VERSION "dbc-export 1 2025.20.8"

NS_ :

BS_:

BU_: ADSP APB APP APS APSB BB BMS CC CMP CMPD CP DAS DI DIF DIR DPB EPAS3P EPAS3S EPASTP EPASTS EPBL EPBR ESP EVSE FC GTW HCML HCMR HVP IBST ICR IDB LS OCS1P PARK PCS PM PMF PMR PNCD PTC RADC RCM RCM2 RCM3 RCU SCCM SCM SCS SDCR TAS TCU TPMS TRCM UI UIS UMC USM VC VCFRONT VCLEFT VCRIGHT VCSEC VEH

BO_ 1480 EPBL_alertLog: 8 EPBL
 SG_ EPBL_alertID M : 0|9@1+ (1,0) [0|511] "" Vector__XXX
 SG_ EPBL_alertState : 15|1@1+ (1,0) [0|1] "" Vector__XXX
 SG_ EPBL_a001_InternalWatchdog m1 : 16|1@1+ (1,0) [0|1] "" Vector__XXX
 SG_ EPBL_a002_CPUUndervoltage m2 : 16|1@1+ (1,0) [0|1] "" Vector__XXX
 SG_ EPBL_a002_PowerOnReset m2 : 17|1@1+ (1,0) [0|1] "" Vector__XXX
 SG_ EPBL_a015_NVMMMemOverflow m15 : 16|1@1+ (1,0) [0|1] "" Vector__XXX
 SG_ EPBL_a015_NVMMFilesystemError m15 : 17|1@1+ (1,0) [0|1] "" Vector__XXX
 SG_ EPBL_a015_NVMMRecordIDError m15 : 18|1@1+ (1,0) [0|1] "" Vector__XXX
 SG_ EPBL_a057_VEH_cpControl m57 : 16|1@1+ (1,0) [0|1] "" Vector__XXX
 SG_ EPBL_a059_voltageDrop m59 : 16|12@1+ (0.005443676,0) [0|22.29185322] "" Vector__XXX
 SG_ EPBL_a059_resistanceEstimate m59 : 28|12@1+ (0.00244,0) [0|9.9918] "" Vector__XXX
 SG_ EPBL_a059_current m59 : 40|12@1+ (0.05,0) [0|204.75] "" Vector__XXX
 SG_ EPBL_a063_switchChannel m63 : 16|8@1+ (1,0) [0|255] "" Vector__XXX
 SG_ EPBL_a063_switchType m63 : 24|8@1+ (1,0) [0|255] "" Vector__XXX
 SG_ EPBL_a063_ADCVoltage m63 : 32|8@1+ (0.025,0) [0|6.375] "" Vector__XXX
 SG_ EPBL_a063_disconnected m63 : 40|1@1+ (1,0) [0|1] "" Vector__XXX
 SG_ EPBL_a063_indeterminate m63 : 41|1@1+ (1,0) [0|1] "" Vector__XXX
 SG_ EPBL_a063_stuckActive m63 : 42|1@1+ (1,0) [0|1] "" Vector__XXX
 SG_ EPBL_a063_faulted m63 : 43|1@1+ (1,0) [0|1] "" Vector__XXX
 SG_ EPBL_a081_VEH_defogInfoMessage m81 : 16|1@1+ (1,0) [0|1] "" Vector__XXX
 SG_ EPBL_a082_RIPC_epbPrivateState m82 : 16|1@1+ (1,0) [0|1] "" Vector__XXX
 SG_ EPBL_a082_RIPC_remoteHSD m82 : 17|1@1+ (1,0) [0|1] "" Vector__XXX
 SG_ EPBL_a082_RIPC_railStatus m82 : 18|1@1+ (1,0) [0|1] "" Vector__XXX
 SG_ EPBL_a082_RIPC_remoteMux m82 : 19|1@1+ (1,0) [0|1] "" Vector__XXX
 SG_ EPBL_a082_RIPC_remoteCurrent m82 : 20|1@1+ (1,0) [0|1] "" Vector__XXX
 SG_ EPBL_a083_LIPC_epbPrivateState m83 : 16|1@1+ (1,0) [0|1] "" Vector__XXX
 SG_ EPBL_a083_LIPC_remoteHSD m83 : 17|1@1+ (1,0) [0|1] "" Vector__XXX
 SG_ EPBL_a083_LIPC_railStatus m83 : 18|1@1+ (1,0) [0|1] "" Vector__XXX
 SG_ EPBL_a083_LIPC_HSDFaults m83 : 19|1@1+ (1,0) [0|1] "" Vector__XXX
 SG_ EPBL_a083_LIPC_remoteCurrent m83 : 20|1@1+ (1,0) [0|1] "" Vector__XXX
 SG_ EPBL_a084_CH_StatusC m84 : 16|1@1+ (1,0) [0|1] "" Vector__XXX
 SG_ EPBL_a085_PARTY_buttonStatus m85 : 16|1@1+ (1,0) [0|1] "" Vector__XXX
 SG_ EPBL_a086_VEH_LVBMS_statusHigh m86 : 16|1@1+ (1,0) [0|1] "" Vector__XXX
 SG_ EPBL_a086_VEH_LVBMS_statusLow m86 : 17|1@1+ (1,0) [0|1] "" Vector__XXX
 SG_ EPBL_a086_VEH_status m86 : 18|1@1+ (1,0) [0|1] "" Vector__XXX
 SG_ EPBL_a086_VEH_12VBatteryStatus m86 : 19|1@1+ (1,0) [0|1] "" Vector__XXX
 SG_ EPBL_a086_VEH_LVPowerState m86 : 20|1@1+ (1,0) [0|1] "" Vector__XXX
 SG_ EPBL_a086_VEH_lightStatus m86 : 21|1@1+ (1,0) [0|1] "" Vector__XXX
 SG_ EPBL_a086_VEH_systemStatus m86 : 22|1@1+ (1,0) [0|1] "" Vector__XXX
 SG_ EPBL_a086_VEH_thermalStatus m86 : 23|1@1+ (1,0) [0|1] "" Vector__XXX
 SG_ EPBL_a086_VEH_vehNm m86 : 24|1@1+ (1,0) [0|1] "" Vector__XXX
 SG_ EPBL_a087_VEH_temperature m87 : 16|1@1+ (1,0) [0|1] "" Vector__XXX
 SG_ EPBL_a087_VEH_thermalControl m87 : 17|1@1+ (1,0) [0|1] "" Vector__XXX
 SG_ EPBL_a087_VEH_torque m87 : 18|1@1+ (1,0) [0|1] "" Vector__XXX
 SG_ EPBL_a087_VEH_status m87 : 19|1@1+ (1,0) [0|1] "" Vector__XXX
 SG_ EPBL_a087_PARTY_torque m87 : 20|1@1+ (1,0) [0|1] "" Vector__XXX
 SG_ EPBL_a087_PARTY_status m87 : 21|1@1+ (1,0) [0|1] "" Vector__XXX
 SG_ EPBL_a087_PARTY_temperature m87 : 22|1@1+ (1,0) [0|1] "" Vector__XXX
 SG_ EPBL_a087_PARTY_thermalControl m87 : 23|1@1+ (1,0) [0|1] "" Vector__XXX
 SG_ EPBL_a088_VEH_temperature m88 : 16|1@1+ (1,0) [0|1] "" Vector__XXX
 SG_ EPBL_a088_VEH_thermalControl m88 : 17|1@1+ (1,0) [0|1] "" Vector__XXX
 SG_ EPBL_a088_VEH_torque m88 : 18|1@1+ (1,0) [0|1] "" Vector__XXX
 SG_ EPBL_a088_VEH_status m88 : 19|1@1+ (1,0) [0|1] "" Vector__XXX
 SG_ EPBL_a088_PARTY_torque m88 : 20|1@1+ (1,0) [0|1] "" Vector__XXX
 SG_ EPBL_a088_PARTY_status m88 : 21|1@1+ (1,0) [0|1] "" Vector__XXX
 SG_ EPBL_a088_PARTY_temperature m88 : 22|1@1+ (1,0) [0|1] "" Vector__XXX
 SG_ EPBL_a088_PARTY_thermalControl m88 : 23|1@1+ (1,0) [0|1] "" Vector__XXX
 SG_ EPBL_a089_PARTY_party1 m89 : 16|1@1+ (1,0) [0|1] "" Vector__XXX
 SG_ EPBL_a089_PARTY_status m89 : 17|1@1+ (1,0) [0|1] "" Vector__XXX
 SG_ EPBL_a089_VEH_status m89 : 18|1@1+ (1,0) [0|1] "" Vector__XXX
 SG_ EPBL_a089_BDY_party1 m89 : 19|1@1+ (1,0) [0|1] "" Vector__XXX
 SG_ EPBL_a089_BDY_status m89 : 20|1@1+ (1,0) [0|1] "" Vector__XXX
 SG_ EPBL_a089_CH_status m89 : 21|1@1+ (1,0) [0|1] "" Vector__XXX
 SG_ EPBL_a089_CH_party1 m89 : 22|1@1+ (1,0) [0|1] "" Vector__XXX
 SG_ EPBL_a089_CH_party3 m89 : 23|1@1+ (1,0) [0|1] "" Vector__XXX
 SG_ EPBL_a089_VEH_party1 m89 : 24|1@1+ (1,0) [0|1] "" Vector__XXX
 SG_ EPBL_a089_VEH_party3 m89 : 25|1@1+ (1,0) [0|1] "" Vector__XXX
 SG_ EPBL_a091_VEH_faultsAndExtras m91 : 16|1@1+ (1,0) [0|1] "" Vector__XXX
 SG_ EPBL_a091_VEH_info m91 : 17|1@1+ (1,0) [0|1] "" Vector__XXX
 SG_ EPBL_a091_VEH_state m91 : 18|1@1+ (1,0) [0|1] "" Vector__XXX
 SG_ EPBL_a092_VEH_restraintStatus m92 : 16|1@1+ (1,0) [0|1] "" Vector__XXX
 SG_ EPBL_a092_VEH_switchStatus m92 : 17|1@1+ (1,0) [0|1] "" Vector__XXX
 SG_ EPBL_a092_VEH_seatStatus2 m92 : 18|1@1+ (1,0) [0|1] "" Vector__XXX
 SG_ EPBL_a092_VEH_vehNm m92 : 19|1@1+ (1,0) [0|1] "" Vector__XXX
 SG_ EPBL_a093_VEH_restraintStatus m93 : 16|1@1+ (1,0) [0|1] "" Vector__XXX
 SG_ EPBL_a093_VEH_switchStatus m93 : 17|1@1+ (1,0) [0|1] "" Vector__XXX
 SG_ EPBL_a093_VEH_seatStatus2 m93 : 18|1@1+ (1,0) [0|1] "" Vector__XXX
 SG_ EPBL_a093_VEH_vehNm m93 : 19|1@1+ (1,0) [0|1] "" Vector__XXX
 SG_ EPBL_a094_VEH_sysStatus m94 : 16|1@1+ (1,0) [0|1] "" Vector__XXX
 SG_ EPBL_a094_PARTY_sysStatus m94 : 17|1@1+ (1,0) [0|1] "" Vector__XXX
 SG_ EPBL_a095_PT_ptNm m95 : 16|1@1+ (1,0) [0|1] "" Vector__XXX
 SG_ EPBL_a095_PT_status m95 : 17|1@1+ (1,0) [0|1] "" Vector__XXX
 SG_ EPBL_a096_VEH_status m96 : 16|1@1+ (1,0) [0|1] "" Vector__XXX
 SG_ EPBL_a096_CH_status m96 : 17|1@1+ (1,0) [0|1] "" Vector__XXX
 SG_ EPBL_a098_CH_torque m98 : 16|1@1+ (1,0) [0|1] "" Vector__XXX
 SG_ EPBL_a098_VEH_hvStatus m98 : 17|1@1+ (1,0) [0|1] "" Vector__XXX
 SG_ EPBL_a098_VEH_status m98 : 18|1@1+ (1,0) [0|1] "" Vector__XXX
 SG_ EPBL_a098_VEH_thermalControl m98 : 19|1@1+ (1,0) [0|1] "" Vector__XXX
 SG_ EPBL_a098_VEH_temperature m98 : 20|1@1+ (1,0) [0|1] "" Vector__XXX
 SG_ EPBL_a098_VEH_torque m98 : 21|1@1+ (1,0) [0|1] "" Vector__XXX
 SG_ EPBL_a098_PARTY_status m98 : 22|1@1+ (1,0) [0|1] "" Vector__XXX
 SG_ EPBL_a098_PARTY_temperature m98 : 23|1@1+ (1,0) [0|1] "" Vector__XXX
 SG_ EPBL_a098_PARTY_thermalControl m98 : 24|1@1+ (1,0) [0|1] "" Vector__XXX
 SG_ EPBL_a098_PARTY_torque m98 : 25|1@1+ (1,0) [0|1] "" Vector__XXX
 SG_ EPBL_a098_PT_thermalControl m98 : 26|1@1+ (1,0) [0|1] "" Vector__XXX
 SG_ EPBL_a098_PT_temperature m98 : 27|1@1+ (1,0) [0|1] "" Vector__XXX
 SG_ EPBL_a099_VEH_oocStatus m99 : 16|1@1+ (1,0) [0|1] "" Vector__XXX
 SG_ EPBL_a100_VEH m100 : 16|1@1+ (1,0) [0|1] "" Vector__XXX
 SG_ EPBL_a100_PARTY m100 : 17|1@1+ (1,0) [0|1] "" Vector__XXX
 SG_ EPBL_a100_PT m100 : 18|1@1+ (1,0) [0|1] "" Vector__XXX
 SG_ EPBL_a100_CH m100 : 19|1@1+ (1,0) [0|1] "" Vector__XXX
 SG_ EPBL_a100_OBD m100 : 20|1@1+ (1,0) [0|1] "" Vector__XXX
 SG_ EPBL_a101_VEH_state m101 : 16|1@1+ (1,0) [0|1] "" Vector__XXX
 SG_ EPBL_a101_PARTY_locState m101 : 17|1@1+ (1,0) [0|1] "" Vector__XXX
 SG_ EPBL_a101_LIPC_externalWatchdogH m101 : 18|1@1+ (1,0) [0|1] "" Vector__XXX
 SG_ EPBL_a101_VEH_locState m101 : 19|1@1+ (1,0) [0|1] "" Vector__XXX
 SG_ EPBL_a101_BDY_locState m101 : 20|1@1+ (1,0) [0|1] "" Vector__XXX
 SG_ EPBL_a102_VEH_faultsAndExtras m102 : 16|1@1+ (1,0) [0|1] "" Vector__XXX
 SG_ EPBL_a102_VEH_feedbackStatus m102 : 17|1@1+ (1,0) [0|1] "" Vector__XXX
 SG_ EPBL_a102_VEH_sensorStatus m102 : 18|1@1+ (1,0) [0|1] "" Vector__XXX
 SG_ EPBL_a102_VEH_rods m102 : 19|1@1+ (1,0) [0|1] "" Vector__XXX
 SG_ EPBL_a103_VEH_hvsNm m103 : 16|1@1+ (1,0) [0|1] "" Vector__XXX
 SG_ EPBL_a103_VEH_vehNm m103 : 17|1@1+ (1,0) [0|1] "" Vector__XXX
 SG_ EPBL_a103_VEH_status m103 : 18|1@1+ (1,0) [0|1] "" Vector__XXX
 SG_ EPBL_a103_PT_ptNm m103 : 19|1@1+ (1,0) [0|1] "" Vector__XXX
 SG_ EPBL_a103_PT_status m103 : 20|1@1+ (1,0) [0|1] "" Vector__XXX
 SG_ EPBL_a103_VEH_evseStatus m103 : 21|1@1+ (1,0) [0|1] "" Vector__XXX
 SG_ EPBL_a105_VEH_states m105 : 16|1@1+ (1,0) [0|1] "" Vector__XXX
 SG_ EPBL_a105_VEH_chNm m105 : 17|1@1+ (1,0) [0|1] "" Vector__XXX
 SG_ EPBL_a105_VEH_dampingStates m105 : 18|1@1+ (1,0) [0|1] "" Vector__XXX
 SG_ EPBL_a106_VEH_dcdcStatus m106 : 16|1@1+ (1,0) [0|1] "" Vector__XXX
 SG_ EPBL_a106_VEH_thermalControl m106 : 17|1@1+ (1,0) [0|1] "" Vector__XXX
 SG_ EPBL_a106_VEH_thermalInterface m106 : 18|1@1+ (1,0) [0|1] "" Vector__XXX
 SG_ EPBL_a106_VEH_dcdcRailStatus m106 : 19|1@1+ (1,0) [0|1] "" Vector__XXX
 SG_ EPBL_a106_CH_dcdcRailStatus m106 : 20|1@1+ (1,0) [0|1] "" Vector__XXX
 SG_ EPBL_a106_CH_alertMatrix m106 : 21|1@1+ (1,0) [0|1] "" Vector__XXX
 SG_ EPBL_a107_VEH_hvsNm m107 : 16|1@1+ (1,0) [0|1] "" Vector__XXX
 SG_ EPBL_a107_VEH_vehNm m107 : 17|1@1+ (1,0) [0|1] "" Vector__XXX
 SG_ EPBL_a107_VEH_status m107 : 18|1@1+ (1,0) [0|1] "" Vector__XXX
 SG_ EPBL_a107_VEH_thermalStatus m107 : 19|1@1+ (1,0) [0|1] "" Vector__XXX
 SG_ EPBL_a107_VEH_thermalStatus2 m107 : 20|1@1+ (1,0) [0|1] "" Vector__XXX
 SG_ EPBL_a107_VEH_bmbMinMax m107 : 21|1@1+ (1,0) [0|1] "" Vector__XXX
 SG_ EPBL_a107_VEH_powerAvailable m107 : 22|1@1+ (1,0) [0|1] "" Vector__XXX
 SG_ EPBL_a107_PT_ptNm m107 : 23|1@1+ (1,0) [0|1] "" Vector__XXX
 SG_ EPBL_a107_PT_status m107 : 24|1@1+ (1,0) [0|1] "" Vector__XXX
 SG_ EPBL_a107_PT_thermalStatus m107 : 25|1@1+ (1,0) [0|1] "" Vector__XXX
 SG_ EPBL_a107_PT_socStatus m107 : 26|1@1+ (1,0) [0|1] "" Vector__XXX
 SG_ EPBL_a107_VEH_socStatus m107 : 27|1@1+ (1,0) [0|1] "" Vector__XXX
 SG_ EPBL_a107_VEH_packConfig m107 : 28|1@1+ (1,0) [0|1] "" Vector__XXX
 SG_ EPBL_a107_VEH_energyStatus m107 : 29|1@1+ (1,0) [0|1] "" Vector__XXX
 SG_ EPBL_a107_VEH_chargeInfo m107 : 30|1@1+ (1,0) [0|1] "" Vector__XXX
 SG_ EPBL_a108_VEH_hvStatus m108 : 16|1@1+ (1,0) [0|1] "" Vector__XXX
 SG_ EPBL_a108_VEH_temperature m108 : 17|1@1+ (1,0) [0|1] "" Vector__XXX
 SG_ EPBL_a108_VEH_thermalControl m108 : 18|1@1+ (1,0) [0|1] "" Vector__XXX
 SG_ EPBL_a108_VEH_torque m108 : 19|1@1+ (1,0) [0|1] "" Vector__XXX
 SG_ EPBL_a108_VEH_status m108 : 20|1@1+ (1,0) [0|1] "" Vector__XXX
 SG_ EPBL_a108_PARTY_torque m108 : 21|1@1+ (1,0) [0|1] "" Vector__XXX
 SG_ EPBL_a108_PARTY_status m108 : 22|1@1+ (1,0) [0|1] "" Vector__XXX
 SG_ EPBL_a108_PARTY_temperature m108 : 23|1@1+ (1,0) [0|1] "" Vector__XXX
 SG_ EPBL_a108_PARTY_thermalControl m108 : 24|1@1+ (1,0) [0|1] "" Vector__XXX
 SG_ EPBL_a108_PT_temperature m108 : 25|1@1+ (1,0) [0|1] "" Vector__XXX
 SG_ EPBL_a108_PT_thermalControl m108 : 26|1@1+ (1,0) [0|1] "" Vector__XXX
 SG_ EPBL_a109_PARTY_status m109 : 16|1@1+ (1,0) [0|1] "" Vector__XXX
 SG_ EPBL_a109_PARTY_inertial2 m109 : 17|1@1+ (1,0) [0|1] "" Vector__XXX
 SG_ EPBL_a109_PARTY_nearDeploy m109 : 18|1@1+ (1,0) [0|1] "" Vector__XXX
 SG_ EPBL_a109_PARTY_collision m109 : 19|1@1+ (1,0) [0|1] "" Vector__XXX
 SG_ EPBL_a109_VEH_status m109 : 20|1@1+ (1,0) [0|1] "" Vector__XXX
 SG_ EPBL_a109_VEH_imuOffsets m109 : 21|1@1+ (1,0) [0|1] "" Vector__XXX
 SG_ EPBL_a109_PARTY_inertial1 m109 : 22|1@1+ (1,0) [0|1] "" Vector__XXX
 SG_ EPBL_a109_BDY_imuOffsets m109 : 23|1@1+ (1,0) [0|1] "" Vector__XXX
 SG_ EPBL_a109_BDY_inertial1 m109 : 24|1@1+ (1,0) [0|1] "" Vector__XXX
 SG_ EPBL_a109_BDY_inertial2 m109 : 25|1@1+ (1,0) [0|1] "" Vector__XXX
 SG_ EPBL_a109_BDY_status m109 : 26|1@1+ (1,0) [0|1] "" Vector__XXX
 SG_ EPBL_a109_VEH_inertial1 m109 : 27|1@1+ (1,0) [0|1] "" Vector__XXX
 SG_ EPBL_a109_VEH_inertial2 m109 : 28|1@1+ (1,0) [0|1] "" Vector__XXX
 SG_ EPBL_a109_CH_inertial1 m109 : 29|1@1+ (1,0) [0|1] "" Vector__XXX
 SG_ EPBL_a109_CH_inertial2 m109 : 30|1@1+ (1,0) [0|1] "" Vector__XXX
 SG_ EPBL_a109_CH_status m109 : 31|1@1+ (1,0) [0|1] "" Vector__XXX
 SG_ EPBL_a110_VEH_carState m110 : 16|1@1+ (1,0) [0|1] "" Vector__XXX
 SG_ EPBL_a110_VEH_carConfig m110 : 17|1@1+ (1,0) [0|1] "" Vector__XXX
 SG_ EPBL_a110_VEH_time m110 : 18|1@1+ (1,0) [0|1] "" Vector__XXX
 SG_ EPBL_a110_VEH_updateStatus m110 : 19|1@1+ (1,0) [0|1] "" Vector__XXX
 SG_ EPBL_a110_VEH_vehNm m110 : 20|1@1+ (1,0) [0|1] "" Vector__XXX
 SG_ EPBL_a110_VEH_mismatchFault m110 : 21|1@1+ (1,0) [0|1] "" Vector__XXX
 SG_ EPBL_a110_VEH_vin m110 : 22|1@1+ (1,0) [0|1] "" Vector__XXX
 SG_ EPBL_a110_VEH_bmpDebug m110 : 23|1@1+ (1,0) [0|1] "" Vector__XXX
 SG_ EPBL_a110_VEH_gearControl m110 : 24|1@1+ (1,0) [0|1] "" Vector__XXX
 SG_ EPBL_a110_VEH_canLogAvailability m110 : 25|1@1+ (1,0) [0|1] "" Vector__XXX
 SG_ EPBL_a110_CH_airbagCutoffStatus m110 : 26|1@1+ (1,0) [0|1] "" Vector__XXX
 SG_ EPBL_a110_CH_carConfig m110 : 27|1@1+ (1,0) [0|1] "" Vector__XXX
 SG_ EPBL_a110_CH_carState m110 : 28|1@1+ (1,0) [0|1] "" Vector__XXX
 SG_ EPBL_a110_CH_vin m110 : 29|1@1+ (1,0) [0|1] "" Vector__XXX
 SG_ EPBL_a110_CH_chNm m110 : 30|1@1+ (1,0) [0|1] "" Vector__XXX
 SG_ EPBL_a110_CH_epochTimeGtw m110 : 31|1@1+ (1,0) [0|1] "" Vector__XXX
 SG_ EPBL_a111_VEH_internalStatus m111 : 16|1@1+ (1,0) [0|1] "" Vector__XXX
 SG_ EPBL_a111_VEH_status m111 : 17|1@1+ (1,0) [0|1] "" Vector__XXX
 SG_ EPBL_a111_VEH_vehNm m111 : 18|1@1+ (1,0) [0|1] "" Vector__XXX
 SG_ EPBL_a111_RIPC_LVPowerState m111 : 19|1@1+ (1,0) [0|1] "" Vector__XXX
 SG_ EPBL_a111_RIPC_epbPrivateState m111 : 20|1@1+ (1,0) [0|1] "" Vector__XXX
 SG_ EPBL_a111_RIPC_railStatus m111 : 21|1@1+ (1,0) [0|1] "" Vector__XXX
 SG_ EPBL_a111_RIPC_remoteADC m111 : 22|1@1+ (1,0) [0|1] "" Vector__XXX
 SG_ EPBL_a111_RIPC_switchStatus m111 : 23|1@1+ (1,0) [0|1] "" Vector__XXX
 SG_ EPBL_a111_VEH_LVPowerState m111 : 24|1@1+ (1,0) [0|1] "" Vector__XXX
 SG_ EPBL_a111_VEH_seatStatus m111 : 25|1@1+ (1,0) [0|1] "" Vector__XXX
 SG_ EPBL_a111_PARTY_status m111 : 26|1@1+ (1,0) [0|1] "" Vector__XXX
 SG_ EPBL_a111_CH_status m111 : 27|1@1+ (1,0) [0|1] "" Vector__XXX
 SG_ EPBL_a111_VEH_seatStatus3 m111 : 28|1@1+ (1,0) [0|1] "" Vector__XXX
 SG_ EPBL_a112_VEH_internalStatus m112 : 16|1@1+ (1,0) [0|1] "" Vector__XXX
 SG_ EPBL_a112_VEH_status m112 : 17|1@1+ (1,0) [0|1] "" Vector__XXX
 SG_ EPBL_a112_VEH_vehNm m112 : 18|1@1+ (1,0) [0|1] "" Vector__XXX
 SG_ EPBL_a112_LIPC_LVPowerState m112 : 19|1@1+ (1,0) [0|1] "" Vector__XXX
 SG_ EPBL_a112_LIPC_epbPrivateState m112 : 20|1@1+ (1,0) [0|1] "" Vector__XXX
 SG_ EPBL_a112_LIPC_railStatus m112 : 21|1@1+ (1,0) [0|1] "" Vector__XXX
 SG_ EPBL_a112_LIPC_remoteADC m112 : 22|1@1+ (1,0) [0|1] "" Vector__XXX
 SG_ EPBL_a112_LIPC_switchStatus m112 : 23|1@1+ (1,0) [0|1] "" Vector__XXX
 SG_ EPBL_a112_VEH_LVPowerState m112 : 24|1@1+ (1,0) [0|1] "" Vector__XXX
 SG_ EPBL_a112_PARTY_status m112 : 25|1@1+ (1,0) [0|1] "" Vector__XXX
 SG_ EPBL_a112_CH_status m112 : 26|1@1+ (1,0) [0|1] "" Vector__XXX
 SG_ EPBL_a114_PARTY_status m114 : 16|1@1+ (1,0) [0|1] "" Vector__XXX
 SG_ EPBL_a114_PARTY_wheelSpeeds m114 : 17|1@1+ (1,0) [0|1] "" Vector__XXX
 SG_ EPBL_a114_VEH_wheelSpeeds m114 : 18|1@1+ (1,0) [0|1] "" Vector__XXX
 SG_ EPBL_a114_CH_wheelSpeeds m114 : 19|1@1+ (1,0) [0|1] "" Vector__XXX
 SG_ EPBL_a114_PARTY_party3 m114 : 20|1@1+ (1,0) [0|1] "" Vector__XXX
 SG_ EPBL_a114_VEH_party3 m114 : 21|1@1+ (1,0) [0|1] "" Vector__XXX
 SG_ EPBL_a114_VEH_status m114 : 22|1@1+ (1,0) [0|1] "" Vector__XXX
 SG_ EPBL_a114_PARTY_wheelRotation m114 : 23|1@1+ (1,0) [0|1] "" Vector__XXX
 SG_ EPBL_a114_CH_wheelRotation m114 : 24|1@1+ (1,0) [0|1] "" Vector__XXX
 SG_ EPBL_a114_VEH_wheelRotation m114 : 25|1@1+ (1,0) [0|1] "" Vector__XXX
 SG_ EPBL_a114_PARTY_brakeTorque m114 : 26|1@1+ (1,0) [0|1] "" Vector__XXX
 SG_ EPBL_a114_PARTY_offsets m114 : 27|1@1+ (1,0) [0|1] "" Vector__XXX
 SG_ EPBL_a114_BDY_offsets m114 : 28|1@1+ (1,0) [0|1] "" Vector__XXX
 SG_ EPBL_a114_BDY_party3 m114 : 29|1@1+ (1,0) [0|1] "" Vector__XXX
 SG_ EPBL_a114_BDY_status m114 : 30|1@1+ (1,0) [0|1] "" Vector__XXX
 SG_ EPBL_a114_BDY_wheelRotation m114 : 31|1@1+ (1,0) [0|1] "" Vector__XXX
 SG_ EPBL_a114_BDY_wheelSpeeds m114 : 32|1@1+ (1,0) [0|1] "" Vector__XXX
 SG_ EPBL_a114_CH_party1 m114 : 33|1@1+ (1,0) [0|1] "" Vector__XXX
 SG_ EPBL_a114_CH_party3 m114 : 34|1@1+ (1,0) [0|1] "" Vector__XXX
 SG_ EPBL_a114_CH_status m114 : 35|1@1+ (1,0) [0|1] "" Vector__XXX
 SG_ EPBL_a115_VEH_vehNm m115 : 16|1@1+ (1,0) [0|1] "" Vector__XXX
 SG_ EPBL_a115_VEH_authentication m115 : 17|1@1+ (1,0) [0|1] "" Vector__XXX
 SG_ EPBL_a115_VEH_BLEResetRequest m115 : 18|1@1+ (1,0) [0|1] "" Vector__XXX
 SG_ EPBL_a115_VEH_requests m115 : 19|1@1+ (1,0) [0|1] "" Vector__XXX
 SG_ EPBL_a115_VEH_requests2 m115 : 20|1@1+ (1,0) [0|1] "" Vector__XXX
 SG_ EPBL_a115_REM_authentication m115 : 21|1@1+ (1,0) [0|1] "" Vector__XXX
 SG_ EPBL_a115_UI_corianderVehicleCon m115 : 22|1@1+ (1,0) [0|1] "" Vector__XXX
 SG_ EPBL_a115_CH_TPMSDisplay m115 : 23|1@1+ (1,0) [0|1] "" Vector__XXX
 SG_ EPBL_a116_PARTY_epbmStatus m116 : 16|1@1+ (1,0) [0|1] "" Vector__XXX
 SG_ EPBL_a116_VEH_vehNm m116 : 17|1@1+ (1,0) [0|1] "" Vector__XXX
 SG_ EPBL_a116_VEH_hvacRequest m116 : 18|1@1+ (1,0) [0|1] "" Vector__XXX
 SG_ EPBL_a116_VEH_hvacStatus m116 : 19|1@1+ (1,0) [0|1] "" Vector__XXX
 SG_ EPBL_a116_VEH_LVPowerState m116 : 20|1@1+ (1,0) [0|1] "" Vector__XXX
 SG_ EPBL_a116_VEH_lightStatus m116 : 21|1@1+ (1,0) [0|1] "" Vector__XXX
 SG_ EPBL_a116_VEH_seatStatus m116 : 22|1@1+ (1,0) [0|1] "" Vector__XXX
 SG_ EPBL_a116_VEH_thsStatus m116 : 23|1@1+ (1,0) [0|1] "" Vector__XXX
 SG_ EPBL_a116_VEH_doorStatus m116 : 24|1@1+ (1,0) [0|1] "" Vector__XXX
 SG_ EPBL_a116_VEH_seatHeatStatus m116 : 25|1@1+ (1,0) [0|1] "" Vector__XXX
 SG_ EPBL_a116_VEH_restraintStatus m116 : 26|1@1+ (1,0) [0|1] "" Vector__XXX
 SG_ EPBL_a116_VEH_switchStatus m116 : 27|1@1+ (1,0) [0|1] "" Vector__XXX
 SG_ EPBL_a116_VEH_logging1Hz m116 : 28|1@1+ (1,0) [0|1] "" Vector__XXX
 SG_ EPBL_a116_VEH_seatStatus2 m116 : 29|1@1+ (1,0) [0|1] "" Vector__XXX
 SG_ EPBL_a116_VEH_status m116 : 30|1@1+ (1,0) [0|1] "" Vector__XXX
 SG_ EPBL_a116_VEH_thermalCommand m116 : 31|1@1+ (1,0) [0|1] "" Vector__XXX
 SG_ EPBL_a116_VEH_windowStatus m116 : 32|1@1+ (1,0) [0|1] "" Vector__XXX
 SG_ EPBL_a116_PARTY_restraintStatus m116 : 33|1@1+ (1,0) [0|1] "" Vector__XXX
 SG_ EPBL_a116_PARTY_doorStatus m116 : 34|1@1+ (1,0) [0|1] "" Vector__XXX
 SG_ EPBL_a116_BDY_epbmStatus m116 : 35|1@1+ (1,0) [0|1] "" Vector__XXX
 SG_ EPBL_a116_BDY_restraintStatus m116 : 36|1@1+ (1,0) [0|1] "" Vector__XXX
 SG_ EPBL_a116_VEH_hvacStatus2 m116 : 63|1@1+ (1,0) [0|1] "" Vector__XXX
 SG_ EPBL_a117_BDY_epbmStatus m117 : 16|1@1+ (1,0) [0|1] "" Vector__XXX
 SG_ EPBL_a117_BDY_restraintStatus m117 : 17|1@1+ (1,0) [0|1] "" Vector__XXX
 SG_ EPBL_a117_VEH_prndStatus m117 : 18|1@1+ (1,0) [0|1] "" Vector__XXX
 SG_ EPBL_a117_PARTY_epbmStatus m117 : 19|1@1+ (1,0) [0|1] "" Vector__XXX
 SG_ EPBL_a117_VEH_vehNm m117 : 20|1@1+ (1,0) [0|1] "" Vector__XXX
 SG_ EPBL_a117_VEH_hvacBlowerFdb m117 : 21|1@1+ (1,0) [0|1] "" Vector__XXX
 SG_ EPBL_a117_VEH_LVPowerState m117 : 22|1@1+ (1,0) [0|1] "" Vector__XXX
 SG_ EPBL_a117_VEH_restraintStatus m117 : 23|1@1+ (1,0) [0|1] "" Vector__XXX
 SG_ EPBL_a117_VEH_lightStatus m117 : 24|1@1+ (1,0) [0|1] "" Vector__XXX
 SG_ EPBL_a117_VEH_seatStatus m117 : 25|1@1+ (1,0) [0|1] "" Vector__XXX
 SG_ EPBL_a117_BDY_falconSwitchStatus m117 : 26|1@1+ (1,0) [0|1] "" Vector__XXX
 SG_ EPBL_a117_VEH_doorStatus m117 : 27|1@1+ (1,0) [0|1] "" Vector__XXX
 SG_ EPBL_a117_VEH_doorStatus2 m117 : 28|1@1+ (1,0) [0|1] "" Vector__XXX
 SG_ EPBL_a117_VEH_windowStatus m117 : 29|1@1+ (1,0) [0|1] "" Vector__XXX
 SG_ EPBL_a117_VEH_switchStatus m117 : 30|1@1+ (1,0) [0|1] "" Vector__XXX
 SG_ EPBL_a117_VEH_intrusionSensorSta m117 : 31|1@1+ (1,0) [0|1] "" Vector__XXX
 SG_ EPBL_a117_VEH_liftgateStatus m117 : 32|1@1+ (1,0) [0|1] "" Vector__XXX
 SG_ EPBL_a117_VEH_seatStatus2 m117 : 33|1@1+ (1,0) [0|1] "" Vector__XXX
 SG_ EPBL_a117_PARTY_restraintStatus m117 : 34|1@1+ (1,0) [0|1] "" Vector__XXX
 SG_ EPBL_a117_VEH_thermalStatus m117 : 35|1@1+ (1,0) [0|1] "" Vector__XXX
 SG_ EPBL_a117_PARTY_doorStatus m117 : 36|1@1+ (1,0) [0|1] "" Vector__XXX
 SG_ EPBL_a117_VEH_status m117 : 37|1@1+ (1,0) [0|1] "" Vector__XXX
 SG_ EPBL_a117_PARTY_prndStatus m117 : 38|1@1+ (1,0) [0|1] "" Vector__XXX
 SG_ EPBL_a118_VEH_vehNm m118 : 16|1@1+ (1,0) [0|1] "" Vector__XXX
 SG_ EPBL_a118_VEH_lighting m118 : 17|1@1+ (1,0) [0|1] "" Vector__XXX
 SG_ EPBL_a118_VEH_sensors m118 : 18|1@1+ (1,0) [0|1] "" Vector__XXX
 SG_ EPBL_a118_VEH_status m118 : 19|1@1+ (1,0) [0|1] "" Vector__XXX
 SG_ EPBL_a118_VEH_okToUseHighPwr m118 : 20|1@1+ (1,0) [0|1] "" Vector__XXX
 SG_ EPBL_a118_VEH_LVPowerState m118 : 21|1@1+ (1,0) [0|1] "" Vector__XXX
 SG_ EPBL_a118_VEH_coolant m118 : 22|1@1+ (1,0) [0|1] "" Vector__XXX
 SG_ EPBL_a118_VEH_vehicleStatus m118 : 23|1@1+ (1,0) [0|1] "" Vector__XXX
 SG_ EPBL_a118_VEH_12VBatteryStatus m118 : 24|1@1+ (1,0) [0|1] "" Vector__XXX
 SG_ EPBL_a118_VEH_systemStatus m118 : 25|1@1+ (1,0) [0|1] "" Vector__XXX
 SG_ EPBL_a118_PARTY_LVPowerState m118 : 26|1@1+ (1,0) [0|1] "" Vector__XXX
 SG_ EPBL_a118_PARTY_outputPowerStatu m118 : 27|1@1+ (1,0) [0|1] "" Vector__XXX
 SG_ EPBL_a118_PARTY_vehicleTime m118 : 28|1@1+ (1,0) [0|1] "" Vector__XXX
 SG_ EPBL_a118_VEH_thermalCommand m118 : 29|1@1+ (1,0) [0|1] "" Vector__XXX
 SG_ EPBL_a118_CH_LVPowerState m118 : 30|1@1+ (1,0) [0|1] "" Vector__XXX
 SG_ EPBL_a118_PARTY_sensors m118 : 31|1@1+ (1,0) [0|1] "" Vector__XXX
 SG_ EPBL_a118_CH_sensors m118 : 32|1@1+ (1,0) [0|1] "" Vector__XXX
 SG_ EPBL_a118_VEH_interNodeResistanc m118 : 33|1@1+ (1,0) [0|1] "" Vector__XXX
 SG_ EPBL_a118_CH_lighting m118 : 34|1@1+ (1,0) [0|1] "" Vector__XXX
 SG_ EPBL_a118_VEH_lightStatus m118 : 35|1@1+ (1,0) [0|1] "" Vector__XXX
 SG_ EPBL_a118_PARTY_vehNm m118 : 36|1@1+ (1,0) [0|1] "" Vector__XXX
 SG_ EPBL_a118_CH_12VBatteryStatus m118 : 37|1@1+ (1,0) [0|1] "" Vector__XXX
 SG_ EPBL_a118_CH_LVBMS_statusHigh m118 : 38|1@1+ (1,0) [0|1] "" Vector__XXX
 SG_ EPBL_a118_CH_alertMatrix m118 : 39|1@1+ (1,0) [0|1] "" Vector__XXX
 SG_ EPBL_a118_BDY_outputPowerStatus m118 : 40|1@1+ (1,0) [0|1] "" Vector__XXX
 SG_ EPBL_a118_BDY_vehicleTime m118 : 41|1@1+ (1,0) [0|1] "" Vector__XXX
 SG_ EPBL_a118_PARTY_AP_vehicleState1 m118 : 42|1@1+ (1,0) [0|1] "" Vector__XXX
 SG_ EPBL_a118_BDY_AP_vehicleState1Hz m118 : 43|1@1+ (1,0) [0|1] "" Vector__XXX
 SG_ EPBL_a119_VEH_steerAngle m119 : 16|1@1+ (1,0) [0|1] "" Vector__XXX
 SG_ EPBL_a119_VEH_leftStalk m119 : 17|1@1+ (1,0) [0|1] "" Vector__XXX
 SG_ EPBL_a119_VEH_rightStalk m119 : 18|1@1+ (1,0) [0|1] "" Vector__XXX
 SG_ EPBL_a119_PARTY_rightStalk m119 : 19|1@1+ (1,0) [0|1] "" Vector__XXX
 SG_ EPBL_a119_CH_steerAngle m119 : 20|1@1+ (1,0) [0|1] "" Vector__XXX
 SG_ EPBL_a119_PARTY_steerAngle m119 : 21|1@1+ (1,0) [0|1] "" Vector__XXX
 SG_ EPBL_a120_PARTY_chassisCntl m120 : 16|1@1+ (1,0) [0|1] "" Vector__XXX
 SG_ EPBL_a120_VEH_systemStatus m120 : 17|1@1+ (1,0) [0|1] "" Vector__XXX
 SG_ EPBL_a120_CH_chassisCntl m120 : 18|1@1+ (1,0) [0|1] "" Vector__XXX
 SG_ EPBL_a120_PARTY_systemStatus m120 : 19|1@1+ (1,0) [0|1] "" Vector__XXX
 SG_ EPBL_a120_PARTY_torque m120 : 20|1@1+ (1,0) [0|1] "" Vector__XXX
 SG_ EPBL_a120_VEH_torque m120 : 21|1@1+ (1,0) [0|1] "" Vector__XXX
 SG_ EPBL_a120_PARTY_locStatus m120 : 22|1@1+ (1,0) [0|1] "" Vector__XXX
 SG_ EPBL_a120_PARTY_speed m120 : 23|1@1+ (1,0) [0|1] "" Vector__XXX
 SG_ EPBL_a120_VEH_speed m120 : 24|1@1+ (1,0) [0|1] "" Vector__XXX
 SG_ EPBL_a120_PARTY_status m120 : 25|1@1+ (1,0) [0|1] "" Vector__XXX
 SG_ EPBL_a120_PT_speed m120 : 26|1@1+ (1,0) [0|1] "" Vector__XXX
 SG_ EPBL_a120_PT_systemStatus m120 : 27|1@1+ (1,0) [0|1] "" Vector__XXX
 SG_ EPBL_a120_PARTY_vehicleEstimates m120 : 28|1@1+ (1,0) [0|1] "" Vector__XXX
 SG_ EPBL_a120_VEH_aggregatedAxleSpee m120 : 29|1@1+ (1,0) [0|1] "" Vector__XXX
 SG_ EPBL_a120_PARTY_aggregatedAxleSp m120 : 30|1@1+ (1,0) [0|1] "" Vector__XXX
 SG_ EPBL_a120_VEH_systemPower m120 : 31|1@1+ (1,0) [0|1] "" Vector__XXX
 SG_ EPBL_a120_PT_systemPower m120 : 32|1@1+ (1,0) [0|1] "" Vector__XXX
 SG_ EPBL_a120_PARTY_stalklessInterfa m120 : 33|1@1+ (1,0) [0|1] "" Vector__XXX
 SG_ EPBL_a120_CH_speed m120 : 34|1@1+ (1,0) [0|1] "" Vector__XXX
 SG_ EPBL_a120_VEH_estimatedBrakeTemp m120 : 35|1@1+ (1,0) [0|1] "" Vector__XXX
 SG_ EPBL_a120_PARTY_prndControl m120 : 36|1@1+ (1,0) [0|1] "" Vector__XXX
 SG_ EPBL_a120_PARTY_locStatus2 m120 : 37|1@1+ (1,0) [0|1] "" Vector__XXX
 SG_ EPBL_a120_VEH_chassisCntl m120 : 38|1@1+ (1,0) [0|1] "" Vector__XXX
 SG_ EPBL_a120_VEH_locStatus m120 : 39|1@1+ (1,0) [0|1] "" Vector__XXX
 SG_ EPBL_a120_VEH_locStatus2 m120 : 40|1@1+ (1,0) [0|1] "" Vector__XXX
 SG_ EPBL_a120_VEH_prndControl m120 : 41|1@1+ (1,0) [0|1] "" Vector__XXX
 SG_ EPBL_a120_VEH_vehicleEstimates m120 : 42|1@1+ (1,0) [0|1] "" Vector__XXX
 SG_ EPBL_a122_filteredCurrentCal m122 : 16|12@1+ (0.01,0) [0|40.95] "" Vector__XXX
 SG_ EPBL_a123_filteredCurrentCal m123 : 16|12@1+ (0.01,0) [0|40.95] "" Vector__XXX
 SG_ EPBL_a124_calOutOfBoundsData m124 : 16|1@1+ (1,0) [0|1] "" Vector__XXX
 SG_ EPBL_a125_pvFilt m125 : 16|12@1+ (0.005443676,0) [0|22.29185322] "" Vector__XXX
 SG_ EPBL_a125_nvFilt m125 : 28|12@1+ (0.005443676,0) [0|22.29185322] "" Vector__XXX
 SG_ EPBL_a125_12vFilt m125 : 40|12@1+ (0.005443676,0) [0|22.29185322] "" Vector__XXX
 SG_ EPBL_a126_pvFilt m126 : 16|12@1+ (0.005443676,0) [0|22.29185322] "" Vector__XXX
 SG_ EPBL_a126_nvFilt m126 : 28|12@1+ (0.005443676,0) [0|22.29185322] "" Vector__XXX
 SG_ EPBL_a126_12vFilt m126 : 40|12@1+ (0.005443676,0) [0|22.29185322] "" Vector__XXX
 SG_ EPBL_a127_pvFilt m127 : 16|12@1+ (0.005443676,0) [0|22.29185322] "" Vector__XXX
 SG_ EPBL_a127_nvFilt m127 : 28|12@1+ (0.005443676,0) [0|22.29185322] "" Vector__XXX
 SG_ EPBL_a127_12vFilt m127 : 40|12@1+ (0.005443676,0) [0|22.29185322] "" Vector__XXX
 SG_ EPBL_a128_pvFilt m128 : 16|12@1+ (0.005443676,0) [0|22.29185322] "" Vector__XXX
 SG_ EPBL_a128_nvFilt m128 : 28|12@1+ (0.005443676,0) [0|22.29185322] "" Vector__XXX
 SG_ EPBL_a128_12vFilt m128 : 40|12@1+ (0.005443676,0) [0|22.29185322] "" Vector__XXX
 SG_ EPBL_a129_VEH_occupancy m129 : 16|1@1+ (1,0) [0|1] "" Vector__XXX
 SG_ EPBL_a130_PARTY_status m130 : 16|1@1+ (1,0) [0|1] "" Vector__XXX
 SG_ EPBL_a130_VEH_status m130 : 17|1@1+ (1,0) [0|1] "" Vector__XXX
 SG_ EPBL_a131_PARTY_actuation m131 : 16|1@1+ (1,0) [0|1] "" Vector__XXX
 SG_ EPBL_a131_CH_actuation m131 : 17|1@1+ (1,0) [0|1] "" Vector__XXX
 SG_ EPBL_a134_pvFilt m134 : 16|12@1+ (0.005443676,0) [0|22.29185322] "" Vector__XXX
 SG_ EPBL_a134_nvFilt m134 : 28|12@1+ (0.005443676,0) [0|22.29185322] "" Vector__XXX
 SG_ EPBL_a134_12vFilt m134 : 40|12@1+ (0.005443676,0) [0|22.29185322] "" Vector__XXX
 SG_ EPBL_a135_pvFilt m135 : 16|12@1+ (0.005443676,0) [0|22.29185322] "" Vector__XXX
 SG_ EPBL_a135_nvFilt m135 : 28|12@1+ (0.005443676,0) [0|22.29185322] "" Vector__XXX
 SG_ EPBL_a135_12vFilt m135 : 40|12@1+ (0.005443676,0) [0|22.29185322] "" Vector__XXX
 SG_ EPBL_a136_pvFilt m136 : 16|12@1+ (0.005443676,0) [0|22.29185322] "" Vector__XXX
 SG_ EPBL_a136_nvFilt m136 : 28|12@1+ (0.005443676,0) [0|22.29185322] "" Vector__XXX
 SG_ EPBL_a136_12vFilt m136 : 40|12@1+ (0.005443676,0) [0|22.29185322] "" Vector__XXX
 SG_ EPBL_a137_pvFilt m137 : 16|12@1+ (0.005443676,0) [0|22.29185322] "" Vector__XXX
 SG_ EPBL_a137_nvFilt m137 : 28|12@1+ (0.005443676,0) [0|22.29185322] "" Vector__XXX
 SG_ EPBL_a137_12vFilt m137 : 40|12@1+ (0.005443676,0) [0|22.29185322] "" Vector__XXX
 SG_ EPBL_a138_localState m138 : 16|3@1+ (1,0) [0|7] "" Vector__XXX
 SG_ EPBL_a138_monitorState m138 : 19|3@1+ (1,0) [0|7] "" Vector__XXX
 SG_ EPBL_a139_localState m139 : 16|3@1+ (1,0) [0|7] "" Vector__XXX
 SG_ EPBL_a139_monitorState m139 : 19|3@1+ (1,0) [0|7] "" Vector__XXX
 SG_ EPBL_a141_fromState m141 : 16|5@1+ (1,0) [0|31] "" Vector__XXX
 SG_ EPBL_a141_toState m141 : 24|5@1+ (1,0) [0|31] "" Vector__XXX
 SG_ EPBL_a170_pvFilt m170 : 16|12@1+ (0.005443676,0) [0|22.29185322] "" Vector__XXX
 SG_ EPBL_a170_nvFilt m170 : 28|12@1+ (0.005443676,0) [0|22.29185322] "" Vector__XXX
 SG_ EPBL_a170_12vFilt m170 : 40|12@1+ (0.005443676,0) [0|22.29185322] "" Vector__XXX
 SG_ EPBL_a171_pvFilt m171 : 16|12@1+ (0.005443676,0) [0|22.29185322] "" Vector__XXX
 SG_ EPBL_a171_nvFilt m171 : 28|12@1+ (0.005443676,0) [0|22.29185322] "" Vector__XXX
 SG_ EPBL_a171_12vFilt m171 : 40|12@1+ (0.005443676,0) [0|22.29185322] "" Vector__XXX
 SG_ EPBL_a174_esmState m174 : 16|5@1+ (1,0) [0|31] "" Vector__XXX
 SG_ EPBL_a174_esmStateRequest m174 : 24|5@1+ (1,0) [0|31] "" Vector__XXX
 SG_ EPBL_a174_faultStatus m174 : 29|2@1+ (1,0) [0|3] "" Vector__XXX
 SG_ EPBL_a174_monitorUnitStatus m174 : 32|5@1+ (1,0) [0|31] "" Vector__XXX
 SG_ EPBL_a174_monitorFaultStatus m174 : 37|2@1+ (1,0) [0|3] "" Vector__XXX
 SG_ EPBL_a174_csmFaultReason m174 : 40|5@1+ (1,0) [0|31] "" Vector__XXX
 SG_ EPBL_a174_esmOpTrigger m174 : 48|6@1+ (1,0) [0|63] "" Vector__XXX
 SG_ EPBL_a174_nonterminalReason m174 : 56|5@1+ (1,0) [0|31] "" Vector__XXX
 SG_ EPBL_a175_esmState m175 : 16|5@1+ (1,0) [0|31] "" Vector__XXX
 SG_ EPBL_a175_esmStateRequest m175 : 24|5@1+ (1,0) [0|31] "" Vector__XXX
 SG_ EPBL_a175_faultStatus m175 : 29|2@1+ (1,0) [0|3] "" Vector__XXX
 SG_ EPBL_a175_monitorUnitStatus m175 : 32|5@1+ (1,0) [0|31] "" Vector__XXX
 SG_ EPBL_a175_monitorFaultStatus m175 : 37|2@1+ (1,0) [0|3] "" Vector__XXX
 SG_ EPBL_a175_csmFaultReason m175 : 40|5@1+ (1,0) [0|31] "" Vector__XXX
 SG_ EPBL_a175_esmOpTrigger m175 : 48|6@1+ (1,0) [0|63] "" Vector__XXX
 SG_ EPBL_a175_nonterminalReason m175 : 56|5@1+ (1,0) [0|31] "" Vector__XXX
 SG_ EPBL_a176_esmState m176 : 16|5@1+ (1,0) [0|31] "" Vector__XXX
 SG_ EPBL_a176_esmStateRequest m176 : 24|5@1+ (1,0) [0|31] "" Vector__XXX
 SG_ EPBL_a176_faultStatus m176 : 29|2@1+ (1,0) [0|3] "" Vector__XXX
 SG_ EPBL_a176_monitorUnitStatus m176 : 32|5@1+ (1,0) [0|31] "" Vector__XXX
 SG_ EPBL_a176_monitorFaultStatus m176 : 37|2@1+ (1,0) [0|3] "" Vector__XXX
 SG_ EPBL_a176_csmFaultReason m176 : 40|5@1+ (1,0) [0|31] "" Vector__XXX
 SG_ EPBL_a176_esmOpTrigger m176 : 48|6@1+ (1,0) [0|63] "" Vector__XXX
 SG_ EPBL_a176_nonterminalReason m176 : 56|5@1+ (1,0) [0|31] "" Vector__XXX
 SG_ EPBL_a177_esmState m177 : 16|5@1+ (1,0) [0|31] "" Vector__XXX
 SG_ EPBL_a177_esmStateRequest m177 : 24|5@1+ (1,0) [0|31] "" Vector__XXX
 SG_ EPBL_a177_faultStatus m177 : 29|2@1+ (1,0) [0|3] "" Vector__XXX
 SG_ EPBL_a177_monitorUnitStatus m177 : 32|5@1+ (1,0) [0|31] "" Vector__XXX
 SG_ EPBL_a177_monitorFaultStatus m177 : 37|2@1+ (1,0) [0|3] "" Vector__XXX
 SG_ EPBL_a177_csmFaultReason m177 : 40|5@1+ (1,0) [0|31] "" Vector__XXX
 SG_ EPBL_a177_esmOpTrigger m177 : 48|6@1+ (1,0) [0|63] "" Vector__XXX
 SG_ EPBL_a177_nonterminalReason m177 : 56|5@1+ (1,0) [0|31] "" Vector__XXX
 SG_ EPBL_a178_localCaliperState m178 : 16|3@1+ (1,0) [0|7] "" Vector__XXX
 SG_ EPBL_a178_monitorCaliperState m178 : 19|3@1+ (1,0) [0|7] "" Vector__XXX
 SG_ EPBL_a179_esmState m179 : 16|5@1+ (1,0) [0|31] "" Vector__XXX
 SG_ EPBL_a179_esmStateRequest m179 : 24|5@1+ (1,0) [0|31] "" Vector__XXX
 SG_ EPBL_a179_faultStatus m179 : 29|2@1+ (1,0) [0|3] "" Vector__XXX
 SG_ EPBL_a179_monitorUnitStatus m179 : 32|5@1+ (1,0) [0|31] "" Vector__XXX
 SG_ EPBL_a179_monitorFaultStatus m179 : 37|2@1+ (1,0) [0|3] "" Vector__XXX
 SG_ EPBL_a179_csmFaultReason m179 : 40|5@1+ (1,0) [0|31] "" Vector__XXX
 SG_ EPBL_a179_esmOpTrigger m179 : 48|6@1+ (1,0) [0|63] "" Vector__XXX
 SG_ EPBL_a179_nonterminalReason m179 : 56|5@1+ (1,0) [0|31] "" Vector__XXX
 SG_ EPBL_a180_esmOpTrigger m180 : 16|6@1+ (1,0) [0|63] "" Vector__XXX
 SG_ EPBL_a180_previousState m180 : 24|5@1+ (1,0) [0|31] "" Vector__XXX
 SG_ EPBL_a180_nextState m180 : 32|5@1+ (1,0) [0|31] "" Vector__XXX
 SG_ EPBL_a180_panicModeLatched m180 : 37|1@1+ (1,0) [0|1] "" Vector__XXX
 SG_ EPBL_a180_activeDecelRequest m180 : 38|1@1+ (1,0) [0|1] "" Vector__XXX
 SG_ EPBL_a181_grade m181 : 16|7@1- (1,0) [-64|63] "" Vector__XXX
 SG_ EPBL_a181_vcTrailerDetected m181 : 23|1@1+ (1,0) [0|1] "" Vector__XXX
 SG_ EPBL_a181_uiTrailerDetected m181 : 24|1@1+ (1,0) [0|1] "" Vector__XXX
 SG_ EPBL_a181_trailerDetected m181 : 25|1@1+ (1,0) [0|1] "" Vector__XXX
 SG_ EPBL_a182_epbSystemStatus m182 : 16|4@1+ (1,0) [0|15] "" Vector__XXX
 SG_ EPBL_a182_grade m182 : 24|7@1- (1,0) [-64|63] "" Vector__XXX
 SG_ EPBL_a182_temperature m182 : 32|8@1+ (0.5,-40) [-40|87.5] "" Vector__XXX
 SG_ EPBL_a182_vcTrailerDetected m182 : 40|1@1+ (1,0) [0|1] "" Vector__XXX
 SG_ EPBL_a182_uiTrailerDetected m182 : 41|1@1+ (1,0) [0|1] "" Vector__XXX
 SG_ EPBL_a182_trailerDetected m182 : 42|1@1+ (1,0) [0|1] "" Vector__XXX
 SG_ EPBL_a183_isRetransmit m183 : 16|1@1+ (1,0) [0|1] "" Vector__XXX
 SG_ EPBL_a183_localCdpState m183 : 17|2@1+ (1,0) [0|3] "" Vector__XXX
 SG_ EPBL_a183_remoteCdpState m183 : 19|2@1+ (1,0) [0|3] "" Vector__XXX
 SG_ EPBL_a183_espCdpStatus m183 : 21|2@1+ (1,0) [0|3] "" Vector__XXX
 SG_ EPBL_a183_esmState m183 : 24|5@1+ (1,0) [0|31] "" Vector__XXX
 SG_ EPBL_a183_esmStateRequest m183 : 32|5@1+ (1,0) [0|31] "" Vector__XXX
 SG_ EPBL_a183_esmOperationTrigger m183 : 40|6@1+ (1,0) [0|63] "" Vector__XXX
 SG_ EPBL_a183_cdpNotStopping m183 : 46|1@1+ (1,0) [0|1] "" Vector__XXX
 SG_ EPBL_a183_cdpNotStarting m183 : 47|1@1+ (1,0) [0|1] "" Vector__XXX
 SG_ EPBL_a183_remoteEpbDynamic m183 : 48|1@1+ (1,0) [0|1] "" Vector__XXX
 SG_ EPBL_a183_localEpbDynamic m183 : 49|1@1+ (1,0) [0|1] "" Vector__XXX
 SG_ EPBL_a183_epbmInvalidated m183 : 50|1@1+ (1,0) [0|1] "" Vector__XXX
 SG_ EPBL_a183_espConfirmedInvalid m183 : 51|1@1+ (1,0) [0|1] "" Vector__XXX
 SG_ EPBL_a183_brakeFluidConfirmedLow m183 : 52|1@1+ (1,0) [0|1] "" Vector__XXX
 SG_ EPBL_a183_lastRemoteEpbDynamic m183 : 53|1@1+ (1,0) [0|1] "" Vector__XXX
 SG_ EPBL_a183_lastLocalEpbDynamic m183 : 54|1@1+ (1,0) [0|1] "" Vector__XXX
 SG_ EPBL_a183_cdpCannotBeCommanded m183 : 55|1@1+ (1,0) [0|1] "" Vector__XXX
 SG_ EPBL_a183_remoteEpbStatusUnsure m183 : 56|1@1+ (1,0) [0|1] "" Vector__XXX
 SG_ EPBL_a183_lastLowBrakeFluid m183 : 57|1@1+ (1,0) [0|1] "" Vector__XXX
 SG_ EPBL_a183_espInvalidOrUnsure m183 : 58|1@1+ (1,0) [0|1] "" Vector__XXX
 SG_ EPBL_a183_lastFactoryMode m183 : 59|1@1+ (1,0) [0|1] "" Vector__XXX
 SG_ EPBL_a183_redundantBrakingEnable m183 : 60|1@1+ (1,0) [0|1] "" Vector__XXX
 SG_ EPBL_a184_esmOpTrigger m184 : 16|6@1+ (1,0) [0|63] "" Vector__XXX
 SG_ EPBL_a184_previousState m184 : 24|5@1+ (1,0) [0|31] "" Vector__XXX
 SG_ EPBL_a184_nextState m184 : 32|5@1+ (1,0) [0|31] "" Vector__XXX
 SG_ EPBL_a184_panicModeLatched m184 : 37|1@1+ (1,0) [0|1] "" Vector__XXX
 SG_ EPBL_a184_activeDecelRequest m184 : 38|1@1+ (1,0) [0|1] "" Vector__XXX
 SG_ EPBL_a187_esmOpTrigger m187 : 16|6@1+ (1,0) [0|63] "" Vector__XXX
 SG_ EPBL_a187_previousState m187 : 24|5@1+ (1,0) [0|31] "" Vector__XXX
 SG_ EPBL_a187_nextState m187 : 32|5@1+ (1,0) [0|31] "" Vector__XXX
 SG_ EPBL_a187_panicModeLatched m187 : 37|1@1+ (1,0) [0|1] "" Vector__XXX
 SG_ EPBL_a187_activeDecelRequest m187 : 38|1@1+ (1,0) [0|1] "" Vector__XXX
 SG_ EPBL_a188_esmOpTrigger m188 : 16|6@1+ (1,0) [0|63] "" Vector__XXX
 SG_ EPBL_a188_previousState m188 : 24|5@1+ (1,0) [0|31] "" Vector__XXX
 SG_ EPBL_a188_nextState m188 : 32|5@1+ (1,0) [0|31] "" Vector__XXX
 SG_ EPBL_a188_panicModeLatched m188 : 37|1@1+ (1,0) [0|1] "" Vector__XXX
 SG_ EPBL_a188_activeDecelRequest m188 : 38|1@1+ (1,0) [0|1] "" Vector__XXX
 SG_ EPBL_a189_esmOpTrigger m189 : 16|6@1+ (1,0) [0|63] "" Vector__XXX
 SG_ EPBL_a189_previousState m189 : 24|5@1+ (1,0) [0|31] "" Vector__XXX
 SG_ EPBL_a189_nextState m189 : 32|5@1+ (1,0) [0|31] "" Vector__XXX
 SG_ EPBL_a189_panicModeLatched m189 : 37|1@1+ (1,0) [0|1] "" Vector__XXX
 SG_ EPBL_a189_activeDecelRequest m189 : 38|1@1+ (1,0) [0|1] "" Vector__XXX
 SG_ EPBL_a190_esmState m190 : 16|5@1+ (1,0) [0|31] "" Vector__XXX
 SG_ EPBL_a190_esmStateRequest m190 : 24|5@1+ (1,0) [0|31] "" Vector__XXX
 SG_ EPBL_a190_faultStatus m190 : 29|2@1+ (1,0) [0|3] "" Vector__XXX
 SG_ EPBL_a190_monitorUnitStatus m190 : 32|5@1+ (1,0) [0|31] "" Vector__XXX
 SG_ EPBL_a190_monitorFaultStatus m190 : 37|2@1+ (1,0) [0|3] "" Vector__XXX
 SG_ EPBL_a190_csmFaultReason m190 : 40|5@1+ (1,0) [0|31] "" Vector__XXX
 SG_ EPBL_a190_esmOpTrigger m190 : 48|6@1+ (1,0) [0|63] "" Vector__XXX
 SG_ EPBL_a190_nonterminalReason m190 : 56|5@1+ (1,0) [0|31] "" Vector__XXX
 SG_ EPBL_a191_esmState m191 : 16|5@1+ (1,0) [0|31] "" Vector__XXX
 SG_ EPBL_a191_esmStateRequest m191 : 24|5@1+ (1,0) [0|31] "" Vector__XXX
 SG_ EPBL_a191_faultStatus m191 : 29|2@1+ (1,0) [0|3] "" Vector__XXX
 SG_ EPBL_a191_monitorUnitStatus m191 : 32|5@1+ (1,0) [0|31] "" Vector__XXX
 SG_ EPBL_a191_monitorFaultStatus m191 : 37|2@1+ (1,0) [0|3] "" Vector__XXX
 SG_ EPBL_a191_csmFaultReason m191 : 40|5@1+ (1,0) [0|31] "" Vector__XXX
 SG_ EPBL_a191_esmOpTrigger m191 : 48|6@1+ (1,0) [0|63] "" Vector__XXX
 SG_ EPBL_a191_nonterminalReason m191 : 56|5@1+ (1,0) [0|31] "" Vector__XXX
 SG_ EPBL_a202_localEpbConfig m202 : 16|4@1+ (1,0) [0|15] "" Vector__XXX
 SG_ EPBL_a202_remoteEpbConfig m202 : 20|4@1+ (1,0) [0|15] "" Vector__XXX
 SG_ EPBL_a203_gtwConfig m203 : 16|4@1+ (1,0) [0|15] "" Vector__XXX
 SG_ EPBL_a203_epbConfig m203 : 20|4@1+ (1,0) [0|15] "" Vector__XXX
 SG_ EPBL_a210_driverLeftForScore m210 : 16|1@1+ (1,0) [0|1] "" Vector__XXX
 SG_ EPBL_a210_driverLeftForAllSensor m210 : 17|1@1+ (1,0) [0|1] "" Vector__XXX
 SG_ EPBL_a210_driverLeftForDoorOpen m210 : 18|1@1+ (1,0) [0|1] "" Vector__XXX
 SG_ EPBL_a210_driverLeftForUnbuckled m210 : 19|1@1+ (1,0) [0|1] "" Vector__XXX
 SG_ EPBL_a210_driverLeftForInactivit m210 : 20|1@1+ (1,0) [0|1] "" Vector__XXX
 SG_ EPBL_a210_driverIsLeavingSpeedCl m210 : 21|3@1+ (1,0) [0|7] "" Vector__XXX
 SG_ EPBL_a210_localDriverIsLeaving m210 : 24|1@1+ (1,0) [0|1] "" Vector__XXX
 SG_ EPBL_a210_localDriverIsLeavingAn m210 : 25|1@1+ (1,0) [0|1] "" Vector__XXX
 SG_ EPBL_a210_remoteDriverIsLeaving m210 : 26|1@1+ (1,0) [0|1] "" Vector__XXX
 SG_ EPBL_a210_remoteDriverIsLeavingA m210 : 27|1@1+ (1,0) [0|1] "" Vector__XXX
 SG_ EPBL_a210_primaryDriverDoorClose m210 : 28|2@1+ (1,0) [0|3] "" Vector__XXX
 SG_ EPBL_a210_secondaryDriverDoorClo m210 : 30|2@1+ (1,0) [0|3] "" Vector__XXX
 SG_ EPBL_a210_driverBuckled m210 : 32|2@1+ (1,0) [0|3] "" Vector__XXX
 SG_ EPBL_a210_driverSeated m210 : 34|2@1+ (1,0) [0|3] "" Vector__XXX
 SG_ EPBL_a225_esmOpTrigger m225 : 16|6@1+ (1,0) [0|63] "" Vector__XXX
 SG_ EPBL_a225_previousState m225 : 24|5@1+ (1,0) [0|31] "" Vector__XXX
 SG_ EPBL_a225_nextState m225 : 32|5@1+ (1,0) [0|31] "" Vector__XXX
 SG_ EPBL_a225_panicModeLatched m225 : 37|1@1+ (1,0) [0|1] "" Vector__XXX
 SG_ EPBL_a225_activeDecelRequest m225 : 38|1@1+ (1,0) [0|1] "" Vector__XXX
 SG_ EPBL_a241_desiredState m241 : 16|1@1+ (1,0) [0|1] "" Vector__XXX
 SG_ EPBL_a241_currentState m241 : 17|1@1+ (1,0) [0|1] "" Vector__XXX
 SG_ EPBL_a241_diKeepAlive m241 : 18|1@1+ (1,0) [0|1] "" Vector__XXX
 SG_ EPBL_a241_epbSysStatus m241 : 19|4@1+ (1,0) [0|15] "" Vector__XXX
 SG_ EPBL_a241_vehiclePowerState m241 : 24|2@1+ (1,0) [0|3] "" Vector__XXX
 SG_ EPBL_a241_highCurrent m241 : 26|1@1+ (1,0) [0|1] "" Vector__XXX
 SG_ EPBL_a241_monitorDataGood m241 : 27|1@1+ (1,0) [0|1] "" Vector__XXX
 SG_ EPBL_a241_hasLockoutRequest m241 : 28|1@1+ (1,0) [0|1] "" Vector__XXX
 SG_ EPBL_a242_hvcDesiredState m242 : 16|1@1+ (1,0) [0|1] "" Vector__XXX
 SG_ EPBL_a242_hvcCurrentState m242 : 17|1@1+ (1,0) [0|1] "" Vector__XXX
 SG_ EPBL_a242_contDesiredState m242 : 18|1@1+ (1,0) [0|1] "" Vector__XXX
 SG_ EPBL_a242_contCurrentState m242 : 19|1@1+ (1,0) [0|1] "" Vector__XXX
 SG_ EPBL_a242_hvState m242 : 20|3@1+ (1,0) [0|7] "" Vector__XXX
 SG_ EPBL_a242_vehiclePowerState m242 : 24|2@1+ (1,0) [0|3] "" Vector__XXX
 SG_ EPBL_a242_highCurrent m242 : 26|1@1+ (1,0) [0|1] "" Vector__XXX
 SG_ EPBL_a242_monitorDataGood m242 : 27|1@1+ (1,0) [0|1] "" Vector__XXX
 SG_ EPBL_a242_hasLockoutRequest m242 : 28|1@1+ (1,0) [0|1] "" Vector__XXX
 SG_ EPBL_a243_brakeMasterCylPress m243 : 16|1@1+ (1,0) [0|1] "" Vector__XXX
 SG_ EPBL_a243_brakeMasterCylPressQF m243 : 17|1@1+ (1,0) [0|1] "" Vector__XXX
 SG_ EPBL_a243_drivetrainType m243 : 18|1@1+ (1,0) [0|1] "" Vector__XXX
 SG_ EPBL_a243_DIR1torqueActual m243 : 19|1@1+ (1,0) [0|1] "" Vector__XXX
 SG_ EPBL_a243_DIR2torqueActual m243 : 20|1@1+ (1,0) [0|1] "" Vector__XXX
 SG_ EPBL_a243_DIFtorqueActual m243 : 21|1@1+ (1,0) [0|1] "" Vector__XXX
 SG_ EPBL_a243_vehicleSpeed m243 : 22|1@1+ (1,0) [0|1] "" Vector__XXX
 SG_ EPBL_a243_tempAmbient m243 : 23|1@1+ (1,0) [0|1] "" Vector__XXX
 SG_ EPBL_a243_thermistorTMin m243 : 24|1@1+ (1,0) [0|1] "" Vector__XXX
 SG_ EPBL_a243_wiperSpeed m243 : 25|1@1+ (1,0) [0|1] "" Vector__XXX
 SG_ EPBL_a243_vehiclePowerState m243 : 26|1@1+ (1,0) [0|1] "" Vector__XXX
 SG_ EPBL_a243_brakeDiscWipingActive m243 : 27|1@1+ (1,0) [0|1] "" Vector__XXX
 SG_ EPBL_a244_permissiveMode m244 : 16|1@1+ (1,0) [0|1] "" Vector__XXX
 SG_ EPBL_a246_previousState m246 : 16|5@1+ (1,0) [0|31] "" Vector__XXX
 SG_ EPBL_a246_nextState m246 : 24|5@1+ (1,0) [0|31] "" Vector__XXX
 SG_ EPBL_a246_esmStateRequest m246 : 32|5@1+ (1,0) [0|31] "" Vector__XXX
 SG_ EPBL_a246_faultStatus m246 : 37|2@1+ (1,0) [0|3] "" Vector__XXX
 SG_ EPBL_a246_esmOpTrigger m246 : 40|6@1+ (1,0) [0|63] "" Vector__XXX
 SG_ EPBL_a247_esmState m247 : 16|5@1+ (1,0) [0|31] "" Vector__XXX
 SG_ EPBL_a247_esmStateRequest m247 : 24|5@1+ (1,0) [0|31] "" Vector__XXX
 SG_ EPBL_a247_faultStatus m247 : 29|2@1+ (1,0) [0|3] "" Vector__XXX
 SG_ EPBL_a247_monitorUnitStatus m247 : 32|5@1+ (1,0) [0|31] "" Vector__XXX
 SG_ EPBL_a247_monitorFaultStatus m247 : 37|2@1+ (1,0) [0|3] "" Vector__XXX
 SG_ EPBL_a247_csmFaultReason m247 : 40|5@1+ (1,0) [0|31] "" Vector__XXX
 SG_ EPBL_a247_esmOpTrigger m247 : 48|6@1+ (1,0) [0|63] "" Vector__XXX
 SG_ EPBL_a247_nonterminalReason m247 : 56|5@1+ (1,0) [0|31] "" Vector__XXX
 SG_ EPBL_a248_esmState m248 : 16|5@1+ (1,0) [0|31] "" Vector__XXX
 SG_ EPBL_a248_esmStateRequest m248 : 24|5@1+ (1,0) [0|31] "" Vector__XXX
 SG_ EPBL_a248_faultStatus m248 : 29|2@1+ (1,0) [0|3] "" Vector__XXX
 SG_ EPBL_a248_monitorUnitStatus m248 : 32|5@1+ (1,0) [0|31] "" Vector__XXX
 SG_ EPBL_a248_monitorFaultStatus m248 : 37|2@1+ (1,0) [0|3] "" Vector__XXX
 SG_ EPBL_a248_csmFaultReason m248 : 40|5@1+ (1,0) [0|31] "" Vector__XXX
 SG_ EPBL_a248_esmOpTrigger m248 : 48|6@1+ (1,0) [0|63] "" Vector__XXX
 SG_ EPBL_a248_nonterminalReason m248 : 56|5@1+ (1,0) [0|31] "" Vector__XXX
 SG_ EPBL_a249_previousState m249 : 16|5@1+ (1,0) [0|31] "" Vector__XXX
 SG_ EPBL_a249_nextState m249 : 24|5@1+ (1,0) [0|31] "" Vector__XXX
 SG_ EPBL_a249_esmStateRequest m249 : 32|5@1+ (1,0) [0|31] "" Vector__XXX
 SG_ EPBL_a249_faultStatus m249 : 37|2@1+ (1,0) [0|3] "" Vector__XXX
 SG_ EPBL_a249_esmOpTrigger m249 : 40|6@1+ (1,0) [0|63] "" Vector__XXX
 SG_ EPBL_a250_esmSpeedClass m250 : 16|3@1+ (1,0) [0|7] "" Vector__XXX
 SG_ EPBL_a250_esmOperationTrigger m250 : 24|6@1+ (1,0) [0|63] "" Vector__XXX
 SG_ EPBL_a250_isJumpPostTripped m250 : 30|1@1+ (1,0) [0|1] "" Vector__XXX
 SG_ EPBL_a251_currentVariance m251 : 16|12@1+ (0.01,0) [0|40.95] "" Vector__XXX
 SG_ EPBL_a251_pistonPosition m251 : 32|13@1- (9.76801,0) [-40009.76896|40000.00095] "" Vector__XXX
 SG_ EPBL_a251_temperature m251 : 45|9@1- (0.5,-40) [-168|87.5] "" Vector__XXX
 SG_ EPBL_a272_expectedState m272 : 16|2@1+ (1,0) [0|3] "" Vector__XXX
 SG_ EPBL_a272_actualState m272 : 18|2@1+ (1,0) [0|3] "" Vector__XXX
 SG_ EPBL_a300_harnessId m300 : 16|8@1+ (1,0) [0|255] "" Vector__XXX
 SG_ EPBL_a300_subUsageId m300 : 24|8@1+ (1,0) [0|255] "" Vector__XXX
 SG_ EPBL_a301_setSpeed m301 : 16|16@1+ (0.05,0) [0|3276.75] "" Vector__XXX
 SG_ EPBL_a301_oocConfidence m301 : 32|12@1+ (1,0) [0|4095] "" Vector__XXX
 SG_ EPBL_a301_oocDistanceFiltered m301 : 48|16@1+ (0.01,0) [0|655.35] "" Vector__XXX
 SG_ EPBL_a302_pistonPosition m302 : 16|13@1- (9.76801,0) [-40009.76896|40000.00095] "" Vector__XXX
 SG_ EPBL_a302_deltaCurrent m302 : 32|15@1+ (0.01,0) [0|327.67] "" Vector__XXX
 SG_ EPBL_a303_currentVariance m303 : 16|12@1+ (0.01,0) [0|40.95] "" Vector__XXX
 SG_ EPBL_a303_pistonPosition m303 : 32|13@1- (9.76801,0) [-40009.76896|40000.00095] "" Vector__XXX
 SG_ EPBL_a303_temperature m303 : 45|9@1- (0.5,-40) [-168|87.5] "" Vector__XXX
 SG_ EPBL_a350_ensPeriod m350 : 16|16@1+ (0.0001,0) [0|6.5535] "" Vector__XXX
 SG_ EPBL_a350_ensDuty m350 : 32|10@1+ (0.00098,0) [0|1.00254] "" Vector__XXX
 SG_ EPBL_a350_ensTimedOut m350 : 42|1@1+ (1,0) [0|1] "" Vector__XXX
 SG_ EPBL_a355_brakeHwConfig m355 : 16|4@1+ (1,0) [0|15] "" Vector__XXX
 SG_ EPBL_a355_epbHwConfig m355 : 20|4@1+ (1,0) [0|15] "" Vector__XXX
 SG_ EPBL_a357_epbSystemStatus m357 : 16|4@1+ (1,0) [0|15] "" Vector__XXX
 SG_ EPBL_a357_grade m357 : 24|7@1- (1,0) [-64|63] "" Vector__XXX
 SG_ EPBL_a357_ambientTemp m357 : 32|8@1+ (0.5,-40) [-40|87.5] "" Vector__XXX
 SG_ EPBL_a357_brakeTemp m357 : 40|11@1+ (1,-40) [-40|2007] "" Vector__XXX
 SG_ EPBL_a357_vcTrailerDetected m357 : 51|1@1+ (1,0) [0|1] "" Vector__XXX
 SG_ EPBL_a357_uiTrailerDetected m357 : 52|1@1+ (1,0) [0|1] "" Vector__XXX
 SG_ EPBL_a357_trailerDetected m357 : 53|1@1+ (1,0) [0|1] "" Vector__XXX
 SG_ EPBL_a358_epbSystemStatus m358 : 16|4@1+ (1,0) [0|15] "" Vector__XXX
 SG_ EPBL_a358_grade m358 : 24|7@1- (1,0) [-64|63] "" Vector__XXX
 SG_ EPBL_a358_ambientTemp m358 : 32|8@1+ (0.5,-40) [-40|87.5] "" Vector__XXX
 SG_ EPBL_a358_brakeTemp m358 : 40|11@1+ (1,-40) [-40|2007] "" Vector__XXX
 SG_ EPBL_a358_vcTrailerDetected m358 : 51|1@1+ (1,0) [0|1] "" Vector__XXX
 SG_ EPBL_a358_uiTrailerDetected m358 : 52|1@1+ (1,0) [0|1] "" Vector__XXX
 SG_ EPBL_a358_trailerDetected m358 : 53|1@1+ (1,0) [0|1] "" Vector__XXX
 SG_ EPBL_a365_epbSystemStatus m365 : 16|4@1+ (1,0) [0|15] "" Vector__XXX
 SG_ EPBL_a365_grade m365 : 24|7@1- (1,0) [-64|63] "" Vector__XXX
 SG_ EPBL_a365_ambientTemp m365 : 32|8@1+ (0.5,-40) [-40|87.5] "" Vector__XXX
 SG_ EPBL_a365_vcTrailerDetected m365 : 40|1@1+ (1,0) [0|1] "" Vector__XXX
 SG_ EPBL_a365_uiTrailerDetected m365 : 41|1@1+ (1,0) [0|1] "" Vector__XXX
 SG_ EPBL_a365_trailerDetected m365 : 42|1@1+ (1,0) [0|1] "" Vector__XXX
 SG_ EPBL_a366_epbSystemStatus m366 : 16|4@1+ (1,0) [0|15] "" Vector__XXX
 SG_ EPBL_a366_grade m366 : 24|7@1- (1,0) [-64|63] "" Vector__XXX
 SG_ EPBL_a366_ambientTemp m366 : 32|8@1+ (0.5,-40) [-40|87.5] "" Vector__XXX
 SG_ EPBL_a366_vcTrailerDetected m366 : 40|1@1+ (1,0) [0|1] "" Vector__XXX
 SG_ EPBL_a366_uiTrailerDetected m366 : 41|1@1+ (1,0) [0|1] "" Vector__XXX
 SG_ EPBL_a366_trailerDetected m366 : 42|1@1+ (1,0) [0|1] "" Vector__XXX

BO_ 968 EPBL_alertMatrix: 8 EPBL
 SG_ EPBL_matrixIndex M : 0|4@1+ (1,0) [0|15] "" Vector__XXX
 SG_ EPBL_a001_WatchdogReset m0 : 4|1@1+ (1,0) [0|1] "" Vector__XXX
 SG_ EPBL_a002_PowerLossReset m0 : 5|1@1+ (1,0) [0|1] "" Vector__XXX
 SG_ EPBL_a003_SWAssertion m0 : 6|1@1+ (1,0) [0|1] "" Vector__XXX
 SG_ EPBL_a005_CANTXError m0 : 8|1@1+ (1,0) [0|1] "" Vector__XXX
 SG_ EPBL_a006_CANTX_cyclicError m0 : 9|1@1+ (1,0) [0|1] "" Vector__XXX
 SG_ EPBL_a012_CPUReset m0 : 15|1@1+ (1,0) [0|1] "" Vector__XXX
 SG_ EPBL_a013_AlertManagerFault m0 : 16|1@1+ (1,0) [0|1] "" Vector__XXX
 SG_ EPBL_a015_NVMMError m0 : 18|1@1+ (1,0) [0|1] "" Vector__XXX
 SG_ EPBL_a016_NVMMRecordError m0 : 19|1@1+ (1,0) [0|1] "" Vector__XXX
 SG_ EPBL_a021_TaskSchedulerError m0 : 24|1@1+ (1,0) [0|1] "" Vector__XXX
 SG_ EPBL_a022_TaskInitError m0 : 25|1@1+ (1,0) [0|1] "" Vector__XXX
 SG_ EPBL_a029_CoreDump m0 : 32|1@1+ (1,0) [0|1] "" Vector__XXX
 SG_ EPBL_a030_ECULogUploadRequest m0 : 33|1@1+ (1,0) [0|1] "" Vector__XXX
 SG_ EPBL_a031_UDSActive m0 : 34|1@1+ (1,0) [0|1] "" Vector__XXX
 SG_ EPBL_a041_HighCPULoad m0 : 44|1@1+ (1,0) [0|1] "" Vector__XXX
 SG_ EPBL_a042_HighStackUsage m0 : 45|1@1+ (1,0) [0|1] "" Vector__XXX
 SG_ EPBL_a043_Task1msError m0 : 46|1@1+ (1,0) [0|1] "" Vector__XXX
 SG_ EPBL_a044_Task10msError m0 : 47|1@1+ (1,0) [0|1] "" Vector__XXX
 SG_ EPBL_a045_Task100msError m0 : 48|1@1+ (1,0) [0|1] "" Vector__XXX
 SG_ EPBL_a046_Task1000msError m0 : 49|1@1+ (1,0) [0|1] "" Vector__XXX
 SG_ EPBL_a057_HVP_MIA m0 : 60|1@1+ (1,0) [0|1] "" Vector__XXX
 SG_ EPBL_a058_inputRHighSyncDebug m0 : 61|1@1+ (1,0) [0|1] "" Vector__XXX
 SG_ EPBL_a059_inputResistanceHigh m0 : 62|1@1+ (1,0) [0|1] "" Vector__XXX
 SG_ EPBL_a060_engineeringBuild m0 : 63|1@1+ (1,0) [0|1] "" Vector__XXX
 SG_ EPBL_a061_XCPConnected m1 : 4|1@1+ (1,0) [0|1] "" Vector__XXX
 SG_ EPBL_a062_XCPWasConnected m1 : 5|1@1+ (1,0) [0|1] "" Vector__XXX
 SG_ EPBL_a063_SwitchFault m1 : 6|1@1+ (1,0) [0|1] "" Vector__XXX
 SG_ EPBL_a064_busSleepReqTimeout m1 : 7|1@1+ (1,0) [0|1] "" Vector__XXX
 SG_ EPBL_a081_APP_MIA m1 : 24|1@1+ (1,0) [0|1] "" Vector__XXX
 SG_ EPBL_a082_VCRIGHT_IPC_MIA m1 : 25|1@1+ (1,0) [0|1] "" Vector__XXX
 SG_ EPBL_a083_VCLEFT_IPC_MIA m1 : 26|1@1+ (1,0) [0|1] "" Vector__XXX
 SG_ EPBL_a084_TPMS_MIA m1 : 27|1@1+ (1,0) [0|1] "" Vector__XXX
 SG_ EPBL_a085_CCCM_MIA m1 : 28|1@1+ (1,0) [0|1] "" Vector__XXX
 SG_ EPBL_a086_VCBATT_MIA m1 : 29|1@1+ (1,0) [0|1] "" Vector__XXX
 SG_ EPBL_a087_DIREL_MIA m1 : 30|1@1+ (1,0) [0|1] "" Vector__XXX
 SG_ EPBL_a088_DIRER_MIA m1 : 31|1@1+ (1,0) [0|1] "" Vector__XXX
 SG_ EPBL_a089_IBST_MIA m1 : 32|1@1+ (1,0) [0|1] "" Vector__XXX
 SG_ EPBL_a090_APS_MIA m1 : 33|1@1+ (1,0) [0|1] "" Vector__XXX
 SG_ EPBL_a091_CMPD_MIA m1 : 34|1@1+ (1,0) [0|1] "" Vector__XXX
 SG_ EPBL_a092_VCSEATD_MIA m1 : 35|1@1+ (1,0) [0|1] "" Vector__XXX
 SG_ EPBL_a093_VCSEATP_MIA m1 : 36|1@1+ (1,0) [0|1] "" Vector__XXX
 SG_ EPBL_a094_EPAS3P_MIA m1 : 37|1@1+ (1,0) [0|1] "" Vector__XXX
 SG_ EPBL_a095_CHG_MIA m1 : 38|1@1+ (1,0) [0|1] "" Vector__XXX
 SG_ EPBL_a096_OCS1P_MIA m1 : 39|1@1+ (1,0) [0|1] "" Vector__XXX
 SG_ EPBL_a097_CMP_MIA m1 : 40|1@1+ (1,0) [0|1] "" Vector__XXX
 SG_ EPBL_a098_DIR_MIA m1 : 41|1@1+ (1,0) [0|1] "" Vector__XXX
 SG_ EPBL_a099_PARK_MIA m1 : 42|1@1+ (1,0) [0|1] "" Vector__XXX
 SG_ EPBL_a100_CANbus_MIA m1 : 43|1@1+ (1,0) [0|1] "" Vector__XXX
 SG_ EPBL_a101_PM_MIA m1 : 44|1@1+ (1,0) [0|1] "" Vector__XXX
 SG_ EPBL_a102_PTC_MIA m1 : 45|1@1+ (1,0) [0|1] "" Vector__XXX
 SG_ EPBL_a103_CP_MIA m1 : 46|1@1+ (1,0) [0|1] "" Vector__XXX
 SG_ EPBL_a104_DAS_MIA m1 : 47|1@1+ (1,0) [0|1] "" Vector__XXX
 SG_ EPBL_a105_TAS_MIA m1 : 48|1@1+ (1,0) [0|1] "" Vector__XXX
 SG_ EPBL_a106_PCS_MIA m1 : 49|1@1+ (1,0) [0|1] "" Vector__XXX
 SG_ EPBL_a107_BMS_MIA m1 : 50|1@1+ (1,0) [0|1] "" Vector__XXX
 SG_ EPBL_a108_DIF_MIA m1 : 51|1@1+ (1,0) [0|1] "" Vector__XXX
 SG_ EPBL_a109_RCM_MIA m1 : 52|1@1+ (1,0) [0|1] "" Vector__XXX
 SG_ EPBL_a110_GTW_MIA m1 : 53|1@1+ (1,0) [0|1] "" Vector__XXX
 SG_ EPBL_a111_EPBR_MIA m1 : 54|1@1+ (1,0) [0|1] "" Vector__XXX
 SG_ EPBL_a112_EPBL_MIA m1 : 55|1@1+ (1,0) [0|1] "" Vector__XXX
 SG_ EPBL_a113_UI_MIA m1 : 56|1@1+ (1,0) [0|1] "" Vector__XXX
 SG_ EPBL_a114_ESP_MIA m1 : 57|1@1+ (1,0) [0|1] "" Vector__XXX
 SG_ EPBL_a115_VCSEC_MIA m1 : 58|1@1+ (1,0) [0|1] "" Vector__XXX
 SG_ EPBL_a116_VCRIGHT_MIA m1 : 59|1@1+ (1,0) [0|1] "" Vector__XXX
 SG_ EPBL_a117_VCLEFT_MIA m1 : 60|1@1+ (1,0) [0|1] "" Vector__XXX
 SG_ EPBL_a118_VCFRONT_MIA m1 : 61|1@1+ (1,0) [0|1] "" Vector__XXX
 SG_ EPBL_a119_SCCM_MIA m1 : 62|1@1+ (1,0) [0|1] "" Vector__XXX
 SG_ EPBL_a120_DI_DRIVE_MIA m1 : 63|1@1+ (1,0) [0|1] "" Vector__XXX
 SG_ EPBL_a121_nDriveFault m2 : 4|1@1+ (1,0) [0|1] "" Vector__XXX
 SG_ EPBL_a122_Oc m2 : 5|1@1+ (1,0) [0|1] "" Vector__XXX
 SG_ EPBL_a123_Uc m2 : 6|1@1+ (1,0) [0|1] "" Vector__XXX
 SG_ EPBL_a124_calOutOfBounds m2 : 7|1@1+ (1,0) [0|1] "" Vector__XXX
 SG_ EPBL_a125_IdleVMismatch m2 : 8|1@1+ (1,0) [0|1] "" Vector__XXX
 SG_ EPBL_a126_MotorNVoltLow m2 : 9|1@1+ (1,0) [0|1] "" Vector__XXX
 SG_ EPBL_a127_MotorNVoltHigh m2 : 10|1@1+ (1,0) [0|1] "" Vector__XXX
 SG_ EPBL_a128_MotorPVoltHigh m2 : 11|1@1+ (1,0) [0|1] "" Vector__XXX
 SG_ EPBL_a129_ICR_MIA m2 : 12|1@1+ (1,0) [0|1] "" Vector__XXX
 SG_ EPBL_a130_BB_MIA m2 : 13|1@1+ (1,0) [0|1] "" Vector__XXX
 SG_ EPBL_a131_RCU_MIA m2 : 14|1@1+ (1,0) [0|1] "" Vector__XXX
 SG_ EPBL_a132_VCBATT1_MIA m2 : 15|1@1+ (1,0) [0|1] "" Vector__XXX
 SG_ EPBL_a134_NvOv m2 : 17|1@1+ (1,0) [0|1] "" Vector__XXX
 SG_ EPBL_a135_NvUv m2 : 18|1@1+ (1,0) [0|1] "" Vector__XXX
 SG_ EPBL_a136_PvOv m2 : 19|1@1+ (1,0) [0|1] "" Vector__XXX
 SG_ EPBL_a137_PvUv m2 : 20|1@1+ (1,0) [0|1] "" Vector__XXX
 SG_ EPBL_a138_NvmDualFailure m2 : 21|1@1+ (1,0) [0|1] "" Vector__XXX
 SG_ EPBL_a139_NvmRedundancyLoss m2 : 22|1@1+ (1,0) [0|1] "" Vector__XXX
 SG_ EPBL_a140_NvmSlowWrite m2 : 23|1@1+ (1,0) [0|1] "" Vector__XXX
 SG_ EPBL_a141_invalidState m2 : 24|1@1+ (1,0) [0|1] "" Vector__XXX
 SG_ EPBL_a170_12vOv m2 : 53|1@1+ (1,0) [0|1] "" Vector__XXX
 SG_ EPBL_a171_12vUv m2 : 54|1@1+ (1,0) [0|1] "" Vector__XXX
 SG_ EPBL_a172_SPI_MIA m2 : 55|1@1+ (1,0) [0|1] "" Vector__XXX
 SG_ EPBL_a173_hiCurrentMissing m2 : 56|1@1+ (1,0) [0|1] "" Vector__XXX
 SG_ EPBL_a174_csmReleaseFailed m2 : 57|1@1+ (1,0) [0|1] "" Vector__XXX
 SG_ EPBL_a175_csmReleaseRetry m2 : 58|1@1+ (1,0) [0|1] "" Vector__XXX
 SG_ EPBL_a176_csmApplyFailed m2 : 59|1@1+ (1,0) [0|1] "" Vector__XXX
 SG_ EPBL_a177_csmApplyRetry m2 : 60|1@1+ (1,0) [0|1] "" Vector__XXX
 SG_ EPBL_a178_caliperStateUnknown m2 : 61|1@1+ (1,0) [0|1] "" Vector__XXX
 SG_ EPBL_a179_epbProblem m2 : 62|1@1+ (1,0) [0|1] "" Vector__XXX
 SG_ EPBL_a180_dynamicActive m2 : 63|1@1+ (1,0) [0|1] "" Vector__XXX
 SG_ EPBL_a181_TooSteepGradeToPark m3 : 4|1@1+ (1,0) [0|1] "" Vector__XXX
 SG_ EPBL_a182_OneEPBAppliedUnsecEnv m3 : 5|1@1+ (1,0) [0|1] "" Vector__XXX
 SG_ EPBL_a183_cdpNotAvailable m3 : 6|1@1+ (1,0) [0|1] "" Vector__XXX
 SG_ EPBL_a184_dynamicParkAbort m3 : 7|1@1+ (1,0) [0|1] "" Vector__XXX
 SG_ EPBL_a185_summonAborted m3 : 8|1@1+ (1,0) [0|1] "" Vector__XXX
 SG_ EPBL_a186_externalParkAbort m3 : 9|1@1+ (1,0) [0|1] "" Vector__XXX
 SG_ EPBL_a187_cdpDynamic m3 : 10|1@1+ (1,0) [0|1] "" Vector__XXX
 SG_ EPBL_a188_epbDynamic m3 : 11|1@1+ (1,0) [0|1] "" Vector__XXX
 SG_ EPBL_a189_epbDynamicParkCanceled m3 : 12|1@1+ (1,0) [0|1] "" Vector__XXX
 SG_ EPBL_a190_csmApplyDegraded m3 : 13|1@1+ (1,0) [0|1] "" Vector__XXX
 SG_ EPBL_a191_csmReleaseDegraded m3 : 14|1@1+ (1,0) [0|1] "" Vector__XXX
 SG_ EPBL_a195_parkForDriverIsLeaving m3 : 18|1@1+ (1,0) [0|1] "" Vector__XXX
 SG_ EPBL_a196_freeRollModeActive m3 : 19|1@1+ (1,0) [0|1] "" Vector__XXX
 SG_ EPBL_a197_freeRollModeAtSpeed m3 : 20|1@1+ (1,0) [0|1] "" Vector__XXX
 SG_ EPBL_a198_holdClampComplete m3 : 21|1@1+ (1,0) [0|1] "" Vector__XXX
 SG_ EPBL_a200_PmUnparkNotAllowed m3 : 23|1@1+ (1,0) [0|1] "" Vector__XXX
 SG_ EPBL_a202_remoteEpbConfigIncompa m3 : 25|1@1+ (1,0) [0|1] "" Vector__XXX
 SG_ EPBL_a203_hwBrakeTypeMismatch m3 : 26|1@1+ (1,0) [0|1] "" Vector__XXX
 SG_ EPBL_a210_parkForDriverIsLeaving m3 : 33|1@1+ (1,0) [0|1] "" Vector__XXX
 SG_ EPBL_a216_SPI_MIA_debugData1 m3 : 39|1@1+ (1,0) [0|1] "" Vector__XXX
 SG_ EPBL_a217_SPI_MIA_debugData2 m3 : 40|1@1+ (1,0) [0|1] "" Vector__XXX
 SG_ EPBL_a225_epbActiveDecel m3 : 48|1@1+ (1,0) [0|1] "" Vector__XXX
 SG_ EPBL_a241_diOutputLocked m4 : 4|1@1+ (1,0) [0|1] "" Vector__XXX
 SG_ EPBL_a242_hvOutputLocked m4 : 5|1@1+ (1,0) [0|1] "" Vector__XXX
 SG_ EPBL_a243_bdwUnavailable m4 : 6|1@1+ (1,0) [0|1] "" Vector__XXX
 SG_ EPBL_a244_WinchModeActive m4 : 7|1@1+ (1,0) [0|1] "" Vector__XXX
 SG_ EPBL_a245_serviceModeActive m4 : 8|1@1+ (1,0) [0|1] "" Vector__XXX
 SG_ EPBL_a246_idleFaultApply m4 : 9|1@1+ (1,0) [0|1] "" Vector__XXX
 SG_ EPBL_a247_csmDynamicApplyRetry m4 : 10|1@1+ (1,0) [0|1] "" Vector__XXX
 SG_ EPBL_a248_csmDynamicApplyFailed m4 : 11|1@1+ (1,0) [0|1] "" Vector__XXX
 SG_ EPBL_a249_idleFaultRelease m4 : 12|1@1+ (1,0) [0|1] "" Vector__XXX
 SG_ EPBL_a250_WinchModeCanceled m4 : 13|1@1+ (1,0) [0|1] "" Vector__XXX
 SG_ EPBL_a251_currentVarianceHigh m4 : 14|1@1+ (1,0) [0|1] "" Vector__XXX
 SG_ EPBL_a252_winchModePending m4 : 15|1@1+ (1,0) [0|1] "" Vector__XXX
 SG_ EPBL_a253_esmReleaseBlocked m4 : 16|1@1+ (1,0) [0|1] "" Vector__XXX
 SG_ EPBL_a254_showStalkParkButtonFau m4 : 17|1@1+ (1,0) [0|1] "" Vector__XXX
 SG_ EPBL_a256_epbSystemApply m4 : 19|1@1+ (1,0) [0|1] "" Vector__XXX
 SG_ EPBL_a261_winchModeWithoutSteeri m4 : 24|1@1+ (1,0) [0|1] "" Vector__XXX
 SG_ EPBL_a262_cannotPrepareWinchMode m4 : 25|1@1+ (1,0) [0|1] "" Vector__XXX
 SG_ EPBL_a263_epbRecoveryPark m4 : 26|1@1+ (1,0) [0|1] "" Vector__XXX
 SG_ EPBL_a264_winchModeDeactivated m4 : 27|1@1+ (1,0) [0|1] "" Vector__XXX
 SG_ EPBL_a272_vhclPwrStateMsmtch m4 : 35|1@1+ (1,0) [0|1] "" Vector__XXX
 SG_ EPBL_a300_leftRightConfusion m4 : 63|1@1+ (1,0) [0|1] "" Vector__XXX
 SG_ EPBL_a301_oocSpeedViolation m5 : 4|1@1+ (1,0) [0|1] "" Vector__XXX
 SG_ EPBL_a302_csmLongRelease m5 : 5|1@1+ (1,0) [0|1] "" Vector__XXX
 SG_ EPBL_a303_clampingOccuredEarly m5 : 6|1@1+ (1,0) [0|1] "" Vector__XXX
 SG_ EPBL_a304_rearSeatControllerEFus m5 : 7|1@1+ (1,0) [0|1] "" Vector__XXX
 SG_ EPBL_a305_premiumAmpEFuseTrip m5 : 8|1@1+ (1,0) [0|1] "" Vector__XXX
 SG_ EPBL_a350_ensOutOfRange m5 : 53|1@1+ (1,0) [0|1] "" Vector__XXX
 SG_ EPBL_a352_audioCurrentSpikeData m5 : 55|1@1+ (1,0) [0|1] "" Vector__XXX
 SG_ EPBL_a353_missingSpeedUnableToPa m5 : 56|1@1+ (1,0) [0|1] "" Vector__XXX
 SG_ EPBL_a354_parkedForLowBrakeFluid m5 : 57|1@1+ (1,0) [0|1] "" Vector__XXX
 SG_ EPBL_a355_brakeHwAndEpbHwMismatc m5 : 58|1@1+ (1,0) [0|1] "" Vector__XXX
 SG_ EPBL_a356_parkingForStationaryDe m5 : 59|1@1+ (1,0) [0|1] "" Vector__XXX
 SG_ EPBL_a357_brakesTooHotForSlope m5 : 60|1@1+ (1,0) [0|1] "" Vector__XXX
 SG_ EPBL_a358_brakesTooHotForSlopeWi m5 : 61|1@1+ (1,0) [0|1] "" Vector__XXX
 SG_ EPBL_a360_ibstBrakeSwitchInvalid m5 : 63|1@1+ (1,0) [0|1] "" Vector__XXX
 SG_ EPBL_a361_espBrakeSwitchInvalid m6 : 4|1@1+ (1,0) [0|1] "" Vector__XXX
 SG_ EPBL_a362_ibstPressedEspNotPress m6 : 5|1@1+ (1,0) [0|1] "" Vector__XXX
 SG_ EPBL_a363_ibstNotPressedEspPress m6 : 6|1@1+ (1,0) [0|1] "" Vector__XXX
 SG_ EPBL_a364_espMasterCylCompOverTh m6 : 7|1@1+ (1,0) [0|1] "" Vector__XXX
 SG_ EPBL_a365_TooSteepToParkWithTrai m6 : 8|1@1+ (1,0) [0|1] "" Vector__XXX
 SG_ EPBL_a366_TooSteepToParkWithTrai m6 : 9|1@1+ (1,0) [0|1] "" Vector__XXX

BO_ 1992 EPBL_info: 8 EPBL
 SG_ EPBL_infoIndex M : 0|8@1+ (1,0) [0|255] "" Vector__XXX
 SG_ EPBL_infoBuildType m10 : 8|3@1+ (1,0) [0|7] "" Vector__XXX
 SG_ EPBL_infoBuildConfigId m10 : 16|16@1+ (1,0) [0|65535] "" Vector__XXX
 SG_ EPBL_infoHardwareId m10 : 32|16@1+ (1,0) [0|65535] "" Vector__XXX
 SG_ EPBL_infoComponentId m10 : 48|16@1+ (1,0) [0|65535] "" Vector__XXX
 SG_ EPBL_infoPcbaId m11 : 8|8@1+ (1,0) [0|255] "" Vector__XXX
 SG_ EPBL_infoAssemblyId m11 : 16|8@1+ (1,0) [0|255] "" Vector__XXX
 SG_ EPBL_infoUsageId m11 : 24|16@1+ (1,0) [0|65535] "" Vector__XXX
 SG_ EPBL_infoSubUsageId m11 : 40|16@1+ (1,0) [0|65535] "" Vector__XXX
 SG_ EPBL_infoAppCrc m13 : 8|32@1+ (1,0) [0|4294967295] "" Vector__XXX
 SG_ EPBL_infoAppGitHash m17 : 8|56@1+ (1,0) [0|7.20575940379e+16] "" Vector__XXX
 SG_ EPBL_infoBootGitHash m18 : 8|56@1+ (1,0) [0|7.20575940379e+16] "" Vector__XXX
 SG_ EPBL_infoPlatformType m19 : 8|8@1+ (1,0) [0|255] "" Vector__XXX
 SG_ EPBL_infoBootUdsProtoVersion m20 : 8|16@1+ (1,0) [0|65535] "" Vector__XXX
 SG_ EPBL_infoBootCrc m20 : 24|32@1+ (1,0) [0|4294967295] "" Vector__XXX

BO_ 648 EPBL_internalStatus: 8 EPBL
 SG_ EPBL_unitStatus : 0|5@1+ (1,0) [0|31] "" Vector__XXX
 SG_ EPBL_unitFaultStatus : 5|2@1+ (1,0) [0|3] "" Vector__XXX
 SG_ EPBL_summonState : 8|3@1+ (1,0) [0|7] "" Vector__XXX
 SG_ EPBL_disconnected : 11|1@1+ (1,0) [0|1] "" Vector__XXX
 SG_ EPBL_pistonTouchingRotor : 12|1@1+ (1,0) [0|1] "" Vector__XXX
 SG_ EPBL_csmFaultReason : 13|5@1+ (1,0) [0|31] "" Vector__XXX
 SG_ EPBL_esmOperationTrigger : 18|6@1+ (1,0) [0|63] "" Vector__XXX
 SG_ EPBL_summonFaultReason : 24|5@1+ (1,0) [0|31] "" Vector__XXX
 SG_ EPBL_localServiceModeActive : 29|1@1+ (1,0) [0|1] "" Vector__XXX
 SG_ EPBL_localCdpState : 30|2@1+ (1,0) [0|3] "" Vector__XXX
 SG_ EPBL_chimeRequestLocal : 33|3@1+ (1,0) [0|7] "" Vector__XXX
 SG_ EPBL_telltaleLocal : 39|3@1+ (1,0) [0|7] "" Vector__XXX
 SG_ EPBL_driverIsLeavingLocal : 42|1@1+ (1,0) [0|1] "" Vector__XXX
 SG_ EPBL_driverIsLeavingAnySpeedLoca : 43|1@1+ (1,0) [0|1] "" Vector__XXX
 SG_ EPBL_internalCDPRequest : 44|1@1+ (1,0) [0|1] "" Vector__XXX
 SG_ EPBL_esmSpeedClass : 45|3@1+ (1,0) [0|7] "" Vector__XXX
 SG_ EPBL_learnedEpbConfig : 48|4@1+ (1,0) [0|15] "" Vector__XXX
 SG_ EPBL_internalStatusCounter : 52|4@1+ (1,0) [0|15] "" Vector__XXX
 SG_ EPBL_internalStatusChecksum : 56|8@1+ (1,0) [0|255] "" Vector__XXX

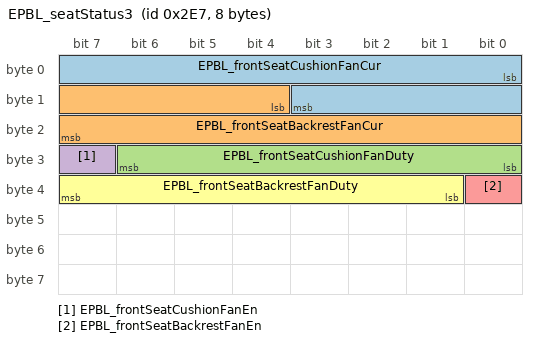
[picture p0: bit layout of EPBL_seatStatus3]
BO_ 743 EPBL_seatStatus3: 8 EPBL
 SG_ EPBL_frontSeatCushionFanCur : 0|12@1+ (0.01,0) [0|40.95] "A" Vector__XXX
 SG_ EPBL_frontSeatBackrestFanCur : 12|12@1+ (0.01,0) [0|40.95] "A" Vector__XXX
 SG_ EPBL_frontSeatCushionFanDuty : 24|7@1+ (1,0) [0|100] "%" Vector__XXX
 SG_ EPBL_frontSeatCushionFanEn : 31|1@1+ (1,0) [0|1] "" Vector__XXX
 SG_ EPBL_frontSeatBackrestFanEn : 32|1@1+ (1,0) [0|1] "" Vector__XXX
 SG_ EPBL_frontSeatBackrestFanDuty : 33|7@1+ (1,0) [0|100] "%" Vector__XXX

BO_ 681 EPBL_status: 8 EPBL
 SG_ EPBL_systemStatus : 0|4@1+ (1,0) [0|15] "" Vector__XXX
 SG_ EPBL_freeRollModeStatus : 4|2@1+ (1,0) [0|3] "" Vector__XXX
 SG_ EPBL_driverIsLeaving : 6|1@1+ (1,0) [0|1] "" Vector__XXX
 SG_ EPBL_driverIsLeavingAnySpeed : 7|1@1+ (1,0) [0|1] "" Vector__XXX
 SG_ EPBL_systemCdpAvailable : 8|1@1+ (1,0) [0|1] "" Vector__XXX
 SG_ EPBL_chimeRequest : 9|3@1+ (1,0) [0|7] "" Vector__XXX
 SG_ EPBL_telltale : 12|3@1+ (1,0) [0|7] "" Vector__XXX
 SG_ EPBL_contactorCycleNotNeededForW : 15|1@1+ (1,0) [0|1] "" Vector__XXX
 SG_ EPBL_redundantBrakingEnabled : 16|1@1+ (1,0) [0|1] "" Vector__XXX
 SG_ EPBL_summonEnabled : 17|1@1+ (1,0) [0|1] "" Vector__XXX
 SG_ EPBL_brakeLight : 18|1@1+ (1,0) [0|1] "" Vector__XXX
 SG_ EPBL_epbConfigMismatch : 19|1@1+ (1,0) [0|1] "" Vector__XXX
 SG_ EPBL_brakeConfirmedPressed : 20|1@1+ (1,0) [0|1] "" Vector__XXX
 SG_ EPBL_requestUserConfirmation : 21|1@1+ (1,0) [0|1] "" Vector__XXX
 SG_ EPBL_uiWinchModeMiscBlocking : 22|1@1+ (1,0) [0|1] "" Vector__XXX
 SG_ EPBL_winchModeActive : 23|1@1+ (1,0) [0|1] "" Vector__XXX
 SG_ EPBL_updateMode : 24|1@1+ (1,0) [0|1] "" Vector__XXX
 SG_ EPBL_winchModePermissive : 25|1@1+ (1,0) [0|1] "" Vector__XXX
 SG_ EPBL_winchModePending : 26|1@1+ (1,0) [0|1] "" Vector__XXX
 SG_ EPBL_cdpRequest : 27|1@1+ (1,0) [0|1] "" Vector__XXX
 SG_ EPBL_uiParkAvailable : 28|2@1+ (1,0) [0|3] "" Vector__XXX
 SG_ EPBL_brakeDiscWipeRequest : 30|2@1+ (1,0) [0|3] "" Vector__XXX
 SG_ EPBL_showUiGearShifter : 32|1@1+ (1,0) [0|1] "" Vector__XXX
 SG_ EPBL_uiWinchModeLvStatus : 33|2@1+ (1,0) [0|3] "" Vector__XXX
 SG_ EPBL_showStalkFaultedOnUi : 45|1@1+ (1,0) [0|1] "" Vector__XXX
 SG_ EPBL_espPowerRequest : 46|1@1+ (1,0) [0|1] "" Vector__XXX
 SG_ EPBL_okToPark : 47|1@1+ (1,0) [0|1] "" Vector__XXX
 SG_ EPBL_hornRequest : 48|1@1+ (1,0) [0|1] "" Vector__XXX
 SG_ EPBL_winchModeAvailable : 49|1@1+ (1,0) [0|1] "" Vector__XXX
 SG_ EPBL_bothDisconnected : 50|1@1+ (1,0) [0|1] "" Vector__XXX
 SG_ EPBL_blockDrive : 51|1@1+ (1,0) [0|1] "" Vector__XXX
 SG_ EPBL_statusCounter : 52|4@1+ (1,0) [0|15] "" Vector__XXX
 SG_ EPBL_statusChecksum : 56|8@1+ (1,0) [0|255] "" Vector__XXX

CM_ BO_ 1480 "Left electric parking brake message: alert log";
CM_ SG_ 1480 EPBL_alertID "Left electric parking brake: alert ID";
CM_ SG_ 1480 EPBL_alertState "Left electric parking brake: alert state";
CM_ SG_ 1480 EPBL_a001_InternalWatchdog "Left electric parking brake: a001 internal watchdog";
CM_ SG_ 1480 EPBL_a002_CPUUndervoltage "Left electric parking brake: a002 CPU undervoltage";
CM_ SG_ 1480 EPBL_a002_PowerOnReset "Left electric parking brake: a002 power on reset";
CM_ SG_ 1480 EPBL_a015_NVMMMemOverflow "Left electric parking brake: a015 NVMM mem overflow";
CM_ SG_ 1480 EPBL_a015_NVMMFilesystemError "Left electric parking brake: a015 NVMM filesystem error";
CM_ SG_ 1480 EPBL_a015_NVMMRecordIDError "Left electric parking brake: a015 NVMM record ID error";
CM_ SG_ 1480 EPBL_a057_VEH_cpControl "Left electric parking brake: a057 VEH cp control";
CM_ SG_ 1480 EPBL_a059_voltageDrop "Left electric parking brake: a059 voltage drop";
CM_ SG_ 1480 EPBL_a059_resistanceEstimate "Left electric parking brake: a059 resistance estimate";
CM_ SG_ 1480 EPBL_a059_current "Left electric parking brake: a059 current";
CM_ SG_ 1480 EPBL_a063_switchChannel "Left electric parking brake: a063 switch channel";
CM_ SG_ 1480 EPBL_a063_switchType "Left electric parking brake: a063 switch type";
CM_ SG_ 1480 EPBL_a063_ADCVoltage "Left electric parking brake: a063 ADC voltage";
CM_ SG_ 1480 EPBL_a063_disconnected "Left electric parking brake: a063 disconnected";
CM_ SG_ 1480 EPBL_a063_indeterminate "Left electric parking brake: a063 indeterminate";
CM_ SG_ 1480 EPBL_a063_stuckActive "Left electric parking brake: a063 stuck active";
CM_ SG_ 1480 EPBL_a063_faulted "Left electric parking brake: a063 faulted";
CM_ SG_ 1480 EPBL_a081_VEH_defogInfoMessage "Left electric parking brake: a081 VEH defog info message";
CM_ SG_ 1480 EPBL_a082_RIPC_epbPrivateState "Left electric parking brake: a082 RIPC epb private state";
CM_ SG_ 1480 EPBL_a082_RIPC_remoteHSD "Left electric parking brake: a082 RIPC remote HSD";
CM_ SG_ 1480 EPBL_a082_RIPC_railStatus "Left electric parking brake: a082 RIPC rail status";
CM_ SG_ 1480 EPBL_a082_RIPC_remoteMux "Left electric parking brake: a082 RIPC remote mux";
CM_ SG_ 1480 EPBL_a082_RIPC_remoteCurrent "Left electric parking brake: a082 RIPC remote current";
CM_ SG_ 1480 EPBL_a083_LIPC_epbPrivateState "Left electric parking brake: a083 LIPC epb private state";
CM_ SG_ 1480 EPBL_a083_LIPC_remoteHSD "Left electric parking brake: a083 LIPC remote HSD";
CM_ SG_ 1480 EPBL_a083_LIPC_railStatus "Left electric parking brake: a083 LIPC rail status";
CM_ SG_ 1480 EPBL_a083_LIPC_HSDFaults "Left electric parking brake: a083 LIPC HSD faults";
CM_ SG_ 1480 EPBL_a083_LIPC_remoteCurrent "Left electric parking brake: a083 LIPC remote current";
CM_ SG_ 1480 EPBL_a084_CH_StatusC "Left electric parking brake: a084 CH status c";
CM_ SG_ 1480 EPBL_a085_PARTY_buttonStatus "Left electric parking brake: a085 PARTY button status";
CM_ SG_ 1480 EPBL_a086_VEH_LVBMS_statusHigh "Left electric parking brake: a086 VEH LVBMS status high";
CM_ SG_ 1480 EPBL_a086_VEH_LVBMS_statusLow "Left electric parking brake: a086 VEH LVBMS status low";
CM_ SG_ 1480 EPBL_a086_VEH_status "Left electric parking brake: a086 VEH status";
CM_ SG_ 1480 EPBL_a086_VEH_12VBatteryStatus "Left electric parking brake: a086 VEH 12 v battery status";
CM_ SG_ 1480 EPBL_a086_VEH_LVPowerState "Left electric parking brake: a086 VEH LV power state";
CM_ SG_ 1480 EPBL_a086_VEH_lightStatus "Left electric parking brake: a086 VEH light status";
CM_ SG_ 1480 EPBL_a086_VEH_systemStatus "Left electric parking brake: a086 VEH system status";
CM_ SG_ 1480 EPBL_a086_VEH_thermalStatus "Left electric parking brake: a086 VEH thermal status";
CM_ SG_ 1480 EPBL_a086_VEH_vehNm "Left electric parking brake: a086 VEH veh nm";
CM_ SG_ 1480 EPBL_a087_VEH_temperature "Left electric parking brake: a087 VEH temperature";
CM_ SG_ 1480 EPBL_a087_VEH_thermalControl "Left electric parking brake: a087 VEH thermal control";
CM_ SG_ 1480 EPBL_a087_VEH_torque "Left electric parking brake: a087 VEH torque";
CM_ SG_ 1480 EPBL_a087_VEH_status "Left electric parking brake: a087 VEH status";
CM_ SG_ 1480 EPBL_a087_PARTY_torque "Left electric parking brake: a087 PARTY torque";
CM_ SG_ 1480 EPBL_a087_PARTY_status "Left electric parking brake: a087 PARTY status";
CM_ SG_ 1480 EPBL_a087_PARTY_temperature "Left electric parking brake: a087 PARTY temperature";
CM_ SG_ 1480 EPBL_a087_PARTY_thermalControl "Left electric parking brake: a087 PARTY thermal control";
CM_ SG_ 1480 EPBL_a088_VEH_temperature "Left electric parking brake: a088 VEH temperature";
CM_ SG_ 1480 EPBL_a088_VEH_thermalControl "Left electric parking brake: a088 VEH thermal control";
CM_ SG_ 1480 EPBL_a088_VEH_torque "Left electric parking brake: a088 VEH torque";
CM_ SG_ 1480 EPBL_a088_VEH_status "Left electric parking brake: a088 VEH status";
CM_ SG_ 1480 EPBL_a088_PARTY_torque "Left electric parking brake: a088 PARTY torque";
CM_ SG_ 1480 EPBL_a088_PARTY_status "Left electric parking brake: a088 PARTY status";
CM_ SG_ 1480 EPBL_a088_PARTY_temperature "Left electric parking brake: a088 PARTY temperature";
CM_ SG_ 1480 EPBL_a088_PARTY_thermalControl "Left electric parking brake: a088 PARTY thermal control";
CM_ SG_ 1480 EPBL_a089_PARTY_party1 "Left electric parking brake: a089 PARTY party1";
CM_ SG_ 1480 EPBL_a089_PARTY_status "Left electric parking brake: a089 PARTY status";
CM_ SG_ 1480 EPBL_a089_VEH_status "Left electric parking brake: a089 VEH status";
CM_ SG_ 1480 EPBL_a089_BDY_party1 "Left electric parking brake: a089 BDY party1";
CM_ SG_ 1480 EPBL_a089_BDY_status "Left electric parking brake: a089 BDY status";
CM_ SG_ 1480 EPBL_a089_CH_status "Left electric parking brake: a089 CH status";
CM_ SG_ 1480 EPBL_a089_CH_party1 "Left electric parking brake: a089 CH party1";
CM_ SG_ 1480 EPBL_a089_CH_party3 "Left electric parking brake: a089 CH party3";
CM_ SG_ 1480 EPBL_a089_VEH_party1 "Left electric parking brake: a089 VEH party1";
CM_ SG_ 1480 EPBL_a089_VEH_party3 "Left electric parking brake: a089 VEH party3";
CM_ SG_ 1480 EPBL_a091_VEH_faultsAndExtras "Left electric parking brake: a091 VEH faults and extras";
CM_ SG_ 1480 EPBL_a091_VEH_info "Left electric parking brake: a091 VEH info";
CM_ SG_ 1480 EPBL_a091_VEH_state "Left electric parking brake: a091 VEH state";
CM_ SG_ 1480 EPBL_a092_VEH_restraintStatus "Left electric parking brake: a092 VEH restraint status";
CM_ SG_ 1480 EPBL_a092_VEH_switchStatus "Left electric parking brake: a092 VEH switch status";
CM_ SG_ 1480 EPBL_a092_VEH_seatStatus2 "Left electric parking brake: a092 VEH seat status2";
CM_ SG_ 1480 EPBL_a092_VEH_vehNm "Left electric parking brake: a092 VEH veh nm";
CM_ SG_ 1480 EPBL_a093_VEH_restraintStatus "Left electric parking brake: a093 VEH restraint status";
CM_ SG_ 1480 EPBL_a093_VEH_switchStatus "Left electric parking brake: a093 VEH switch status";
CM_ SG_ 1480 EPBL_a093_VEH_seatStatus2 "Left electric parking brake: a093 VEH seat status2";
CM_ SG_ 1480 EPBL_a093_VEH_vehNm "Left electric parking brake: a093 VEH veh nm";
CM_ SG_ 1480 EPBL_a094_VEH_sysStatus "Left electric parking brake: a094 VEH sys status";
CM_ SG_ 1480 EPBL_a094_PARTY_sysStatus "Left electric parking brake: a094 PARTY sys status";
CM_ SG_ 1480 EPBL_a095_PT_ptNm "Left electric parking brake: a095 PT pt nm";
CM_ SG_ 1480 EPBL_a095_PT_status "Left electric parking brake: a095 PT status";
CM_ SG_ 1480 EPBL_a096_VEH_status "Left electric parking brake: a096 VEH status";
CM_ SG_ 1480 EPBL_a096_CH_status "Left electric parking brake: a096 CH status";
CM_ SG_ 1480 EPBL_a098_CH_torque "Left electric parking brake: a098 CH torque";
CM_ SG_ 1480 EPBL_a098_VEH_hvStatus "Left electric parking brake: a098 VEH hv status";
CM_ SG_ 1480 EPBL_a098_VEH_status "Left electric parking brake: a098 VEH status";
CM_ SG_ 1480 EPBL_a098_VEH_thermalControl "Left electric parking brake: a098 VEH thermal control";
CM_ SG_ 1480 EPBL_a098_VEH_temperature "Left electric parking brake: a098 VEH temperature";
CM_ SG_ 1480 EPBL_a098_VEH_torque "Left electric parking brake: a098 VEH torque";
CM_ SG_ 1480 EPBL_a098_PARTY_status "Left electric parking brake: a098 PARTY status";
CM_ SG_ 1480 EPBL_a098_PARTY_temperature "Left electric parking brake: a098 PARTY temperature";
CM_ SG_ 1480 EPBL_a098_PARTY_thermalControl "Left electric parking brake: a098 PARTY thermal control";
CM_ SG_ 1480 EPBL_a098_PARTY_torque "Left electric parking brake: a098 PARTY torque";
CM_ SG_ 1480 EPBL_a098_PT_thermalControl "Left electric parking brake: a098 PT thermal control";
CM_ SG_ 1480 EPBL_a098_PT_temperature "Left electric parking brake: a098 PT temperature";
CM_ SG_ 1480 EPBL_a099_VEH_oocStatus "Left electric parking brake: a099 VEH ooc status";
CM_ SG_ 1480 EPBL_a100_VEH "Left electric parking brake: a100 VEH";
CM_ SG_ 1480 EPBL_a100_PARTY "Left electric parking brake: a100 PARTY";
CM_ SG_ 1480 EPBL_a100_PT "Left electric parking brake: a100 PT";
CM_ SG_ 1480 EPBL_a100_CH "Left electric parking brake: a100 CH";
CM_ SG_ 1480 EPBL_a100_OBD "Left electric parking brake: a100 OBD";
CM_ SG_ 1480 EPBL_a101_VEH_state "Left electric parking brake: a101 VEH state";
CM_ SG_ 1480 EPBL_a101_PARTY_locState "Left electric parking brake: a101 PARTY loc state";
CM_ SG_ 1480 EPBL_a101_LIPC_externalWatchdogH "Left electric parking brake: a101 LIPC external watchdog heart beat";
CM_ SG_ 1480 EPBL_a101_VEH_locState "Left electric parking brake: a101 VEH loc state";
CM_ SG_ 1480 EPBL_a101_BDY_locState "Left electric parking brake: a101 BDY loc state";
CM_ SG_ 1480 EPBL_a102_VEH_faultsAndExtras "Left electric parking brake: a102 VEH faults and extras";
CM_ SG_ 1480 EPBL_a102_VEH_feedbackStatus "Left electric parking brake: a102 VEH feedback status";
CM_ SG_ 1480 EPBL_a102_VEH_sensorStatus "Left electric parking brake: a102 VEH sensor status";
CM_ SG_ 1480 EPBL_a102_VEH_rods "Left electric parking brake: a102 VEH rods";
CM_ SG_ 1480 EPBL_a103_VEH_hvsNm "Left electric parking brake: a103 VEH hvs nm";
CM_ SG_ 1480 EPBL_a103_VEH_vehNm "Left electric parking brake: a103 VEH veh nm";
CM_ SG_ 1480 EPBL_a103_VEH_status "Left electric parking brake: a103 VEH status";
CM_ SG_ 1480 EPBL_a103_PT_ptNm "Left electric parking brake: a103 PT pt nm";
CM_ SG_ 1480 EPBL_a103_PT_status "Left electric parking brake: a103 PT status";
CM_ SG_ 1480 EPBL_a103_VEH_evseStatus "Left electric parking brake: a103 VEH evse status";
CM_ SG_ 1480 EPBL_a105_VEH_states "Left electric parking brake: a105 VEH states";
CM_ SG_ 1480 EPBL_a105_VEH_chNm "Left electric parking brake: a105 VEH ch nm";
CM_ SG_ 1480 EPBL_a105_VEH_dampingStates "Left electric parking brake: a105 VEH damping states";
CM_ SG_ 1480 EPBL_a106_VEH_dcdcStatus "Left electric parking brake: a106 VEH dcdc status";
CM_ SG_ 1480 EPBL_a106_VEH_thermalControl "Left electric parking brake: a106 VEH thermal control";
CM_ SG_ 1480 EPBL_a106_VEH_thermalInterface "Left electric parking brake: a106 VEH thermal interface";
CM_ SG_ 1480 EPBL_a106_VEH_dcdcRailStatus "Left electric parking brake: a106 VEH dcdc rail status";
CM_ SG_ 1480 EPBL_a106_CH_dcdcRailStatus "Left electric parking brake: a106 CH dcdc rail status";
CM_ SG_ 1480 EPBL_a106_CH_alertMatrix "Left electric parking brake: a106 CH alert matrix";
CM_ SG_ 1480 EPBL_a107_VEH_hvsNm "Left electric parking brake: a107 VEH hvs nm";
CM_ SG_ 1480 EPBL_a107_VEH_vehNm "Left electric parking brake: a107 VEH veh nm";
CM_ SG_ 1480 EPBL_a107_VEH_status "Left electric parking brake: a107 VEH status";
CM_ SG_ 1480 EPBL_a107_VEH_thermalStatus "Left electric parking brake: a107 VEH thermal status";
CM_ SG_ 1480 EPBL_a107_VEH_thermalStatus2 "Left electric parking brake: a107 VEH thermal status2";
CM_ SG_ 1480 EPBL_a107_VEH_bmbMinMax "Left electric parking brake: a107 VEH bmb min max";
CM_ SG_ 1480 EPBL_a107_VEH_powerAvailable "Left electric parking brake: a107 VEH power available";
CM_ SG_ 1480 EPBL_a107_PT_ptNm "Left electric parking brake: a107 PT pt nm";
CM_ SG_ 1480 EPBL_a107_PT_status "Left electric parking brake: a107 PT status";
CM_ SG_ 1480 EPBL_a107_PT_thermalStatus "Left electric parking brake: a107 PT thermal status";
CM_ SG_ 1480 EPBL_a107_PT_socStatus "Left electric parking brake: a107 PT soc status";
CM_ SG_ 1480 EPBL_a107_VEH_socStatus "Left electric parking brake: a107 VEH soc status";
CM_ SG_ 1480 EPBL_a107_VEH_packConfig "Left electric parking brake: a107 VEH pack config";
CM_ SG_ 1480 EPBL_a107_VEH_energyStatus "Left electric parking brake: a107 VEH energy status";
CM_ SG_ 1480 EPBL_a107_VEH_chargeInfo "Left electric parking brake: a107 VEH charge info";
CM_ SG_ 1480 EPBL_a108_VEH_hvStatus "Left electric parking brake: a108 VEH hv status";
CM_ SG_ 1480 EPBL_a108_VEH_temperature "Left electric parking brake: a108 VEH temperature";
CM_ SG_ 1480 EPBL_a108_VEH_thermalControl "Left electric parking brake: a108 VEH thermal control";
CM_ SG_ 1480 EPBL_a108_VEH_torque "Left electric parking brake: a108 VEH torque";
CM_ SG_ 1480 EPBL_a108_VEH_status "Left electric parking brake: a108 VEH status";
CM_ SG_ 1480 EPBL_a108_PARTY_torque "Left electric parking brake: a108 PARTY torque";
CM_ SG_ 1480 EPBL_a108_PARTY_status "Left electric parking brake: a108 PARTY status";
CM_ SG_ 1480 EPBL_a108_PARTY_temperature "Left electric parking brake: a108 PARTY temperature";
CM_ SG_ 1480 EPBL_a108_PARTY_thermalControl "Left electric parking brake: a108 PARTY thermal control";
CM_ SG_ 1480 EPBL_a108_PT_temperature "Left electric parking brake: a108 PT temperature";
CM_ SG_ 1480 EPBL_a108_PT_thermalControl "Left electric parking brake: a108 PT thermal control";
CM_ SG_ 1480 EPBL_a109_PARTY_status "Left electric parking brake: a109 PARTY status";
CM_ SG_ 1480 EPBL_a109_PARTY_inertial2 "Left electric parking brake: a109 PARTY inertial2";
CM_ SG_ 1480 EPBL_a109_PARTY_nearDeploy "Left electric parking brake: a109 PARTY near deploy";
CM_ SG_ 1480 EPBL_a109_PARTY_collision "Left electric parking brake: a109 PARTY collision";
CM_ SG_ 1480 EPBL_a109_VEH_status "Left electric parking brake: a109 VEH status";
CM_ SG_ 1480 EPBL_a109_VEH_imuOffsets "Left electric parking brake: a109 VEH imu offsets";
CM_ SG_ 1480 EPBL_a109_PARTY_inertial1 "Left electric parking brake: a109 PARTY inertial1";
CM_ SG_ 1480 EPBL_a109_BDY_imuOffsets "Left electric parking brake: a109 BDY imu offsets";
CM_ SG_ 1480 EPBL_a109_BDY_inertial1 "Left electric parking brake: a109 BDY inertial1";
CM_ SG_ 1480 EPBL_a109_BDY_inertial2 "Left electric parking brake: a109 BDY inertial2";
CM_ SG_ 1480 EPBL_a109_BDY_status "Left electric parking brake: a109 BDY status";
CM_ SG_ 1480 EPBL_a109_VEH_inertial1 "Left electric parking brake: a109 VEH inertial1";
CM_ SG_ 1480 EPBL_a109_VEH_inertial2 "Left electric parking brake: a109 VEH inertial2";
CM_ SG_ 1480 EPBL_a109_CH_inertial1 "Left electric parking brake: a109 CH inertial1";
CM_ SG_ 1480 EPBL_a109_CH_inertial2 "Left electric parking brake: a109 CH inertial2";
CM_ SG_ 1480 EPBL_a109_CH_status "Left electric parking brake: a109 CH status";
CM_ SG_ 1480 EPBL_a110_VEH_carState "Left electric parking brake: a110 VEH car state";
CM_ SG_ 1480 EPBL_a110_VEH_carConfig "Left electric parking brake: a110 VEH car config";
CM_ SG_ 1480 EPBL_a110_VEH_time "Left electric parking brake: a110 VEH time";
CM_ SG_ 1480 EPBL_a110_VEH_updateStatus "Left electric parking brake: a110 VEH update status";
CM_ SG_ 1480 EPBL_a110_VEH_vehNm "Left electric parking brake: a110 VEH veh nm";
CM_ SG_ 1480 EPBL_a110_VEH_mismatchFault "Left electric parking brake: a110 VEH mismatch fault";
CM_ SG_ 1480 EPBL_a110_VEH_vin "Left electric parking brake: a110 VEH vin";
CM_ SG_ 1480 EPBL_a110_VEH_bmpDebug "Left electric parking brake: a110 VEH bmp debug";
CM_ SG_ 1480 EPBL_a110_VEH_gearControl "Left electric parking brake: a110 VEH gear control";
CM_ SG_ 1480 EPBL_a110_VEH_canLogAvailability "Left electric parking brake: a110 VEH can log availability";
CM_ SG_ 1480 EPBL_a110_CH_airbagCutoffStatus "Left electric parking brake: a110 CH airbag cutoff status";
CM_ SG_ 1480 EPBL_a110_CH_carConfig "Left electric parking brake: a110 CH car config";
CM_ SG_ 1480 EPBL_a110_CH_carState "Left electric parking brake: a110 CH car state";
CM_ SG_ 1480 EPBL_a110_CH_vin "Left electric parking brake: a110 CH vin";
CM_ SG_ 1480 EPBL_a110_CH_chNm "Left electric parking brake: a110 CH ch nm";
CM_ SG_ 1480 EPBL_a110_CH_epochTimeGtw "Left electric parking brake: a110 CH epoch time gtw";
CM_ SG_ 1480 EPBL_a111_VEH_internalStatus "Left electric parking brake: a111 VEH internal status";
CM_ SG_ 1480 EPBL_a111_VEH_status "Left electric parking brake: a111 VEH status";
CM_ SG_ 1480 EPBL_a111_VEH_vehNm "Left electric parking brake: a111 VEH veh nm";
CM_ SG_ 1480 EPBL_a111_RIPC_LVPowerState "Left electric parking brake: a111 RIPC LV power state";
CM_ SG_ 1480 EPBL_a111_RIPC_epbPrivateState "Left electric parking brake: a111 RIPC epb private state";
CM_ SG_ 1480 EPBL_a111_RIPC_railStatus "Left electric parking brake: a111 RIPC rail status";
CM_ SG_ 1480 EPBL_a111_RIPC_remoteADC "Left electric parking brake: a111 RIPC remote ADC";
CM_ SG_ 1480 EPBL_a111_RIPC_switchStatus "Left electric parking brake: a111 RIPC switch status";
CM_ SG_ 1480 EPBL_a111_VEH_LVPowerState "Left electric parking brake: a111 VEH LV power state";
CM_ SG_ 1480 EPBL_a111_VEH_seatStatus "Left electric parking brake: a111 VEH seat status";
CM_ SG_ 1480 EPBL_a111_PARTY_status "Left electric parking brake: a111 PARTY status";
CM_ SG_ 1480 EPBL_a111_CH_status "Left electric parking brake: a111 CH status";
CM_ SG_ 1480 EPBL_a111_VEH_seatStatus3 "Left electric parking brake: a111 VEH seat status3";
CM_ SG_ 1480 EPBL_a112_VEH_internalStatus "Left electric parking brake: a112 VEH internal status";
CM_ SG_ 1480 EPBL_a112_VEH_status "Left electric parking brake: a112 VEH status";
CM_ SG_ 1480 EPBL_a112_VEH_vehNm "Left electric parking brake: a112 VEH veh nm";
CM_ SG_ 1480 EPBL_a112_LIPC_LVPowerState "Left electric parking brake: a112 LIPC LV power state";
CM_ SG_ 1480 EPBL_a112_LIPC_epbPrivateState "Left electric parking brake: a112 LIPC epb private state";
CM_ SG_ 1480 EPBL_a112_LIPC_railStatus "Left electric parking brake: a112 LIPC rail status";
CM_ SG_ 1480 EPBL_a112_LIPC_remoteADC "Left electric parking brake: a112 LIPC remote ADC";
CM_ SG_ 1480 EPBL_a112_LIPC_switchStatus "Left electric parking brake: a112 LIPC switch status";
CM_ SG_ 1480 EPBL_a112_VEH_LVPowerState "Left electric parking brake: a112 VEH LV power state";
CM_ SG_ 1480 EPBL_a112_PARTY_status "Left electric parking brake: a112 PARTY status";
CM_ SG_ 1480 EPBL_a112_CH_status "Left electric parking brake: a112 CH status";
CM_ SG_ 1480 EPBL_a114_PARTY_status "Left electric parking brake: a114 PARTY status";
CM_ SG_ 1480 EPBL_a114_PARTY_wheelSpeeds "Left electric parking brake: a114 PARTY wheel speeds";
CM_ SG_ 1480 EPBL_a114_VEH_wheelSpeeds "Left electric parking brake: a114 VEH wheel speeds";
CM_ SG_ 1480 EPBL_a114_CH_wheelSpeeds "Left electric parking brake: a114 CH wheel speeds";
CM_ SG_ 1480 EPBL_a114_PARTY_party3 "Left electric parking brake: a114 PARTY party3";
CM_ SG_ 1480 EPBL_a114_VEH_party3 "Left electric parking brake: a114 VEH party3";
CM_ SG_ 1480 EPBL_a114_VEH_status "Left electric parking brake: a114 VEH status";
CM_ SG_ 1480 EPBL_a114_PARTY_wheelRotation "Left electric parking brake: a114 PARTY wheel rotation";
CM_ SG_ 1480 EPBL_a114_CH_wheelRotation "Left electric parking brake: a114 CH wheel rotation";
CM_ SG_ 1480 EPBL_a114_VEH_wheelRotation "Left electric parking brake: a114 VEH wheel rotation";
CM_ SG_ 1480 EPBL_a114_PARTY_brakeTorque "Left electric parking brake: a114 PARTY brake torque";
CM_ SG_ 1480 EPBL_a114_PARTY_offsets "Left electric parking brake: a114 PARTY offsets";
CM_ SG_ 1480 EPBL_a114_BDY_offsets "Left electric parking brake: a114 BDY offsets";
CM_ SG_ 1480 EPBL_a114_BDY_party3 "Left electric parking brake: a114 BDY party3";
CM_ SG_ 1480 EPBL_a114_BDY_status "Left electric parking brake: a114 BDY status";
CM_ SG_ 1480 EPBL_a114_BDY_wheelRotation "Left electric parking brake: a114 BDY wheel rotation";
CM_ SG_ 1480 EPBL_a114_BDY_wheelSpeeds "Left electric parking brake: a114 BDY wheel speeds";
CM_ SG_ 1480 EPBL_a114_CH_party1 "Left electric parking brake: a114 CH party1";
CM_ SG_ 1480 EPBL_a114_CH_party3 "Left electric parking brake: a114 CH party3";
CM_ SG_ 1480 EPBL_a114_CH_status "Left electric parking brake: a114 CH status";
CM_ SG_ 1480 EPBL_a115_VEH_vehNm "Left electric parking brake: a115 VEH veh nm";
CM_ SG_ 1480 EPBL_a115_VEH_authentication "Left electric parking brake: a115 VEH authentication";
CM_ SG_ 1480 EPBL_a115_VEH_BLEResetRequest "Left electric parking brake: a115 VEH BLE reset request";
CM_ SG_ 1480 EPBL_a115_VEH_requests "Left electric parking brake: a115 VEH requests";
CM_ SG_ 1480 EPBL_a115_VEH_requests2 "Left electric parking brake: a115 VEH requests2";
CM_ SG_ 1480 EPBL_a115_REM_authentication "Left electric parking brake: a115 REM authentication";
CM_ SG_ 1480 EPBL_a115_UI_corianderVehicleCon "Left electric parking brake: a115 UI coriander vehicle control";
CM_ SG_ 1480 EPBL_a115_CH_TPMSDisplay "Left electric parking brake: a115 CH TPMS display";
CM_ SG_ 1480 EPBL_a116_PARTY_epbmStatus "Left electric parking brake: a116 PARTY epbm status";
CM_ SG_ 1480 EPBL_a116_VEH_vehNm "Left electric parking brake: a116 VEH veh nm";
CM_ SG_ 1480 EPBL_a116_VEH_hvacRequest "Left electric parking brake: a116 VEH hvac request";
CM_ SG_ 1480 EPBL_a116_VEH_hvacStatus "Left electric parking brake: a116 VEH hvac status";
CM_ SG_ 1480 EPBL_a116_VEH_LVPowerState "Left electric parking brake: a116 VEH LV power state";
CM_ SG_ 1480 EPBL_a116_VEH_lightStatus "Left electric parking brake: a116 VEH light status";
CM_ SG_ 1480 EPBL_a116_VEH_seatStatus "Left electric parking brake: a116 VEH seat status";
CM_ SG_ 1480 EPBL_a116_VEH_thsStatus "Left electric parking brake: a116 VEH ths status";
CM_ SG_ 1480 EPBL_a116_VEH_doorStatus "Left electric parking brake: a116 VEH door status";
CM_ SG_ 1480 EPBL_a116_VEH_seatHeatStatus "Left electric parking brake: a116 VEH seat heat status";
CM_ SG_ 1480 EPBL_a116_VEH_restraintStatus "Left electric parking brake: a116 VEH restraint status";
CM_ SG_ 1480 EPBL_a116_VEH_switchStatus "Left electric parking brake: a116 VEH switch status";
CM_ SG_ 1480 EPBL_a116_VEH_logging1Hz "Left electric parking brake: a116 VEH logging1 hz";
CM_ SG_ 1480 EPBL_a116_VEH_seatStatus2 "Left electric parking brake: a116 VEH seat status2";
CM_ SG_ 1480 EPBL_a116_VEH_status "Left electric parking brake: a116 VEH status";
CM_ SG_ 1480 EPBL_a116_VEH_thermalCommand "Left electric parking brake: a116 VEH thermal command";
CM_ SG_ 1480 EPBL_a116_VEH_windowStatus "Left electric parking brake: a116 VEH window status";
CM_ SG_ 1480 EPBL_a116_PARTY_restraintStatus "Left electric parking brake: a116 PARTY restraint status";
CM_ SG_ 1480 EPBL_a116_PARTY_doorStatus "Left electric parking brake: a116 PARTY door status";
CM_ SG_ 1480 EPBL_a116_BDY_epbmStatus "Left electric parking brake: a116 BDY epbm status";
CM_ SG_ 1480 EPBL_a116_BDY_restraintStatus "Left electric parking brake: a116 BDY restraint status";
CM_ SG_ 1480 EPBL_a116_VEH_hvacStatus2 "Left electric parking brake: a116 VEH hvac status2";
CM_ SG_ 1480 EPBL_a117_BDY_epbmStatus "Left electric parking brake: a117 BDY epbm status";
CM_ SG_ 1480 EPBL_a117_BDY_restraintStatus "Left electric parking brake: a117 BDY restraint status";
CM_ SG_ 1480 EPBL_a117_VEH_prndStatus "Left electric parking brake: a117 VEH prnd status";
CM_ SG_ 1480 EPBL_a117_PARTY_epbmStatus "Left electric parking brake: a117 PARTY epbm status";
CM_ SG_ 1480 EPBL_a117_VEH_vehNm "Left electric parking brake: a117 VEH veh nm";
CM_ SG_ 1480 EPBL_a117_VEH_hvacBlowerFdb "Left electric parking brake: a117 VEH hvac blower fdb";
CM_ SG_ 1480 EPBL_a117_VEH_LVPowerState "Left electric parking brake: a117 VEH LV power state";
CM_ SG_ 1480 EPBL_a117_VEH_restraintStatus "Left electric parking brake: a117 VEH restraint status";
CM_ SG_ 1480 EPBL_a117_VEH_lightStatus "Left electric parking brake: a117 VEH light status";
CM_ SG_ 1480 EPBL_a117_VEH_seatStatus "Left electric parking brake: a117 VEH seat status";
CM_ SG_ 1480 EPBL_a117_BDY_falconSwitchStatus "Left electric parking brake: a117 BDY falcon switch status";
CM_ SG_ 1480 EPBL_a117_VEH_doorStatus "Left electric parking brake: a117 VEH door status";
CM_ SG_ 1480 EPBL_a117_VEH_doorStatus2 "Left electric parking brake: a117 VEH door status2";
CM_ SG_ 1480 EPBL_a117_VEH_windowStatus "Left electric parking brake: a117 VEH window status";
CM_ SG_ 1480 EPBL_a117_VEH_switchStatus "Left electric parking brake: a117 VEH switch status";
CM_ SG_ 1480 EPBL_a117_VEH_intrusionSensorSta "Left electric parking brake: a117 VEH intrusion sensor status";
CM_ SG_ 1480 EPBL_a117_VEH_liftgateStatus "Left electric parking brake: a117 VEH liftgate status";
CM_ SG_ 1480 EPBL_a117_VEH_seatStatus2 "Left electric parking brake: a117 VEH seat status2";
CM_ SG_ 1480 EPBL_a117_PARTY_restraintStatus "Left electric parking brake: a117 PARTY restraint status";
CM_ SG_ 1480 EPBL_a117_VEH_thermalStatus "Left electric parking brake: a117 VEH thermal status";
CM_ SG_ 1480 EPBL_a117_PARTY_doorStatus "Left electric parking brake: a117 PARTY door status";
CM_ SG_ 1480 EPBL_a117_VEH_status "Left electric parking brake: a117 VEH status";
CM_ SG_ 1480 EPBL_a117_PARTY_prndStatus "Left electric parking brake: a117 PARTY prnd status";
CM_ SG_ 1480 EPBL_a118_VEH_vehNm "Left electric parking brake: a118 VEH veh nm";
CM_ SG_ 1480 EPBL_a118_VEH_lighting "Left electric parking brake: a118 VEH lighting";
CM_ SG_ 1480 EPBL_a118_VEH_sensors "Left electric parking brake: a118 VEH sensors";
CM_ SG_ 1480 EPBL_a118_VEH_status "Left electric parking brake: a118 VEH status";
CM_ SG_ 1480 EPBL_a118_VEH_okToUseHighPwr "Left electric parking brake: a118 VEH ok to use high pwr";
CM_ SG_ 1480 EPBL_a118_VEH_LVPowerState "Left electric parking brake: a118 VEH LV power state";
CM_ SG_ 1480 EPBL_a118_VEH_coolant "Left electric parking brake: a118 VEH coolant";
CM_ SG_ 1480 EPBL_a118_VEH_vehicleStatus "Left electric parking brake: a118 VEH vehicle status";
CM_ SG_ 1480 EPBL_a118_VEH_12VBatteryStatus "Left electric parking brake: a118 VEH 12 v battery status";
CM_ SG_ 1480 EPBL_a118_VEH_systemStatus "Left electric parking brake: a118 VEH system status";
CM_ SG_ 1480 EPBL_a118_PARTY_LVPowerState "Left electric parking brake: a118 PARTY LV power state";
CM_ SG_ 1480 EPBL_a118_PARTY_outputPowerStatu "Left electric parking brake: a118 PARTY output power status";
CM_ SG_ 1480 EPBL_a118_PARTY_vehicleTime "Left electric parking brake: a118 PARTY vehicle time";
CM_ SG_ 1480 EPBL_a118_VEH_thermalCommand "Left electric parking brake: a118 VEH thermal command";
CM_ SG_ 1480 EPBL_a118_CH_LVPowerState "Left electric parking brake: a118 CH LV power state";
CM_ SG_ 1480 EPBL_a118_PARTY_sensors "Left electric parking brake: a118 PARTY sensors";
CM_ SG_ 1480 EPBL_a118_CH_sensors "Left electric parking brake: a118 CH sensors";
CM_ SG_ 1480 EPBL_a118_VEH_interNodeResistanc "Left electric parking brake: a118 VEH inter node resistance";
CM_ SG_ 1480 EPBL_a118_CH_lighting "Left electric parking brake: a118 CH lighting";
CM_ SG_ 1480 EPBL_a118_VEH_lightStatus "Left electric parking brake: a118 VEH light status";
CM_ SG_ 1480 EPBL_a118_PARTY_vehNm "Left electric parking brake: a118 PARTY veh nm";
CM_ SG_ 1480 EPBL_a118_CH_12VBatteryStatus "Left electric parking brake: a118 CH 12 v battery status";
CM_ SG_ 1480 EPBL_a118_CH_LVBMS_statusHigh "Left electric parking brake: a118 CH LVBMS status high";
CM_ SG_ 1480 EPBL_a118_CH_alertMatrix "Left electric parking brake: a118 CH alert matrix";
CM_ SG_ 1480 EPBL_a118_BDY_outputPowerStatus "Left electric parking brake: a118 BDY output power status";
CM_ SG_ 1480 EPBL_a118_BDY_vehicleTime "Left electric parking brake: a118 BDY vehicle time";
CM_ SG_ 1480 EPBL_a118_PARTY_AP_vehicleState1 "Left electric parking brake: a118 PARTY AP vehicle state1 hz muxed";
CM_ SG_ 1480 EPBL_a118_BDY_AP_vehicleState1Hz "Left electric parking brake: a118 BDY AP vehicle state1 hz muxed";
CM_ SG_ 1480 EPBL_a119_VEH_steerAngle "Left electric parking brake: a119 VEH steer angle";
CM_ SG_ 1480 EPBL_a119_VEH_leftStalk "Left electric parking brake: a119 VEH left stalk";
CM_ SG_ 1480 EPBL_a119_VEH_rightStalk "Left electric parking brake: a119 VEH right stalk";
CM_ SG_ 1480 EPBL_a119_PARTY_rightStalk "Left electric parking brake: a119 PARTY right stalk";
CM_ SG_ 1480 EPBL_a119_CH_steerAngle "Left electric parking brake: a119 CH steer angle";
CM_ SG_ 1480 EPBL_a119_PARTY_steerAngle "Left electric parking brake: a119 PARTY steer angle";
CM_ SG_ 1480 EPBL_a120_PARTY_chassisCntl "Left electric parking brake: a120 PARTY chassis cntl";
CM_ SG_ 1480 EPBL_a120_VEH_systemStatus "Left electric parking brake: a120 VEH system status";
CM_ SG_ 1480 EPBL_a120_CH_chassisCntl "Left electric parking brake: a120 CH chassis cntl";
CM_ SG_ 1480 EPBL_a120_PARTY_systemStatus "Left electric parking brake: a120 PARTY system status";
CM_ SG_ 1480 EPBL_a120_PARTY_torque "Left electric parking brake: a120 PARTY torque";
CM_ SG_ 1480 EPBL_a120_VEH_torque "Left electric parking brake: a120 VEH torque";
CM_ SG_ 1480 EPBL_a120_PARTY_locStatus "Left electric parking brake: a120 PARTY loc status";
CM_ SG_ 1480 EPBL_a120_PARTY_speed "Left electric parking brake: a120 PARTY speed";
CM_ SG_ 1480 EPBL_a120_VEH_speed "Left electric parking brake: a120 VEH speed";
CM_ SG_ 1480 EPBL_a120_PARTY_status "Left electric parking brake: a120 PARTY status";
CM_ SG_ 1480 EPBL_a120_PT_speed "Left electric parking brake: a120 PT speed";
CM_ SG_ 1480 EPBL_a120_PT_systemStatus "Left electric parking brake: a120 PT system status";
CM_ SG_ 1480 EPBL_a120_PARTY_vehicleEstimates "Left electric parking brake: a120 PARTY vehicle estimates";
CM_ SG_ 1480 EPBL_a120_VEH_aggregatedAxleSpee "Left electric parking brake: a120 VEH aggregated axle speed";
CM_ SG_ 1480 EPBL_a120_PARTY_aggregatedAxleSp "Left electric parking brake: a120 PARTY aggregated axle speed";
CM_ SG_ 1480 EPBL_a120_VEH_systemPower "Left electric parking brake: a120 VEH system power";
CM_ SG_ 1480 EPBL_a120_PT_systemPower "Left electric parking brake: a120 PT system power";
CM_ SG_ 1480 EPBL_a120_PARTY_stalklessInterfa "Left electric parking brake: a120 PARTY stalkless interfaces";
CM_ SG_ 1480 EPBL_a120_CH_speed "Left electric parking brake: a120 CH speed";
CM_ SG_ 1480 EPBL_a120_VEH_estimatedBrakeTemp "Left electric parking brake: a120 VEH estimated brake temp";
CM_ SG_ 1480 EPBL_a120_PARTY_prndControl "Left electric parking brake: a120 PARTY prnd control";
CM_ SG_ 1480 EPBL_a120_PARTY_locStatus2 "Left electric parking brake: a120 PARTY loc status2";
CM_ SG_ 1480 EPBL_a120_VEH_chassisCntl "Left electric parking brake: a120 VEH chassis cntl";
CM_ SG_ 1480 EPBL_a120_VEH_locStatus "Left electric parking brake: a120 VEH loc status";
CM_ SG_ 1480 EPBL_a120_VEH_locStatus2 "Left electric parking brake: a120 VEH loc status2";
CM_ SG_ 1480 EPBL_a120_VEH_prndControl "Left electric parking brake: a120 VEH prnd control";
CM_ SG_ 1480 EPBL_a120_VEH_vehicleEstimates "Left electric parking brake: a120 VEH vehicle estimates";
CM_ SG_ 1480 EPBL_a122_filteredCurrentCal "Left electric parking brake: a122 filtered current cal";
CM_ SG_ 1480 EPBL_a123_filteredCurrentCal "Left electric parking brake: a123 filtered current cal";
CM_ SG_ 1480 EPBL_a124_calOutOfBoundsData "Left electric parking brake: a124 cal out of bounds data";
CM_ SG_ 1480 EPBL_a125_pvFilt "Left electric parking brake: a125 pv filt";
CM_ SG_ 1480 EPBL_a125_nvFilt "Left electric parking brake: a125 nv filt";
CM_ SG_ 1480 EPBL_a125_12vFilt "Left electric parking brake: a125 12v filt";
CM_ SG_ 1480 EPBL_a126_pvFilt "Left electric parking brake: a126 pv filt";
CM_ SG_ 1480 EPBL_a126_nvFilt "Left electric parking brake: a126 nv filt";
CM_ SG_ 1480 EPBL_a126_12vFilt "Left electric parking brake: a126 12v filt";
CM_ SG_ 1480 EPBL_a127_pvFilt "Left electric parking brake: a127 pv filt";
CM_ SG_ 1480 EPBL_a127_nvFilt "Left electric parking brake: a127 nv filt";
CM_ SG_ 1480 EPBL_a127_12vFilt "Left electric parking brake: a127 12v filt";
CM_ SG_ 1480 EPBL_a128_pvFilt "Left electric parking brake: a128 pv filt";
CM_ SG_ 1480 EPBL_a128_nvFilt "Left electric parking brake: a128 nv filt";
CM_ SG_ 1480 EPBL_a128_12vFilt "Left electric parking brake: a128 12v filt";
CM_ SG_ 1480 EPBL_a129_VEH_occupancy "Left electric parking brake: a129 VEH occupancy";
CM_ SG_ 1480 EPBL_a130_PARTY_status "Left electric parking brake: a130 PARTY status";
CM_ SG_ 1480 EPBL_a130_VEH_status "Left electric parking brake: a130 VEH status";
CM_ SG_ 1480 EPBL_a131_PARTY_actuation "Left electric parking brake: a131 PARTY actuation";
CM_ SG_ 1480 EPBL_a131_CH_actuation "Left electric parking brake: a131 CH actuation";
CM_ SG_ 1480 EPBL_a134_pvFilt "Left electric parking brake: a134 pv filt";
CM_ SG_ 1480 EPBL_a134_nvFilt "Left electric parking brake: a134 nv filt";
CM_ SG_ 1480 EPBL_a134_12vFilt "Left electric parking brake: a134 12v filt";
CM_ SG_ 1480 EPBL_a135_pvFilt "Left electric parking brake: a135 pv filt";
CM_ SG_ 1480 EPBL_a135_nvFilt "Left electric parking brake: a135 nv filt";
CM_ SG_ 1480 EPBL_a135_12vFilt "Left electric parking brake: a135 12v filt";
CM_ SG_ 1480 EPBL_a136_pvFilt "Left electric parking brake: a136 pv filt";
CM_ SG_ 1480 EPBL_a136_nvFilt "Left electric parking brake: a136 nv filt";
CM_ SG_ 1480 EPBL_a136_12vFilt "Left electric parking brake: a136 12v filt";
CM_ SG_ 1480 EPBL_a137_pvFilt "Left electric parking brake: a137 pv filt";
CM_ SG_ 1480 EPBL_a137_nvFilt "Left electric parking brake: a137 nv filt";
CM_ SG_ 1480 EPBL_a137_12vFilt "Left electric parking brake: a137 12v filt";
CM_ SG_ 1480 EPBL_a138_localState "Left electric parking brake: a138 local state";
CM_ SG_ 1480 EPBL_a138_monitorState "Left electric parking brake: a138 monitor state";
CM_ SG_ 1480 EPBL_a139_localState "Left electric parking brake: a139 local state";
CM_ SG_ 1480 EPBL_a139_monitorState "Left electric parking brake: a139 monitor state";
CM_ SG_ 1480 EPBL_a141_fromState "Left electric parking brake: a141 from state";
CM_ SG_ 1480 EPBL_a141_toState "Left electric parking brake: a141 to state";
CM_ SG_ 1480 EPBL_a170_pvFilt "Left electric parking brake: a170 pv filt";
CM_ SG_ 1480 EPBL_a170_nvFilt "Left electric parking brake: a170 nv filt";
CM_ SG_ 1480 EPBL_a170_12vFilt "Left electric parking brake: a170 12v filt";
CM_ SG_ 1480 EPBL_a171_pvFilt "Left electric parking brake: a171 pv filt";
CM_ SG_ 1480 EPBL_a171_nvFilt "Left electric parking brake: a171 nv filt";
CM_ SG_ 1480 EPBL_a171_12vFilt "Left electric parking brake: a171 12v filt";
CM_ SG_ 1480 EPBL_a174_esmState "Left electric parking brake: a174 esm state";
CM_ SG_ 1480 EPBL_a174_esmStateRequest "Left electric parking brake: a174 esm state request";
CM_ SG_ 1480 EPBL_a174_faultStatus "Left electric parking brake: a174 fault status";
CM_ SG_ 1480 EPBL_a174_monitorUnitStatus "Left electric parking brake: a174 monitor unit status";
CM_ SG_ 1480 EPBL_a174_monitorFaultStatus "Left electric parking brake: a174 monitor fault status";
CM_ SG_ 1480 EPBL_a174_csmFaultReason "Left electric parking brake: a174 csm fault reason";
CM_ SG_ 1480 EPBL_a174_esmOpTrigger "Left electric parking brake: a174 esm op trigger";
CM_ SG_ 1480 EPBL_a174_nonterminalReason "Left electric parking brake: a174 nonterminal reason";
CM_ SG_ 1480 EPBL_a175_esmState "Left electric parking brake: a175 esm state";
CM_ SG_ 1480 EPBL_a175_esmStateRequest "Left electric parking brake: a175 esm state request";
CM_ SG_ 1480 EPBL_a175_faultStatus "Left electric parking brake: a175 fault status";
CM_ SG_ 1480 EPBL_a175_monitorUnitStatus "Left electric parking brake: a175 monitor unit status";
CM_ SG_ 1480 EPBL_a175_monitorFaultStatus "Left electric parking brake: a175 monitor fault status";
CM_ SG_ 1480 EPBL_a175_csmFaultReason "Left electric parking brake: a175 csm fault reason";
CM_ SG_ 1480 EPBL_a175_esmOpTrigger "Left electric parking brake: a175 esm op trigger";
CM_ SG_ 1480 EPBL_a175_nonterminalReason "Left electric parking brake: a175 nonterminal reason";
CM_ SG_ 1480 EPBL_a176_esmState "Left electric parking brake: a176 esm state";
CM_ SG_ 1480 EPBL_a176_esmStateRequest "Left electric parking brake: a176 esm state request";
CM_ SG_ 1480 EPBL_a176_faultStatus "Left electric parking brake: a176 fault status";
CM_ SG_ 1480 EPBL_a176_monitorUnitStatus "Left electric parking brake: a176 monitor unit status";
CM_ SG_ 1480 EPBL_a176_monitorFaultStatus "Left electric parking brake: a176 monitor fault status";
CM_ SG_ 1480 EPBL_a176_csmFaultReason "Left electric parking brake: a176 csm fault reason";
CM_ SG_ 1480 EPBL_a176_esmOpTrigger "Left electric parking brake: a176 esm op trigger";
CM_ SG_ 1480 EPBL_a176_nonterminalReason "Left electric parking brake: a176 nonterminal reason";
CM_ SG_ 1480 EPBL_a177_esmState "Left electric parking brake: a177 esm state";
CM_ SG_ 1480 EPBL_a177_esmStateRequest "Left electric parking brake: a177 esm state request";
CM_ SG_ 1480 EPBL_a177_faultStatus "Left electric parking brake: a177 fault status";
CM_ SG_ 1480 EPBL_a177_monitorUnitStatus "Left electric parking brake: a177 monitor unit status";
CM_ SG_ 1480 EPBL_a177_monitorFaultStatus "Left electric parking brake: a177 monitor fault status";
CM_ SG_ 1480 EPBL_a177_csmFaultReason "Left electric parking brake: a177 csm fault reason";
CM_ SG_ 1480 EPBL_a177_esmOpTrigger "Left electric parking brake: a177 esm op trigger";
CM_ SG_ 1480 EPBL_a177_nonterminalReason "Left electric parking brake: a177 nonterminal reason";
CM_ SG_ 1480 EPBL_a178_localCaliperState "Left electric parking brake: a178 local caliper state";
CM_ SG_ 1480 EPBL_a178_monitorCaliperState "Left electric parking brake: a178 monitor caliper state";
CM_ SG_ 1480 EPBL_a179_esmState "Left electric parking brake: a179 esm state";
CM_ SG_ 1480 EPBL_a179_esmStateRequest "Left electric parking brake: a179 esm state request";
CM_ SG_ 1480 EPBL_a179_faultStatus "Left electric parking brake: a179 fault status";
CM_ SG_ 1480 EPBL_a179_monitorUnitStatus "Left electric parking brake: a179 monitor unit status";
CM_ SG_ 1480 EPBL_a179_monitorFaultStatus "Left electric parking brake: a179 monitor fault status";
CM_ SG_ 1480 EPBL_a179_csmFaultReason "Left electric parking brake: a179 csm fault reason";
CM_ SG_ 1480 EPBL_a179_esmOpTrigger "Left electric parking brake: a179 esm op trigger";
CM_ SG_ 1480 EPBL_a179_nonterminalReason "Left electric parking brake: a179 nonterminal reason";
CM_ SG_ 1480 EPBL_a180_esmOpTrigger "Left electric parking brake: a180 esm op trigger";
CM_ SG_ 1480 EPBL_a180_previousState "Left electric parking brake: a180 previous state";
CM_ SG_ 1480 EPBL_a180_nextState "Left electric parking brake: a180 next state";
CM_ SG_ 1480 EPBL_a180_panicModeLatched "Left electric parking brake: a180 panic mode latched";
CM_ SG_ 1480 EPBL_a180_activeDecelRequest "Left electric parking brake: a180 active decel request";
CM_ SG_ 1480 EPBL_a181_grade "Left electric parking brake: a181 grade";
CM_ SG_ 1480 EPBL_a181_vcTrailerDetected "Left electric parking brake: a181 vc trailer detected";
CM_ SG_ 1480 EPBL_a181_uiTrailerDetected "Left electric parking brake: a181 ui trailer detected";
CM_ SG_ 1480 EPBL_a181_trailerDetected "Left electric parking brake: a181 trailer detected";
CM_ SG_ 1480 EPBL_a182_epbSystemStatus "Left electric parking brake: a182 epb system status";
CM_ SG_ 1480 EPBL_a182_grade "Left electric parking brake: a182 grade";
CM_ SG_ 1480 EPBL_a182_temperature "Left electric parking brake: a182 temperature";
CM_ SG_ 1480 EPBL_a182_vcTrailerDetected "Left electric parking brake: a182 vc trailer detected";
CM_ SG_ 1480 EPBL_a182_uiTrailerDetected "Left electric parking brake: a182 ui trailer detected";
CM_ SG_ 1480 EPBL_a182_trailerDetected "Left electric parking brake: a182 trailer detected";
CM_ SG_ 1480 EPBL_a183_isRetransmit "Left electric parking brake: a183 is retransmit";
CM_ SG_ 1480 EPBL_a183_localCdpState "Left electric parking brake: a183 local cdp state";
CM_ SG_ 1480 EPBL_a183_remoteCdpState "Left electric parking brake: a183 remote cdp state";
CM_ SG_ 1480 EPBL_a183_espCdpStatus "Left electric parking brake: a183 esp cdp status";
CM_ SG_ 1480 EPBL_a183_esmState "Left electric parking brake: a183 esm state";
CM_ SG_ 1480 EPBL_a183_esmStateRequest "Left electric parking brake: a183 esm state request";
CM_ SG_ 1480 EPBL_a183_esmOperationTrigger "Left electric parking brake: a183 esm operation trigger";
CM_ SG_ 1480 EPBL_a183_cdpNotStopping "Left electric parking brake: a183 cdp not stopping";
CM_ SG_ 1480 EPBL_a183_cdpNotStarting "Left electric parking brake: a183 cdp not starting";
CM_ SG_ 1480 EPBL_a183_remoteEpbDynamic "Left electric parking brake: a183 remote epb dynamic";
CM_ SG_ 1480 EPBL_a183_localEpbDynamic "Left electric parking brake: a183 local epb dynamic";
CM_ SG_ 1480 EPBL_a183_epbmInvalidated "Left electric parking brake: a183 epbm invalidated";
CM_ SG_ 1480 EPBL_a183_espConfirmedInvalid "Left electric parking brake: a183 esp confirmed invalid";
CM_ SG_ 1480 EPBL_a183_brakeFluidConfirmedLow "Left electric parking brake: a183 brake fluid confirmed low";
CM_ SG_ 1480 EPBL_a183_lastRemoteEpbDynamic "Left electric parking brake: a183 last remote epb dynamic";
CM_ SG_ 1480 EPBL_a183_lastLocalEpbDynamic "Left electric parking brake: a183 last local epb dynamic";
CM_ SG_ 1480 EPBL_a183_cdpCannotBeCommanded "Left electric parking brake: a183 cdp cannot be commanded";
CM_ SG_ 1480 EPBL_a183_remoteEpbStatusUnsure "Left electric parking brake: a183 remote epb status unsure";
CM_ SG_ 1480 EPBL_a183_lastLowBrakeFluid "Left electric parking brake: a183 last low brake fluid";
CM_ SG_ 1480 EPBL_a183_espInvalidOrUnsure "Left electric parking brake: a183 esp invalid or unsure";
CM_ SG_ 1480 EPBL_a183_lastFactoryMode "Left electric parking brake: a183 last factory mode";
CM_ SG_ 1480 EPBL_a183_redundantBrakingEnable "Left electric parking brake: a183 redundant braking enabled";
CM_ SG_ 1480 EPBL_a184_esmOpTrigger "Left electric parking brake: a184 esm op trigger";
CM_ SG_ 1480 EPBL_a184_previousState "Left electric parking brake: a184 previous state";
CM_ SG_ 1480 EPBL_a184_nextState "Left electric parking brake: a184 next state";
CM_ SG_ 1480 EPBL_a184_panicModeLatched "Left electric parking brake: a184 panic mode latched";
CM_ SG_ 1480 EPBL_a184_activeDecelRequest "Left electric parking brake: a184 active decel request";
CM_ SG_ 1480 EPBL_a187_esmOpTrigger "Left electric parking brake: a187 esm op trigger";
CM_ SG_ 1480 EPBL_a187_previousState "Left electric parking brake: a187 previous state";
CM_ SG_ 1480 EPBL_a187_nextState "Left electric parking brake: a187 next state";
CM_ SG_ 1480 EPBL_a187_panicModeLatched "Left electric parking brake: a187 panic mode latched";
CM_ SG_ 1480 EPBL_a187_activeDecelRequest "Left electric parking brake: a187 active decel request";
CM_ SG_ 1480 EPBL_a188_esmOpTrigger "Left electric parking brake: a188 esm op trigger";
CM_ SG_ 1480 EPBL_a188_previousState "Left electric parking brake: a188 previous state";
CM_ SG_ 1480 EPBL_a188_nextState "Left electric parking brake: a188 next state";
CM_ SG_ 1480 EPBL_a188_panicModeLatched "Left electric parking brake: a188 panic mode latched";
CM_ SG_ 1480 EPBL_a188_activeDecelRequest "Left electric parking brake: a188 active decel request";
CM_ SG_ 1480 EPBL_a189_esmOpTrigger "Left electric parking brake: a189 esm op trigger";
CM_ SG_ 1480 EPBL_a189_previousState "Left electric parking brake: a189 previous state";
CM_ SG_ 1480 EPBL_a189_nextState "Left electric parking brake: a189 next state";
CM_ SG_ 1480 EPBL_a189_panicModeLatched "Left electric parking brake: a189 panic mode latched";
CM_ SG_ 1480 EPBL_a189_activeDecelRequest "Left electric parking brake: a189 active decel request";
CM_ SG_ 1480 EPBL_a190_esmState "Left electric parking brake: a190 esm state";
CM_ SG_ 1480 EPBL_a190_esmStateRequest "Left electric parking brake: a190 esm state request";
CM_ SG_ 1480 EPBL_a190_faultStatus "Left electric parking brake: a190 fault status";
CM_ SG_ 1480 EPBL_a190_monitorUnitStatus "Left electric parking brake: a190 monitor unit status";
CM_ SG_ 1480 EPBL_a190_monitorFaultStatus "Left electric parking brake: a190 monitor fault status";
CM_ SG_ 1480 EPBL_a190_csmFaultReason "Left electric parking brake: a190 csm fault reason";
CM_ SG_ 1480 EPBL_a190_esmOpTrigger "Left electric parking brake: a190 esm op trigger";
CM_ SG_ 1480 EPBL_a190_nonterminalReason "Left electric parking brake: a190 nonterminal reason";
CM_ SG_ 1480 EPBL_a191_esmState "Left electric parking brake: a191 esm state";
CM_ SG_ 1480 EPBL_a191_esmStateRequest "Left electric parking brake: a191 esm state request";
CM_ SG_ 1480 EPBL_a191_faultStatus "Left electric parking brake: a191 fault status";
CM_ SG_ 1480 EPBL_a191_monitorUnitStatus "Left electric parking brake: a191 monitor unit status";
CM_ SG_ 1480 EPBL_a191_monitorFaultStatus "Left electric parking brake: a191 monitor fault status";
CM_ SG_ 1480 EPBL_a191_csmFaultReason "Left electric parking brake: a191 csm fault reason";
CM_ SG_ 1480 EPBL_a191_esmOpTrigger "Left electric parking brake: a191 esm op trigger";
CM_ SG_ 1480 EPBL_a191_nonterminalReason "Left electric parking brake: a191 nonterminal reason";
CM_ SG_ 1480 EPBL_a202_localEpbConfig "Left electric parking brake: a202 local epb config";
CM_ SG_ 1480 EPBL_a202_remoteEpbConfig "Left electric parking brake: a202 remote epb config";
CM_ SG_ 1480 EPBL_a203_gtwConfig "Left electric parking brake: a203 gtw config";
CM_ SG_ 1480 EPBL_a203_epbConfig "Left electric parking brake: a203 epb config";
CM_ SG_ 1480 EPBL_a210_driverLeftForScore "Left electric parking brake: a210 driver left for score";
CM_ SG_ 1480 EPBL_a210_driverLeftForAllSensor "Left electric parking brake: a210 driver left for all sensors";
CM_ SG_ 1480 EPBL_a210_driverLeftForDoorOpen "Left electric parking brake: a210 driver left for door open";
CM_ SG_ 1480 EPBL_a210_driverLeftForUnbuckled "Left electric parking brake: a210 driver left for unbuckled";
CM_ SG_ 1480 EPBL_a210_driverLeftForInactivit "Left electric parking brake: a210 driver left for inactivity";
CM_ SG_ 1480 EPBL_a210_driverIsLeavingSpeedCl "Left electric parking brake: a210 driver is leaving speed class";
CM_ SG_ 1480 EPBL_a210_localDriverIsLeaving "Left electric parking brake: a210 local driver is leaving";
CM_ SG_ 1480 EPBL_a210_localDriverIsLeavingAn "Left electric parking brake: a210 local driver is leaving any speed";
CM_ SG_ 1480 EPBL_a210_remoteDriverIsLeaving "Left electric parking brake: a210 remote driver is leaving";
CM_ SG_ 1480 EPBL_a210_remoteDriverIsLeavingA "Left electric parking brake: a210 remote driver is leaving any speed";
CM_ SG_ 1480 EPBL_a210_primaryDriverDoorClose "Left electric parking brake: a210 primary driver door closed";
CM_ SG_ 1480 EPBL_a210_secondaryDriverDoorClo "Left electric parking brake: a210 secondary driver door closed";
CM_ SG_ 1480 EPBL_a210_driverBuckled "Left electric parking brake: a210 driver buckled";
CM_ SG_ 1480 EPBL_a210_driverSeated "Left electric parking brake: a210 driver seated";
CM_ SG_ 1480 EPBL_a225_esmOpTrigger "Left electric parking brake: a225 esm op trigger";
CM_ SG_ 1480 EPBL_a225_previousState "Left electric parking brake: a225 previous state";
CM_ SG_ 1480 EPBL_a225_nextState "Left electric parking brake: a225 next state";
CM_ SG_ 1480 EPBL_a225_panicModeLatched "Left electric parking brake: a225 panic mode latched";
CM_ SG_ 1480 EPBL_a225_activeDecelRequest "Left electric parking brake: a225 active decel request";
CM_ SG_ 1480 EPBL_a241_desiredState "Left electric parking brake: a241 desired state";
CM_ SG_ 1480 EPBL_a241_currentState "Left electric parking brake: a241 current state";
CM_ SG_ 1480 EPBL_a241_diKeepAlive "Left electric parking brake: a241 di keep alive";
CM_ SG_ 1480 EPBL_a241_epbSysStatus "Left electric parking brake: a241 epb sys status";
CM_ SG_ 1480 EPBL_a241_vehiclePowerState "Left electric parking brake: a241 vehicle power state";
CM_ SG_ 1480 EPBL_a241_highCurrent "Left electric parking brake: a241 high current";
CM_ SG_ 1480 EPBL_a241_monitorDataGood "Left electric parking brake: a241 monitor data good";
CM_ SG_ 1480 EPBL_a241_hasLockoutRequest "Left electric parking brake: a241 has lockout request";
CM_ SG_ 1480 EPBL_a242_hvcDesiredState "Left electric parking brake: a242 hvc desired state";
CM_ SG_ 1480 EPBL_a242_hvcCurrentState "Left electric parking brake: a242 hvc current state";
CM_ SG_ 1480 EPBL_a242_contDesiredState "Left electric parking brake: a242 cont desired state";
CM_ SG_ 1480 EPBL_a242_contCurrentState "Left electric parking brake: a242 cont current state";
CM_ SG_ 1480 EPBL_a242_hvState "Left electric parking brake: a242 hv state";
CM_ SG_ 1480 EPBL_a242_vehiclePowerState "Left electric parking brake: a242 vehicle power state";
CM_ SG_ 1480 EPBL_a242_highCurrent "Left electric parking brake: a242 high current";
CM_ SG_ 1480 EPBL_a242_monitorDataGood "Left electric parking brake: a242 monitor data good";
CM_ SG_ 1480 EPBL_a242_hasLockoutRequest "Left electric parking brake: a242 has lockout request";
CM_ SG_ 1480 EPBL_a243_brakeMasterCylPress "Left electric parking brake: a243 brake master cyl press";
CM_ SG_ 1480 EPBL_a243_brakeMasterCylPressQF "Left electric parking brake: a243 brake master cyl press QF";
CM_ SG_ 1480 EPBL_a243_drivetrainType "Left electric parking brake: a243 drivetrain type";
CM_ SG_ 1480 EPBL_a243_DIR1torqueActual "Left electric parking brake: a243 dir1torque actual";
CM_ SG_ 1480 EPBL_a243_DIR2torqueActual "Left electric parking brake: a243 dir2torque actual";
CM_ SG_ 1480 EPBL_a243_DIFtorqueActual "Left electric parking brake: a243 DI ftorque actual";
CM_ SG_ 1480 EPBL_a243_vehicleSpeed "Left electric parking brake: a243 vehicle speed";
CM_ SG_ 1480 EPBL_a243_tempAmbient "Left electric parking brake: a243 temp ambient";
CM_ SG_ 1480 EPBL_a243_thermistorTMin "Left electric parking brake: a243 thermistor t min";
CM_ SG_ 1480 EPBL_a243_wiperSpeed "Left electric parking brake: a243 wiper speed";
CM_ SG_ 1480 EPBL_a243_vehiclePowerState "Left electric parking brake: a243 vehicle power state";
CM_ SG_ 1480 EPBL_a243_brakeDiscWipingActive "Left electric parking brake: a243 brake disc wiping active";
CM_ SG_ 1480 EPBL_a244_permissiveMode "Left electric parking brake: a244 permissive mode";
CM_ SG_ 1480 EPBL_a246_previousState "Left electric parking brake: a246 previous state";
CM_ SG_ 1480 EPBL_a246_nextState "Left electric parking brake: a246 next state";
CM_ SG_ 1480 EPBL_a246_esmStateRequest "Left electric parking brake: a246 esm state request";
CM_ SG_ 1480 EPBL_a246_faultStatus "Left electric parking brake: a246 fault status";
CM_ SG_ 1480 EPBL_a246_esmOpTrigger "Left electric parking brake: a246 esm op trigger";
CM_ SG_ 1480 EPBL_a247_esmState "Left electric parking brake: a247 esm state";
CM_ SG_ 1480 EPBL_a247_esmStateRequest "Left electric parking brake: a247 esm state request";
CM_ SG_ 1480 EPBL_a247_faultStatus "Left electric parking brake: a247 fault status";
CM_ SG_ 1480 EPBL_a247_monitorUnitStatus "Left electric parking brake: a247 monitor unit status";
CM_ SG_ 1480 EPBL_a247_monitorFaultStatus "Left electric parking brake: a247 monitor fault status";
CM_ SG_ 1480 EPBL_a247_csmFaultReason "Left electric parking brake: a247 csm fault reason";
CM_ SG_ 1480 EPBL_a247_esmOpTrigger "Left electric parking brake: a247 esm op trigger";
CM_ SG_ 1480 EPBL_a247_nonterminalReason "Left electric parking brake: a247 nonterminal reason";
CM_ SG_ 1480 EPBL_a248_esmState "Left electric parking brake: a248 esm state";
CM_ SG_ 1480 EPBL_a248_esmStateRequest "Left electric parking brake: a248 esm state request";
CM_ SG_ 1480 EPBL_a248_faultStatus "Left electric parking brake: a248 fault status";
CM_ SG_ 1480 EPBL_a248_monitorUnitStatus "Left electric parking brake: a248 monitor unit status";
CM_ SG_ 1480 EPBL_a248_monitorFaultStatus "Left electric parking brake: a248 monitor fault status";
CM_ SG_ 1480 EPBL_a248_csmFaultReason "Left electric parking brake: a248 csm fault reason";
CM_ SG_ 1480 EPBL_a248_esmOpTrigger "Left electric parking brake: a248 esm op trigger";
CM_ SG_ 1480 EPBL_a248_nonterminalReason "Left electric parking brake: a248 nonterminal reason";
CM_ SG_ 1480 EPBL_a249_previousState "Left electric parking brake: a249 previous state";
CM_ SG_ 1480 EPBL_a249_nextState "Left electric parking brake: a249 next state";
CM_ SG_ 1480 EPBL_a249_esmStateRequest "Left electric parking brake: a249 esm state request";
CM_ SG_ 1480 EPBL_a249_faultStatus "Left electric parking brake: a249 fault status";
CM_ SG_ 1480 EPBL_a249_esmOpTrigger "Left electric parking brake: a249 esm op trigger";
CM_ SG_ 1480 EPBL_a250_esmSpeedClass "Left electric parking brake: a250 esm speed class";
CM_ SG_ 1480 EPBL_a250_esmOperationTrigger "Left electric parking brake: a250 esm operation trigger";
CM_ SG_ 1480 EPBL_a250_isJumpPostTripped "Left electric parking brake: a250 is jump post tripped";
CM_ SG_ 1480 EPBL_a251_currentVariance "Left electric parking brake: a251 current variance";
CM_ SG_ 1480 EPBL_a251_pistonPosition "Left electric parking brake: a251 piston position";
CM_ SG_ 1480 EPBL_a251_temperature "Left electric parking brake: a251 temperature";
CM_ SG_ 1480 EPBL_a272_expectedState "Left electric parking brake: a272 expected state";
CM_ SG_ 1480 EPBL_a272_actualState "Left electric parking brake: a272 actual state";
CM_ SG_ 1480 EPBL_a300_harnessId "Left electric parking brake: a300 harness id";
CM_ SG_ 1480 EPBL_a300_subUsageId "Left electric parking brake: a300 sub usage id";
CM_ SG_ 1480 EPBL_a301_setSpeed "Left electric parking brake: a301 set speed";
CM_ SG_ 1480 EPBL_a301_oocConfidence "Left electric parking brake: a301 ooc confidence";
CM_ SG_ 1480 EPBL_a301_oocDistanceFiltered "Left electric parking brake: a301 ooc distance filtered";
CM_ SG_ 1480 EPBL_a302_pistonPosition "Left electric parking brake: a302 piston position";
CM_ SG_ 1480 EPBL_a302_deltaCurrent "Left electric parking brake: a302 delta current";
CM_ SG_ 1480 EPBL_a303_currentVariance "Left electric parking brake: a303 current variance";
CM_ SG_ 1480 EPBL_a303_pistonPosition "Left electric parking brake: a303 piston position";
CM_ SG_ 1480 EPBL_a303_temperature "Left electric parking brake: a303 temperature";
CM_ SG_ 1480 EPBL_a350_ensPeriod "Left electric parking brake: a350 ens period";
CM_ SG_ 1480 EPBL_a350_ensDuty "Left electric parking brake: a350 ens duty";
CM_ SG_ 1480 EPBL_a350_ensTimedOut "Left electric parking brake: a350 ens timed out";
CM_ SG_ 1480 EPBL_a355_brakeHwConfig "Left electric parking brake: a355 brake hw config";
CM_ SG_ 1480 EPBL_a355_epbHwConfig "Left electric parking brake: a355 epb hw config";
CM_ SG_ 1480 EPBL_a357_epbSystemStatus "Left electric parking brake: a357 epb system status";
CM_ SG_ 1480 EPBL_a357_grade "Left electric parking brake: a357 grade";
CM_ SG_ 1480 EPBL_a357_ambientTemp "Left electric parking brake: a357 ambient temp";
CM_ SG_ 1480 EPBL_a357_brakeTemp "Left electric parking brake: a357 brake temp";
CM_ SG_ 1480 EPBL_a357_vcTrailerDetected "Left electric parking brake: a357 vc trailer detected";
CM_ SG_ 1480 EPBL_a357_uiTrailerDetected "Left electric parking brake: a357 ui trailer detected";
CM_ SG_ 1480 EPBL_a357_trailerDetected "Left electric parking brake: a357 trailer detected";
CM_ SG_ 1480 EPBL_a358_epbSystemStatus "Left electric parking brake: a358 epb system status";
CM_ SG_ 1480 EPBL_a358_grade "Left electric parking brake: a358 grade";
CM_ SG_ 1480 EPBL_a358_ambientTemp "Left electric parking brake: a358 ambient temp";
CM_ SG_ 1480 EPBL_a358_brakeTemp "Left electric parking brake: a358 brake temp";
CM_ SG_ 1480 EPBL_a358_vcTrailerDetected "Left electric parking brake: a358 vc trailer detected";
CM_ SG_ 1480 EPBL_a358_uiTrailerDetected "Left electric parking brake: a358 ui trailer detected";
CM_ SG_ 1480 EPBL_a358_trailerDetected "Left electric parking brake: a358 trailer detected";
CM_ SG_ 1480 EPBL_a365_epbSystemStatus "Left electric parking brake: a365 epb system status";
CM_ SG_ 1480 EPBL_a365_grade "Left electric parking brake: a365 grade";
CM_ SG_ 1480 EPBL_a365_ambientTemp "Left electric parking brake: a365 ambient temp";
CM_ SG_ 1480 EPBL_a365_vcTrailerDetected "Left electric parking brake: a365 vc trailer detected";
CM_ SG_ 1480 EPBL_a365_uiTrailerDetected "Left electric parking brake: a365 ui trailer detected";
CM_ SG_ 1480 EPBL_a365_trailerDetected "Left electric parking brake: a365 trailer detected";
CM_ SG_ 1480 EPBL_a366_epbSystemStatus "Left electric parking brake: a366 epb system status";
CM_ SG_ 1480 EPBL_a366_grade "Left electric parking brake: a366 grade";
CM_ SG_ 1480 EPBL_a366_ambientTemp "Left electric parking brake: a366 ambient temp";
CM_ SG_ 1480 EPBL_a366_vcTrailerDetected "Left electric parking brake: a366 vc trailer detected";
CM_ SG_ 1480 EPBL_a366_uiTrailerDetected "Left electric parking brake: a366 ui trailer detected";
CM_ SG_ 1480 EPBL_a366_trailerDetected "Left electric parking brake: a366 trailer detected";
CM_ BO_ 968 "Left electric parking brake message: alert matrix";
CM_ SG_ 968 EPBL_matrixIndex "Left electric parking brake: matrix index";
CM_ SG_ 968 EPBL_a001_WatchdogReset "Left electric parking brake: a001 watchdog reset";
CM_ SG_ 968 EPBL_a002_PowerLossReset "Left electric parking brake: a002 power loss reset";
CM_ SG_ 968 EPBL_a003_SWAssertion "Left electric parking brake: a003 SW assertion";
CM_ SG_ 968 EPBL_a005_CANTXError "Left electric parking brake: a005 CANTX error";
CM_ SG_ 968 EPBL_a006_CANTX_cyclicError "Left electric parking brake: a006 CANTX cyclic error";
CM_ SG_ 968 EPBL_a012_CPUReset "Left electric parking brake: a012 CPU reset";
CM_ SG_ 968 EPBL_a013_AlertManagerFault "Left electric parking brake: a013 alert manager fault";
CM_ SG_ 968 EPBL_a015_NVMMError "Left electric parking brake: a015 NVMM error";
CM_ SG_ 968 EPBL_a016_NVMMRecordError "Left electric parking brake: a016 NVMM record error";
CM_ SG_ 968 EPBL_a021_TaskSchedulerError "Left electric parking brake: a021 task scheduler error";
CM_ SG_ 968 EPBL_a022_TaskInitError "Left electric parking brake: a022 task init error";
CM_ SG_ 968 EPBL_a029_CoreDump "Left electric parking brake: a029 core dump";
CM_ SG_ 968 EPBL_a030_ECULogUploadRequest "Left electric parking brake: a030 ECU log upload request";
CM_ SG_ 968 EPBL_a031_UDSActive "Left electric parking brake: a031 UDS active";
CM_ SG_ 968 EPBL_a041_HighCPULoad "Left electric parking brake: a041 high CPU load";
CM_ SG_ 968 EPBL_a042_HighStackUsage "Left electric parking brake: a042 high stack usage";
CM_ SG_ 968 EPBL_a043_Task1msError "Left electric parking brake: a043 task1ms error";
CM_ SG_ 968 EPBL_a044_Task10msError "Left electric parking brake: a044 task10ms error";
CM_ SG_ 968 EPBL_a045_Task100msError "Left electric parking brake: a045 task100ms error";
CM_ SG_ 968 EPBL_a046_Task1000msError "Left electric parking brake: a046 task1000ms error";
CM_ SG_ 968 EPBL_a057_HVP_MIA "Left electric parking brake: a057 HVP MIA";
CM_ SG_ 968 EPBL_a058_inputRHighSyncDebug "Left electric parking brake: a058 input r high sync debug";
CM_ SG_ 968 EPBL_a059_inputResistanceHigh "Left electric parking brake: a059 input resistance high";
CM_ SG_ 968 EPBL_a060_engineeringBuild "Left electric parking brake: a060 engineering build";
CM_ SG_ 968 EPBL_a061_XCPConnected "Left electric parking brake: a061 XCP connected";
CM_ SG_ 968 EPBL_a062_XCPWasConnected "Left electric parking brake: a062 XCP was connected";
CM_ SG_ 968 EPBL_a063_SwitchFault "Left electric parking brake: a063 switch fault";
CM_ SG_ 968 EPBL_a064_busSleepReqTimeout "Left electric parking brake: a064 bus sleep req timeout";
CM_ SG_ 968 EPBL_a081_APP_MIA "Left electric parking brake: a081 APP MIA";
CM_ SG_ 968 EPBL_a082_VCRIGHT_IPC_MIA "Left electric parking brake: a082 VCRIGHT IPC MIA";
CM_ SG_ 968 EPBL_a083_VCLEFT_IPC_MIA "Left electric parking brake: a083 VCLEFT IPC MIA";
CM_ SG_ 968 EPBL_a084_TPMS_MIA "Left electric parking brake: a084 TPMS MIA";
CM_ SG_ 968 EPBL_a085_CCCM_MIA "Left electric parking brake: a085 CCCM MIA";
CM_ SG_ 968 EPBL_a086_VCBATT_MIA "Left electric parking brake: a086 VCBATT MIA";
CM_ SG_ 968 EPBL_a087_DIREL_MIA "Left electric parking brake: a087 DIREL MIA";
CM_ SG_ 968 EPBL_a088_DIRER_MIA "Left electric parking brake: a088 DIRER MIA";
CM_ SG_ 968 EPBL_a089_IBST_MIA "Left electric parking brake: a089 IBST MIA";
CM_ SG_ 968 EPBL_a090_APS_MIA "Left electric parking brake: a090 APS MIA";
CM_ SG_ 968 EPBL_a091_CMPD_MIA "Left electric parking brake: a091 CMPD MIA";
CM_ SG_ 968 EPBL_a092_VCSEATD_MIA "Left electric parking brake: a092 VCSEATD MIA";
CM_ SG_ 968 EPBL_a093_VCSEATP_MIA "Left electric parking brake: a093 VCSEATP MIA";
CM_ SG_ 968 EPBL_a094_EPAS3P_MIA "Left electric parking brake: a094 EPAS3 p MIA";
CM_ SG_ 968 EPBL_a095_CHG_MIA "Left electric parking brake: a095 CHG MIA";
CM_ SG_ 968 EPBL_a096_OCS1P_MIA "Left electric parking brake: a096 OCS1 p MIA";
CM_ SG_ 968 EPBL_a097_CMP_MIA "Left electric parking brake: a097 CMP MIA";
CM_ SG_ 968 EPBL_a098_DIR_MIA "Left electric parking brake: a098 DIR MIA";
CM_ SG_ 968 EPBL_a099_PARK_MIA "Left electric parking brake: a099 PARK MIA";
CM_ SG_ 968 EPBL_a100_CANbus_MIA "Left electric parking brake: a100 CA nbus MIA";
CM_ SG_ 968 EPBL_a101_PM_MIA "Left electric parking brake: a101 PM MIA";
CM_ SG_ 968 EPBL_a102_PTC_MIA "Left electric parking brake: a102 PTC MIA";
CM_ SG_ 968 EPBL_a103_CP_MIA "Left electric parking brake: a103 CP MIA";
CM_ SG_ 968 EPBL_a104_DAS_MIA "Left electric parking brake: a104 DAS MIA";
CM_ SG_ 968 EPBL_a105_TAS_MIA "Left electric parking brake: a105 TAS MIA";
CM_ SG_ 968 EPBL_a106_PCS_MIA "Left electric parking brake: a106 PCS MIA";
CM_ SG_ 968 EPBL_a107_BMS_MIA "Left electric parking brake: a107 BMS MIA";
CM_ SG_ 968 EPBL_a108_DIF_MIA "Left electric parking brake: a108 DIF MIA";
CM_ SG_ 968 EPBL_a109_RCM_MIA "Left electric parking brake: a109 RCM MIA";
CM_ SG_ 968 EPBL_a110_GTW_MIA "Left electric parking brake: a110 GTW MIA";
CM_ SG_ 968 EPBL_a111_EPBR_MIA "Left electric parking brake: a111 EPBR MIA";
CM_ SG_ 968 EPBL_a112_EPBL_MIA "Left electric parking brake: a112 EPBL MIA";
CM_ SG_ 968 EPBL_a113_UI_MIA "Left electric parking brake: a113 UI MIA";
CM_ SG_ 968 EPBL_a114_ESP_MIA "Left electric parking brake: a114 ESP MIA";
CM_ SG_ 968 EPBL_a115_VCSEC_MIA "Left electric parking brake: a115 VCSEC MIA";
CM_ SG_ 968 EPBL_a116_VCRIGHT_MIA "Left electric parking brake: a116 VCRIGHT MIA";
CM_ SG_ 968 EPBL_a117_VCLEFT_MIA "Left electric parking brake: a117 VCLEFT MIA";
CM_ SG_ 968 EPBL_a118_VCFRONT_MIA "Left electric parking brake: a118 VCFRONT MIA";
CM_ SG_ 968 EPBL_a119_SCCM_MIA "Left electric parking brake: a119 SCCM MIA";
CM_ SG_ 968 EPBL_a120_DI_DRIVE_MIA "Left electric parking brake: a120 DI DRIVE MIA";
CM_ SG_ 968 EPBL_a121_nDriveFault "Left electric parking brake: a121 n drive fault";
CM_ SG_ 968 EPBL_a122_Oc "Left electric parking brake: a122 oc";
CM_ SG_ 968 EPBL_a123_Uc "Left electric parking brake: a123 uc";
CM_ SG_ 968 EPBL_a124_calOutOfBounds "Left electric parking brake: a124 cal out of bounds";
CM_ SG_ 968 EPBL_a125_IdleVMismatch "Left electric parking brake: a125 idle v mismatch";
CM_ SG_ 968 EPBL_a126_MotorNVoltLow "Left electric parking brake: a126 motor n volt low";
CM_ SG_ 968 EPBL_a127_MotorNVoltHigh "Left electric parking brake: a127 motor n volt high";
CM_ SG_ 968 EPBL_a128_MotorPVoltHigh "Left electric parking brake: a128 motor p volt high";
CM_ SG_ 968 EPBL_a129_ICR_MIA "Left electric parking brake: a129 ICR MIA";
CM_ SG_ 968 EPBL_a130_BB_MIA "Left electric parking brake: a130 BB MIA";
CM_ SG_ 968 EPBL_a131_RCU_MIA "Left electric parking brake: a131 RCU MIA";
CM_ SG_ 968 EPBL_a132_VCBATT1_MIA "Left electric parking brake: a132 VCBATT1 MIA";
CM_ SG_ 968 EPBL_a134_NvOv "Left electric parking brake: a134 nv ov";
CM_ SG_ 968 EPBL_a135_NvUv "Left electric parking brake: a135 nv uv";
CM_ SG_ 968 EPBL_a136_PvOv "Left electric parking brake: a136 pv ov";
CM_ SG_ 968 EPBL_a137_PvUv "Left electric parking brake: a137 pv uv";
CM_ SG_ 968 EPBL_a138_NvmDualFailure "Left electric parking brake: a138 nvm dual failure";
CM_ SG_ 968 EPBL_a139_NvmRedundancyLoss "Left electric parking brake: a139 nvm redundancy loss";
CM_ SG_ 968 EPBL_a140_NvmSlowWrite "Left electric parking brake: a140 nvm slow write";
CM_ SG_ 968 EPBL_a141_invalidState "Left electric parking brake: a141 invalid state";
CM_ SG_ 968 EPBL_a170_12vOv "Left electric parking brake: a170 12v ov";
CM_ SG_ 968 EPBL_a171_12vUv "Left electric parking brake: a171 12v uv";
CM_ SG_ 968 EPBL_a172_SPI_MIA "Left electric parking brake: a172 SPI MIA";
CM_ SG_ 968 EPBL_a173_hiCurrentMissing "Left electric parking brake: a173 hi current missing";
CM_ SG_ 968 EPBL_a174_csmReleaseFailed "Left electric parking brake: a174 csm release failed";
CM_ SG_ 968 EPBL_a175_csmReleaseRetry "Left electric parking brake: a175 csm release retry";
CM_ SG_ 968 EPBL_a176_csmApplyFailed "Left electric parking brake: a176 csm apply failed";
CM_ SG_ 968 EPBL_a177_csmApplyRetry "Left electric parking brake: a177 csm apply retry";
CM_ SG_ 968 EPBL_a178_caliperStateUnknown "Left electric parking brake: a178 caliper state unknown";
CM_ SG_ 968 EPBL_a179_epbProblem "Left electric parking brake: a179 epb problem";
CM_ SG_ 968 EPBL_a180_dynamicActive "Left electric parking brake: a180 dynamic active";
CM_ SG_ 968 EPBL_a181_TooSteepGradeToPark "Left electric parking brake: a181 too steep grade to park";
CM_ SG_ 968 EPBL_a182_OneEPBAppliedUnsecEnv "Left electric parking brake: a182 one EPB applied unsec env";
CM_ SG_ 968 EPBL_a183_cdpNotAvailable "Left electric parking brake: a183 cdp not available";
CM_ SG_ 968 EPBL_a184_dynamicParkAbort "Left electric parking brake: a184 dynamic park abort";
CM_ SG_ 968 EPBL_a185_summonAborted "Left electric parking brake: a185 summon aborted";
CM_ SG_ 968 EPBL_a186_externalParkAbort "Left electric parking brake: a186 external park abort";
CM_ SG_ 968 EPBL_a187_cdpDynamic "Left electric parking brake: a187 cdp dynamic";
CM_ SG_ 968 EPBL_a188_epbDynamic "Left electric parking brake: a188 epb dynamic";
CM_ SG_ 968 EPBL_a189_epbDynamicParkCanceled "Left electric parking brake: a189 epb dynamic park canceled";
CM_ SG_ 968 EPBL_a190_csmApplyDegraded "Left electric parking brake: a190 csm apply degraded";
CM_ SG_ 968 EPBL_a191_csmReleaseDegraded "Left electric parking brake: a191 csm release degraded";
CM_ SG_ 968 EPBL_a195_parkForDriverIsLeaving "Left electric parking brake: a195 park for driver is leaving";
CM_ SG_ 968 EPBL_a196_freeRollModeActive "Left electric parking brake: a196 free roll mode active";
CM_ SG_ 968 EPBL_a197_freeRollModeAtSpeed "Left electric parking brake: a197 free roll mode at speed";
CM_ SG_ 968 EPBL_a198_holdClampComplete "Left electric parking brake: a198 hold clamp complete";
CM_ SG_ 968 EPBL_a200_PmUnparkNotAllowed "Left electric parking brake: a200 pm unpark not allowed";
CM_ SG_ 968 EPBL_a202_remoteEpbConfigIncompa "Left electric parking brake: a202 remote epb config incompatible";
CM_ SG_ 968 EPBL_a203_hwBrakeTypeMismatch "Left electric parking brake: a203 hw brake type mismatch";
CM_ SG_ 968 EPBL_a210_parkForDriverIsLeaving "Left electric parking brake: a210 park for driver is leaving debug";
CM_ SG_ 968 EPBL_a216_SPI_MIA_debugData1 "Left electric parking brake: a216 SPI MIA debug data1";
CM_ SG_ 968 EPBL_a217_SPI_MIA_debugData2 "Left electric parking brake: a217 SPI MIA debug data2";
CM_ SG_ 968 EPBL_a225_epbActiveDecel "Left electric parking brake: a225 epb active decel";
CM_ SG_ 968 EPBL_a241_diOutputLocked "Left electric parking brake: a241 di output locked";
CM_ SG_ 968 EPBL_a242_hvOutputLocked "Left electric parking brake: a242 hv output locked";
CM_ SG_ 968 EPBL_a243_bdwUnavailable "Left electric parking brake: a243 bdw unavailable";
CM_ SG_ 968 EPBL_a244_WinchModeActive "Left electric parking brake: a244 winch mode active";
CM_ SG_ 968 EPBL_a245_serviceModeActive "Signal reported by Left electric parking brake";
CM_ SG_ 968 EPBL_a246_idleFaultApply "Left electric parking brake: a246 idle fault apply";
CM_ SG_ 968 EPBL_a247_csmDynamicApplyRetry "Left electric parking brake: a247 csm dynamic apply retry";
CM_ SG_ 968 EPBL_a248_csmDynamicApplyFailed "Left electric parking brake: a248 csm dynamic apply failed";
CM_ SG_ 968 EPBL_a249_idleFaultRelease "Left electric parking brake: a249 idle fault release";
CM_ SG_ 968 EPBL_a250_WinchModeCanceled "Left electric parking brake: a250 winch mode canceled";
CM_ SG_ 968 EPBL_a251_currentVarianceHigh "Left electric parking brake: a251 current variance high";
CM_ SG_ 968 EPBL_a252_winchModePending "Left electric parking brake: a252 winch mode pending";
CM_ SG_ 968 EPBL_a253_esmReleaseBlocked "Left electric parking brake: a253 esm release blocked";
CM_ SG_ 968 EPBL_a254_showStalkParkButtonFau "Left electric parking brake: a254 show stalk park button fault on ui";
CM_ SG_ 968 EPBL_a256_epbSystemApply "Left electric parking brake: a256 epb system apply";
CM_ SG_ 968 EPBL_a261_winchModeWithoutSteeri "Left electric parking brake: a261 winch mode without steering";
CM_ SG_ 968 EPBL_a262_cannotPrepareWinchMode "Left electric parking brake: a262 cannot prepare winch mode";
CM_ SG_ 968 EPBL_a263_epbRecoveryPark "Left electric parking brake: a263 epb recovery park";
CM_ SG_ 968 EPBL_a264_winchModeDeactivated "Left electric parking brake: a264 winch mode deactivated";
CM_ SG_ 968 EPBL_a272_vhclPwrStateMsmtch "Left electric parking brake: a272 vhcl pwr state msmtch";
CM_ SG_ 968 EPBL_a300_leftRightConfusion "Left electric parking brake: a300 left right confusion";
CM_ SG_ 968 EPBL_a301_oocSpeedViolation "Left electric parking brake: a301 ooc speed violation";
CM_ SG_ 968 EPBL_a302_csmLongRelease "Left electric parking brake: a302 csm long release";
CM_ SG_ 968 EPBL_a303_clampingOccuredEarly "Left electric parking brake: a303 clamping occured early";
CM_ SG_ 968 EPBL_a304_rearSeatControllerEFus "Left electric parking brake: a304 rear seat controller e fuse trip";
CM_ SG_ 968 EPBL_a305_premiumAmpEFuseTrip "Left electric parking brake: a305 premium amp e fuse trip";
CM_ SG_ 968 EPBL_a350_ensOutOfRange "Left electric parking brake: a350 ens out of range";
CM_ SG_ 968 EPBL_a352_audioCurrentSpikeData "Left electric parking brake: a352 audio current spike data";
CM_ SG_ 968 EPBL_a353_missingSpeedUnableToPa "Left electric parking brake: a353 missing speed unable to park";
CM_ SG_ 968 EPBL_a354_parkedForLowBrakeFluid "Left electric parking brake: a354 parked for low brake fluid mode";
CM_ SG_ 968 EPBL_a355_brakeHwAndEpbHwMismatc "Left electric parking brake: a355 brake hw and epb hw mismatch";
CM_ SG_ 968 EPBL_a356_parkingForStationaryDe "Left electric parking brake: a356 parking for stationary detect";
CM_ SG_ 968 EPBL_a357_brakesTooHotForSlope "Left electric parking brake: a357 brakes too hot for slope";
CM_ SG_ 968 EPBL_a358_brakesTooHotForSlopeWi "Left electric parking brake: a358 brakes too hot for slope with only one epb";
CM_ SG_ 968 EPBL_a360_ibstBrakeSwitchInvalid "Left electric parking brake: a360 ibst brake switch invalid";
CM_ SG_ 968 EPBL_a361_espBrakeSwitchInvalid "Left electric parking brake: a361 esp brake switch invalid";
CM_ SG_ 968 EPBL_a362_ibstPressedEspNotPress "Left electric parking brake: a362 ibst pressed esp not pressed mismatch";
CM_ SG_ 968 EPBL_a363_ibstNotPressedEspPress "Left electric parking brake: a363 ibst not pressed esp pressed mismatch";
CM_ SG_ 968 EPBL_a364_espMasterCylCompOverTh "Left electric parking brake: a364 esp master cyl comp over threshold";
CM_ SG_ 968 EPBL_a365_TooSteepToParkWithTrai "Left electric parking brake: a365 too steep to park with trailer warning";
CM_ SG_ 968 EPBL_a366_TooSteepToParkWithTrai "Left electric parking brake: a366 too steep to park with trailer un sec env";
CM_ BO_ 1992 "Left electric parking brake message: info";
CM_ SG_ 1992 EPBL_infoIndex "Left electric parking brake: info index";
CM_ SG_ 1992 EPBL_infoBuildType "Left electric parking brake: info build type";
CM_ SG_ 1992 EPBL_infoBuildConfigId "Left electric parking brake: info build config id";
CM_ SG_ 1992 EPBL_infoHardwareId "Left electric parking brake: info hardware id";
CM_ SG_ 1992 EPBL_infoComponentId "Left electric parking brake: info component id";
CM_ SG_ 1992 EPBL_infoPcbaId "Left electric parking brake: info pcba id";
CM_ SG_ 1992 EPBL_infoAssemblyId "Left electric parking brake: info assembly id";
CM_ SG_ 1992 EPBL_infoUsageId "Left electric parking brake: info usage id";
CM_ SG_ 1992 EPBL_infoSubUsageId "Left electric parking brake: info sub usage id";
CM_ SG_ 1992 EPBL_infoAppCrc "Left electric parking brake: info app crc";
CM_ SG_ 1992 EPBL_infoAppGitHash "Left electric parking brake: info app git hash";
CM_ SG_ 1992 EPBL_infoBootGitHash "Left electric parking brake: info boot git hash";
CM_ SG_ 1992 EPBL_infoPlatformType "Left electric parking brake: info platform type";
CM_ SG_ 1992 EPBL_infoBootUdsProtoVersion "Left electric parking brake: info boot uds proto version";
CM_ SG_ 1992 EPBL_infoBootCrc "Left electric parking brake: info boot crc";
CM_ BO_ 648 "Left electric parking brake message: internal status";
CM_ SG_ 648 EPBL_unitStatus "Electronic Parking Brake's unit state.";
CM_ SG_ 648 EPBL_unitFaultStatus "Left electric parking brake: unit fault status";
CM_ SG_ 648 EPBL_summonState "Left electric parking brake: summon state";
CM_ SG_ 648 EPBL_disconnected "Left electric parking brake: disconnected";
CM_ SG_ 648 EPBL_pistonTouchingRotor "Left electric parking brake: piston touching rotor";
CM_ SG_ 648 EPBL_csmFaultReason "Left electric parking brake: csm fault reason";
CM_ SG_ 648 EPBL_esmOperationTrigger "Left electric parking brake: esm operation trigger";
CM_ SG_ 648 EPBL_summonFaultReason "Error code associated with previous summon failure.";
CM_ SG_ 648 EPBL_localServiceModeActive "Signal reported by Left electric parking brake";
CM_ SG_ 648 EPBL_localCdpState "Left electric parking brake: local cdp state";
CM_ SG_ 648 EPBL_chimeRequestLocal "Left electric parking brake: chime request local";
CM_ SG_ 648 EPBL_telltaleLocal "Left electric parking brake: telltale local";
CM_ SG_ 648 EPBL_driverIsLeavingLocal "Left electric parking brake: driver is leaving local";
CM_ SG_ 648 EPBL_driverIsLeavingAnySpeedLoca "Left electric parking brake: driver is leaving any speed local";
CM_ SG_ 648 EPBL_internalCDPRequest "Left electric parking brake: internal CDP request";
CM_ SG_ 648 EPBL_esmSpeedClass "Left electric parking brake: esm speed class";
CM_ SG_ 648 EPBL_learnedEpbConfig "Left electric parking brake: learned epb config";
CM_ SG_ 648 EPBL_internalStatusCounter "Left electric parking brake: internal status counter";
CM_ SG_ 648 EPBL_internalStatusChecksum "Left electric parking brake: internal status checksum";
CM_ BO_ 743 "Left electric parking brake message: seat status3";
CM_ SG_ 743 EPBL_frontSeatCushionFanCur "Left electric parking brake: front seat cushion fan cur";
CM_ SG_ 743 EPBL_frontSeatBackrestFanCur "Left electric parking brake: front seat backrest fan cur";
CM_ SG_ 743 EPBL_frontSeatCushionFanDuty "Left electric parking brake: front seat cushion fan duty";
CM_ SG_ 743 EPBL_frontSeatCushionFanEn "Left electric parking brake: front seat cushion fan en";
CM_ SG_ 743 EPBL_frontSeatBackrestFanEn "Left electric parking brake: front seat backrest fan en";
CM_ SG_ 743 EPBL_frontSeatBackrestFanDuty "Left electric parking brake: front seat backrest fan duty";
CM_ BO_ 681 "Left electric parking brake message: status";
CM_ SG_ 681 EPBL_systemStatus "Coordinated state representing the vehicle level parking brake state.";
CM_ SG_ 681 EPBL_freeRollModeStatus "Left electric parking brake: free roll mode status";
CM_ SG_ 681 EPBL_driverIsLeaving "Left electric parking brake: driver is leaving";
CM_ SG_ 681 EPBL_driverIsLeavingAnySpeed "Left electric parking brake: driver is leaving any speed";
CM_ SG_ 681 EPBL_systemCdpAvailable "Left electric parking brake: system cdp available";
CM_ SG_ 681 EPBL_chimeRequest "Left electric parking brake: chime request";
CM_ SG_ 681 EPBL_telltale "Controls the telltale illumination on the instrument cluster.";
CM_ SG_ 681 EPBL_contactorCycleNotNeededForW "Left electric parking brake: contactor cycle not needed for winch entry";
CM_ SG_ 681 EPBL_redundantBrakingEnabled "Left electric parking brake: redundant braking enabled";
CM_ SG_ 681 EPBL_summonEnabled "Left electric parking brake: summon enabled";
CM_ SG_ 681 EPBL_brakeLight "Left electric parking brake: brake light";
CM_ SG_ 681 EPBL_epbConfigMismatch "Left electric parking brake: epb config mismatch";
CM_ SG_ 681 EPBL_brakeConfirmedPressed "Left electric parking brake: brake confirmed pressed";
CM_ SG_ 681 EPBL_requestUserConfirmation "Left electric parking brake: request user confirmation";
CM_ SG_ 681 EPBL_uiWinchModeMiscBlocking "Reports the expected appearance of system error message on User Interface (UI) winch mode panel.";
CM_ SG_ 681 EPBL_winchModeActive "Left electric parking brake: winch mode active";
CM_ SG_ 681 EPBL_updateMode "Left electric parking brake: update mode";
CM_ SG_ 681 EPBL_winchModePermissive "Left electric parking brake: winch mode permissive";
CM_ SG_ 681 EPBL_winchModePending "Left electric parking brake: winch mode pending";
CM_ SG_ 681 EPBL_cdpRequest "Left electric parking brake: cdp request";
CM_ SG_ 681 EPBL_uiParkAvailable "Reports the expected availability and appearance of the park button on User Interface (UI) safety panel.";
CM_ SG_ 681 EPBL_brakeDiscWipeRequest "Left electric parking brake: brake disc wipe request";
CM_ SG_ 681 EPBL_showUiGearShifter "Left electric parking brake: show ui gear shifter";
CM_ SG_ 681 EPBL_uiWinchModeLvStatus "Reports the expected availability and appearance of Low Voltage (LV) system status on UI winch mode panel.";
CM_ SG_ 681 EPBL_showStalkFaultedOnUi "Left electric parking brake: show stalk faulted on ui";
CM_ SG_ 681 EPBL_espPowerRequest "Left electric parking brake: esp power request";
CM_ SG_ 681 EPBL_okToPark "Left electric parking brake: ok to park";
CM_ SG_ 681 EPBL_hornRequest "Left electric parking brake: horn request";
CM_ SG_ 681 EPBL_winchModeAvailable "Left electric parking brake: winch mode available";
CM_ SG_ 681 EPBL_bothDisconnected "Left electric parking brake: both disconnected";
CM_ SG_ 681 EPBL_blockDrive "Left electric parking brake: block drive";
CM_ SG_ 681 EPBL_statusCounter "Left electric parking brake: status counter";
CM_ SG_ 681 EPBL_statusChecksum "Left electric parking brake: status checksum";
BA_DEF_ BO_ "GenMsgCycleTime" INT 0 3600000;
BA_DEF_ BO_ "GenMsgSendType" ENUM "Cyclic","NotUsed","NotUsed","NotUsed","NotUsed","NotUsed","NotUsed","IfActive","NoMsgSendType","NotUsed";
BA_DEF_ BO_ "VFrameFormat" ENUM "StandardCAN","ExtendedCAN","reserved","J1939PG","reserved","reserved","reserved","reserved","reserved","reserved","reserved","reserved","reserved","reserved","StandardCAN_FD","ExtendedCAN_FD";
BA_DEF_ BO_ "CANFD_BRS" ENUM "0","1";
BA_DEF_ SG_ "SystemSignalLongSymbol" STRING;
BA_DEF_ SG_ "Confidence" ENUM "layout-only","plausible","validated";
BA_DEF_DEF_ "GenMsgCycleTime" 0;
BA_DEF_DEF_ "GenMsgSendType" "NoMsgSendType";
BA_DEF_DEF_ "VFrameFormat" "StandardCAN";
BA_DEF_DEF_ "CANFD_BRS" "1";
BA_DEF_DEF_ "SystemSignalLongSymbol" "";
BA_DEF_DEF_ "Confidence" "layout-only";
BA_ "SystemSignalLongSymbol" SG_ 1480 EPBL_a101_LIPC_externalWatchdogH "EPBL_a101_LIPC_externalWatchdogHeartBeat";
BA_ "SystemSignalLongSymbol" SG_ 1480 EPBL_a115_UI_corianderVehicleCon "EPBL_a115_UI_corianderVehicleControl";
BA_ "SystemSignalLongSymbol" SG_ 1480 EPBL_a117_VEH_intrusionSensorSta "EPBL_a117_VEH_intrusionSensorStatus";
BA_ "SystemSignalLongSymbol" SG_ 1480 EPBL_a118_PARTY_outputPowerStatu "EPBL_a118_PARTY_outputPowerStatus";
BA_ "SystemSignalLongSymbol" SG_ 1480 EPBL_a118_VEH_interNodeResistanc "EPBL_a118_VEH_interNodeResistance";
BA_ "SystemSignalLongSymbol" SG_ 1480 EPBL_a118_PARTY_AP_vehicleState1 "EPBL_a118_PARTY_AP_vehicleState1HzMuxed";
BA_ "SystemSignalLongSymbol" SG_ 1480 EPBL_a118_BDY_AP_vehicleState1Hz "EPBL_a118_BDY_AP_vehicleState1HzMuxed";
BA_ "SystemSignalLongSymbol" SG_ 1480 EPBL_a120_VEH_aggregatedAxleSpee "EPBL_a120_VEH_aggregatedAxleSpeed";
BA_ "SystemSignalLongSymbol" SG_ 1480 EPBL_a120_PARTY_aggregatedAxleSp "EPBL_a120_PARTY_aggregatedAxleSpeed";
BA_ "SystemSignalLongSymbol" SG_ 1480 EPBL_a120_PARTY_stalklessInterfa "EPBL_a120_PARTY_stalklessInterfaces";
BA_ "SystemSignalLongSymbol" SG_ 1480 EPBL_a183_redundantBrakingEnable "EPBL_a183_redundantBrakingEnabled";
BA_ "SystemSignalLongSymbol" SG_ 1480 EPBL_a210_driverLeftForAllSensor "EPBL_a210_driverLeftForAllSensors";
BA_ "SystemSignalLongSymbol" SG_ 1480 EPBL_a210_driverLeftForInactivit "EPBL_a210_driverLeftForInactivity";
BA_ "SystemSignalLongSymbol" SG_ 1480 EPBL_a210_driverIsLeavingSpeedCl "EPBL_a210_driverIsLeavingSpeedClass";
BA_ "SystemSignalLongSymbol" SG_ 1480 EPBL_a210_localDriverIsLeavingAn "EPBL_a210_localDriverIsLeavingAnySpeed";
BA_ "SystemSignalLongSymbol" SG_ 1480 EPBL_a210_remoteDriverIsLeavingA "EPBL_a210_remoteDriverIsLeavingAnySpeed";
BA_ "SystemSignalLongSymbol" SG_ 1480 EPBL_a210_primaryDriverDoorClose "EPBL_a210_primaryDriverDoorClosed";
BA_ "SystemSignalLongSymbol" SG_ 1480 EPBL_a210_secondaryDriverDoorClo "EPBL_a210_secondaryDriverDoorClosed";
BA_ "SystemSignalLongSymbol" SG_ 968 EPBL_a202_remoteEpbConfigIncompa "EPBL_a202_remoteEpbConfigIncompatible";
BA_ "SystemSignalLongSymbol" SG_ 968 EPBL_a210_parkForDriverIsLeaving "EPBL_a210_parkForDriverIsLeavingDebug";
BA_ "SystemSignalLongSymbol" SG_ 968 EPBL_a254_showStalkParkButtonFau "EPBL_a254_showStalkParkButtonFaultOnUi";
BA_ "SystemSignalLongSymbol" SG_ 968 EPBL_a261_winchModeWithoutSteeri "EPBL_a261_winchModeWithoutSteering";
BA_ "SystemSignalLongSymbol" SG_ 968 EPBL_a304_rearSeatControllerEFus "EPBL_a304_rearSeatControllerEFuseTrip";
BA_ "SystemSignalLongSymbol" SG_ 968 EPBL_a353_missingSpeedUnableToPa "EPBL_a353_missingSpeedUnableToPark";
BA_ "SystemSignalLongSymbol" SG_ 968 EPBL_a354_parkedForLowBrakeFluid "EPBL_a354_parkedForLowBrakeFluidMode";
BA_ "SystemSignalLongSymbol" SG_ 968 EPBL_a355_brakeHwAndEpbHwMismatc "EPBL_a355_brakeHwAndEpbHwMismatch";
BA_ "SystemSignalLongSymbol" SG_ 968 EPBL_a356_parkingForStationaryDe "EPBL_a356_parkingForStationaryDetect";
BA_ "SystemSignalLongSymbol" SG_ 968 EPBL_a358_brakesTooHotForSlopeWi "EPBL_a358_brakesTooHotForSlopeWithOnlyOneEpb";
BA_ "SystemSignalLongSymbol" SG_ 968 EPBL_a362_ibstPressedEspNotPress "EPBL_a362_ibstPressedEspNotPressedMismatch";
BA_ "SystemSignalLongSymbol" SG_ 968 EPBL_a363_ibstNotPressedEspPress "EPBL_a363_ibstNotPressedEspPressedMismatch";
BA_ "SystemSignalLongSymbol" SG_ 968 EPBL_a364_espMasterCylCompOverTh "EPBL_a364_espMasterCylCompOverThreshold";
BA_ "SystemSignalLongSymbol" SG_ 968 EPBL_a365_TooSteepToParkWithTrai "EPBL_a365_TooSteepToParkWithTrailerWarning";
BA_ "SystemSignalLongSymbol" SG_ 968 EPBL_a366_TooSteepToParkWithTrai "EPBL_a366_TooSteepToParkWithTrailerUnSecEnv";
BA_ "Confidence" SG_ 1992 EPBL_infoBuildType 1;
BA_ "Confidence" SG_ 648 EPBL_unitStatus 1;
BA_ "Confidence" SG_ 648 EPBL_unitFaultStatus 1;
BA_ "Confidence" SG_ 648 EPBL_summonState 1;
BA_ "Confidence" SG_ 648 EPBL_csmFaultReason 1;
BA_ "Confidence" SG_ 648 EPBL_esmOperationTrigger 1;
BA_ "Confidence" SG_ 648 EPBL_summonFaultReason 1;
BA_ "Confidence" SG_ 648 EPBL_localCdpState 1;
BA_ "Confidence" SG_ 648 EPBL_chimeRequestLocal 1;
BA_ "Confidence" SG_ 648 EPBL_telltaleLocal 1;
BA_ "SystemSignalLongSymbol" SG_ 648 EPBL_driverIsLeavingAnySpeedLoca "EPBL_driverIsLeavingAnySpeedLocal";
BA_ "Confidence" SG_ 648 EPBL_internalCDPRequest 1;
BA_ "Confidence" SG_ 648 EPBL_esmSpeedClass 1;
BA_ "Confidence" SG_ 648 EPBL_learnedEpbConfig 1;
BA_ "Confidence" SG_ 743 EPBL_frontSeatCushionFanCur 1;
BA_ "Confidence" SG_ 743 EPBL_frontSeatBackrestFanCur 1;
BA_ "Confidence" SG_ 743 EPBL_frontSeatCushionFanDuty 1;
BA_ "Confidence" SG_ 743 EPBL_frontSeatBackrestFanDuty 1;
BA_ "Confidence" SG_ 681 EPBL_systemStatus 1;
BA_ "Confidence" SG_ 681 EPBL_freeRollModeStatus 1;
BA_ "Confidence" SG_ 681 EPBL_chimeRequest 1;
BA_ "Confidence" SG_ 681 EPBL_telltale 1;
BA_ "SystemSignalLongSymbol" SG_ 681 EPBL_contactorCycleNotNeededForW "EPBL_contactorCycleNotNeededForWinchEntry";
BA_ "Confidence" SG_ 681 EPBL_uiWinchModeMiscBlocking 1;
BA_ "Confidence" SG_ 681 EPBL_cdpRequest 1;
BA_ "Confidence" SG_ 681 EPBL_uiParkAvailable 1;
BA_ "Confidence" SG_ 681 EPBL_brakeDiscWipeRequest 1;
BA_ "Confidence" SG_ 681 EPBL_uiWinchModeLvStatus 1;
VAL_ 1992 EPBL_infoBuildType 4 "INFO_MFG_BUILD" 3 "INFO_TRACEABLE_CI_BUILD" 2 "INFO_LOCAL_BUILD" 1 "INFO_PLATFORM_BUILD" 0 "INFO_UNKNOWN_BUILD" ;
VAL_ 648 EPBL_unitStatus 23 "EPB_STATUS_COUNT" 22 "EPB_STATUS_AUTONOMY_OPEN" 21 "EPB_STATUS_FREE_ROLL_MODE" 20 "EPB_STATUS_DYNAMIC_PARKING" 19 "EPB_STATUS_EXTERNAL_PARKING" 18 "EPB_STATUS_RELEASING_FOR_EXTERNAL_PARK" 17 "EPB_STATUS_EXTERNAL_DYNAMIC" 16 "EPB_STATUS_SUMMON_PARKING" 15 "EPB_STATUS_SUMMON_RELEASING" 14 "EPB_STATUS_SUMMON" 13 "EPB_STATUS_WINCHMODE_PENDING" 12 "EPB_STATUS_PARK_PENDING" 11 "EPB_STATUS_SERVICE_RELEASING" 10 "EPB_STATUS_RELEASING" 9 "EPB_STATUS_DYNAMIC_APPLYING" 8 "EPB_STATUS_PARKING" 7 "EPB_STATUS_WINCHMODE_RELEASING" 6 "EPB_STATUS_WINCHMODE" 5 "EPB_STATUS_SERVICE" 4 "EPB_STATUS_START" 3 "EPB_STATUS_PARK" 2 "EPB_STATUS_DYNAMIC" 1 "EPB_STATUS_OPEN" 0 "EPB_STATUS_UNKNOWN" ;
VAL_ 648 EPBL_unitFaultStatus 3 "EPB_STATUS_FAULT_IDLE" 2 "EPB_STATUS_FAULT" 1 "EPB_STATUS_RETRY" 0 "EPB_STATUS_NOMINAL" ;
VAL_ 648 EPBL_summonState 6 "EPB_SUMMON_UNAVAILABLE" 5 "EPB_SUMMON_FAULT" 4 "EPB_SUMMON_COMPLETE" 3 "EPB_SUMMON_ACTIVE" 2 "EPB_SUMMON_ARMED" 1 "EPB_SUMMON_IDLE" 0 "EPB_SUMMON_INIT" ;
VAL_ 648 EPBL_csmFaultReason 23 "CSM_FAULT_REMOTE_MIA" 22 "CSM_FAULT_NVM_MISMATCH" 21 "CSM_FAULT_EPBM_MIA" 20 "CSM_FAULT_MOTOR_NOT_READY" 19 "CSM_FAULT_MOTOR_ACTIVE_FAULT" 18 "CSM_FAULT_MOTOR_IDLE_FAULT" 17 "CSM_FAULT_TIMEOUT_EPBM_START" 16 "CSM_FAULT_TIMEOUT_NO_RAMP" 15 "CSM_FAULT_TIMEOUT_EPBM_CUTOFF" 14 "CSM_FAULT_TIMEOUT_RELEASE_COMPLETE" 13 "CSM_FAULT_TIMEOUT_RELEASE_NO_LOAD" 12 "CSM_FAULT_TIMEOUT_RELEASE_WAIT_FOR_ENDSTOP" 11 "CSM_FAULT_TIMEOUT_RELEASE_INRUSH" 10 "CSM_FAULT_TIMEOUT_EPBM_WAIT_FOR_CLAMP" 9 "CSM_FAULT_TIMEOUT_EPB_WAIT_FOR_CLAMP" 8 "CSM_FAULT_TIMEOUT_APPLY_INRUSH" 7 "CSM_FAULT_TIMEOUT_APPLY_COMPLETE" 6 "CSM_FAULT_RELEASE_BLOCKED" 5 "CSM_FAULT_APPLY_BLOCKED" 4 "CSM_FAULT_TIMEOUT_CALIBRATE" 3 "CSM_FAULT_STATE_MISMATCH" 2 "CSM_FAULT_EPBM_FAULTED" 1 "CSM_FAULT_EPBM_DISABLED" 0 "CSM_FAULT_NONE" ;
VAL_ 648 EPBL_esmOperationTrigger 50 "EPB_TRIGGER_ACTIVE_DECEL_DAS_STATIC" 49 "EPB_TRIGGER_ACTIVE_DECEL_CDP_DOWN" 48 "EPB_TRIGGER_AP_IS_LEAVING" 47 "EPB_TRIGGER_RECOVERY_PARK" 46 "EPB_TRIGGER_SPEED_SOURCES_LOST" 45 "EPB_TRIGGER_ACTIVE_DECEL_OKTOPARK" 44 "EPB_TRIGGER_ACTIVE_DECEL_FAST" 43 "EPB_TRIGGER_STEERING_ACTIVE_DECEL" 42 "EPB_TRIGGER_LV_ACTIVE_DECEL" 41 "EPB_TRIGGER_CDP_PANIC_MODE_READY" 40 "EPB_TRIGGER_CDP_PANIC_MODE_TIMEOUT" 39 "EPB_TRIGGER_DI_PARK" 38 "EPB_TRIGGER_FREE_ROLL_PARK_FOR_HANDLE_PULLED" 37 "EPB_TRIGGER_LOW_BRAKE_FLUID_MODE_DYNAMIC" 36 "EPB_TRIGGER_LOW_BRAKE_FLUID_MODE_DYNAMIC_PARK" 35 "EPB_TRIGGER_LOW_BRAKE_FLUID_MODE_PARK" 34 "EPB_TRIGGER_STATIONARY_DETECT" 33 "EPB_TRIGGER_TOUCHSCREEN_INVALID" 32 "EPB_TRIGGER_UI_DOOR_OPEN_REQUEST" 31 "EPB_TRIGGER_AUTOPARK_END" 30 "EPB_TRIGGER_DRIVER_IS_LEAVING" 29 "EPB_TRIGGER_SYSTEM_APPLY" 28 "EPB_TRIGGER_ACCELERATION" 27 "EPB_TRIGGER_EPBM_DISQUALIFIED" 26 "EPB_TRIGGER_DISQUALIFIED" 25 "EPB_TRIGGER_SUMMON_FAULT" 24 "EPB_TRIGGER_FAULT" 23 "EPB_TRIGGER_SUMMON_COMPLETE" 22 "EPB_TRIGGER_REAPPLY" 21 "EPB_TRIGGER_SAVESTATE_ON_BOOT" 20 "EPB_TRIGGER_TIMEOUT" 19 "EPB_TRIGGER_SPEED_FAST" 18 "EPB_TRIGGER_SPEED_OKAYTOPARK" 17 "EPB_TRIGGER_SPEED_STOPPED" 16 "EPB_TRIGGER_USER_CANCEL" 15 "EPB_TRIGGER_USER_CONFIRMED" 14 "EPB_TRIGGER_DIAG_EXIT" 13 "EPB_TRIGGER_DIAG_OPEN" 12 "EPB_TRIGGER_DIAG_CLOSE" 11 "EPB_TRIGGER_SERVICE" 10 "EPB_TRIGGER_WINCHMODE_UNAVAILABLE" 9 "EPB_TRIGGER_WINCHMODE_ENTER" 8 "EPB_TRIGGER_WINCHMODE_EXIT" 7 "EPB_TRIGGER_TOUCHSCREEN" 6 "EPB_TRIGGER_DI_UNPARK" 5 "EPB_TRIGGER_ACTIVE_PARK_REQUEST" 4 "EPB_TRIGGER_PBUTTON_RELEASED" 3 "EPB_TRIGGER_PBUTTON_PRESSED_UNKNOWN" 2 "EPB_TRIGGER_PBUTTON_PRESSED_FAST" 1 "EPB_TRIGGER_PBUTTON_PRESSED_OKTOPARK" 0 "EPB_TRIGGER_PBUTTON_PRESSED_STOPPED" ;
VAL_ 648 EPBL_summonFaultReason 30 "EPB_SUMMONFAULT_MONITOR_TYPE_UNKNOWN" 29 "EPB_SUMMONFAULT_AP_MONITOR" 28 "EPB_SUMMONFAULT_REMOTE_DID_NOT_START" 27 "EPB_SUMMONFAULT_INVALID_REMOTE_STATE" 26 "EPB_SUMMONFAULT_START_IN_UNAVAILABLE" 25 "EPB_SUMMONFAULT_REMOTE_UNIT_FAULTED" 24 "EPB_SUMMONFAULT_LOCAL_UNIT_FAULTED" 23 "EPB_SUMMONFAULT_REMOTE_SUMMON_FAULTED" 22 "EPB_SUMMONFAULT_EPBREMOTE_MIA" 21 "EPB_SUMMONFAULT_PASSIVE_REQUEST" 20 "EPB_SUMMONFAULT_DI_STATE_INVALID" 19 "EPB_SUMMONFAULT_EPB_FAULT" 18 "EPB_SUMMONFAULT_MISMATCH" 17 "EPB_SUMMONFAULT_OOC" 16 "EPB_SUMMONFAULT_PM_REQUEST" 15 "EPB_SUMMONFAULT_PM_MIA" 14 "EPB_SUMMONFAULT_PARK_MIA" 13 "EPB_SUMMONFAULT_EXTERNAL" 12 "EPB_SUMMONFAULT_SPEED" 11 "EPB_SUMMONFAULT_EPBM_REQUEST" 10 "EPB_SUMMONFAULT_EAC_NOT_ALLOWED" 9 "EPB_SUMMONFAULT_VEH_CAN_FAULT" 8 "EPB_SUMMONFAULT_ESP_FAULT" 7 "EPB_SUMMONFAULT_DAS_FAULT" 6 "EPB_SUMMONFAULT_DI_APC_FAULT" 5 "EPB_SUMMONFAULT_DI_FAULT" 4 "EPB_SUMMONFAULT_EPBM_MIA" 3 "EPB_SUMMONFAULT_ESP_MIA" 2 "EPB_SUMMONFAULT_DAS_MIA" 1 "EPB_SUMMONFAULT_DI_MIA" 0 "EPB_SUMMONFAULT_NONE" ;
VAL_ 648 EPBL_localCdpState 2 "EPB_CDP_STATE_FAULT" 1 "EPB_CDP_STATE_VALID" 0 "EPB_CDP_STATE_UNKNOWN" ;
VAL_ 648 EPBL_chimeRequestLocal 4 "EPB_CHIME_REQUEST_ACTIVE_DECEL" 3 "EPB_CHIME_REQUEST_ABOUT_TO_ACTIVE_DECEL" 2 "EPB_CHIME_REQUEST_GPO" 1 "EPB_CHIME_REQUEST_GENERAL" 0 "EPB_CHIME_REQUEST_NONE" ;
VAL_ 648 EPBL_telltaleLocal 7 "EPB_TELLTALE_SNA" 4 "EPB_TELLTALE_LAMP_RED_FLASH" 3 "EPB_TELLTALE_LAMP_AMBER_ON" 2 "EPB_TELLTALE_LAMP_RED_ON" 1 "EPB_TELLTALE_LAMP_RED_PARKED" 0 "EPB_TELLTALE_LAMP_OFF" ;
VAL_ 648 EPBL_internalCDPRequest 1 "EPB_CDP_REQUESTED" 0 "EPB_CDP_NOT_REQUESTED" ;
VAL_ 648 EPBL_esmSpeedClass 4 "ESM_SPEED_CLASS_UNKNOWN" 3 "ESM_SPEED_CLASS_FAST" 2 "ESM_SPEED_CLASS_USER_APPLY_OK" 1 "ESM_SPEED_CLASS_SYSTEM_APPLY_OK" 0 "ESM_SPEED_CLASS_STOPPED" ;
VAL_ 648 EPBL_learnedEpbConfig 11 "EPB_CONFIG_CT_MANDO" 10 "EPB_CONFIG_MODEL3_ZF" 9 "EPB_CONFIG_MODELS_CERAMIC" 8 "EPB_CONFIG_MODELY_PERFORMANCE_V2" 7 "EPB_CONFIG_MODEL3_PERFORMANCE_V2" 6 "EPB_CONFIG_MODELX_BASE" 5 "EPB_CONFIG_MODELY_PERFORMANCE" 4 "EPB_CONFIG_MODELY_BASE" 3 "EPB_CONFIG_MODELS_BASE" 2 "EPB_CONFIG_MODEL3_PERFORMANCE" 1 "EPB_CONFIG_MODEL3_BASE" 0 "EPB_CONFIG_UNKNOWN" ;
VAL_ 681 EPBL_systemStatus 8 "EPB_VEHICLE_STATUS_MISMATCH" 7 "EPB_VEHICLE_STATUS_FAULT_SECURE" 6 "EPB_VEHICLE_STATUS_FAULT" 5 "EPB_VEHICLE_STATUS_RELEASING" 4 "EPB_VEHICLE_STATUS_PARKING" 3 "EPB_VEHICLE_STATUS_DYNAMIC" 2 "EPB_VEHICLE_STATUS_PARKED" 1 "EPB_VEHICLE_STATUS_RELEASED" 0 "EPB_VEHICLE_STATUS_UNKNOWN" ;
VAL_ 681 EPBL_freeRollModeStatus 2 "EPB_FREE_ROLL_MODE_ENABLED" 1 "EPB_FREE_ROLL_MODE_AVAILABLE" 0 "EPB_FREE_ROLL_MODE_UNAVAILABLE" ;
VAL_ 681 EPBL_chimeRequest 4 "EPB_CHIME_REQUEST_ACTIVE_DECEL" 3 "EPB_CHIME_REQUEST_ABOUT_TO_ACTIVE_DECEL" 2 "EPB_CHIME_REQUEST_GPO" 1 "EPB_CHIME_REQUEST_GENERAL" 0 "EPB_CHIME_REQUEST_NONE" ;
VAL_ 681 EPBL_telltale 7 "EPB_TELLTALE_SNA" 4 "EPB_TELLTALE_LAMP_RED_FLASH" 3 "EPB_TELLTALE_LAMP_AMBER_ON" 2 "EPB_TELLTALE_LAMP_RED_ON" 1 "EPB_TELLTALE_LAMP_RED_PARKED" 0 "EPB_TELLTALE_LAMP_OFF" ;
VAL_ 681 EPBL_cdpRequest 1 "EPB_CDP_REQUESTED" 0 "EPB_CDP_NOT_REQUESTED" ;
VAL_ 681 EPBL_uiParkAvailable 2 "EPB_AVAIL_REAPPLIED" 1 "EPB_AVAIL_AVAILABLE" 0 "EPB_AVAIL_NOT_AVAILABLE" ;
VAL_ 681 EPBL_brakeDiscWipeRequest 3 "EPB_BRAKEDISCWIPE_REQUEST_SNA" 2 "EPB_BRAKEDISCWIPE_REQUEST_STRONG" 1 "EPB_BRAKEDISCWIPE_REQUEST_LIGHT" 0 "EPB_BRAKEDISCWIPE_REQUEST_NONE" ;
VAL_ 681 EPBL_uiWinchModeLvStatus 3 "EPB_LV_OK" 2 "EPB_LV_BLOCKED_TIMER_RUNNING" 1 "EPB_LV_BLOCKED_INPUT_VOLTAGE_LOW" 0 "EPB_LV_BLOCKED_BATTERY" ;
